VERSION ""

NS_ :

BS_:

BU_: WPC2 PSB SHVU_RR vHS_B2 FCS EMCU SLB GW_APSU GW_DLBCU ARS RCM CGW_CCU vDummy_HS_B GW_RLPSU ATS RLHV SGU PFSU GW_RRPSU ALBCU DSAU SWRC SHVU_FR RCS GW_DPSU BLTN_CAM SCM OHCL RWPC RRHV WPC HOD ASAU

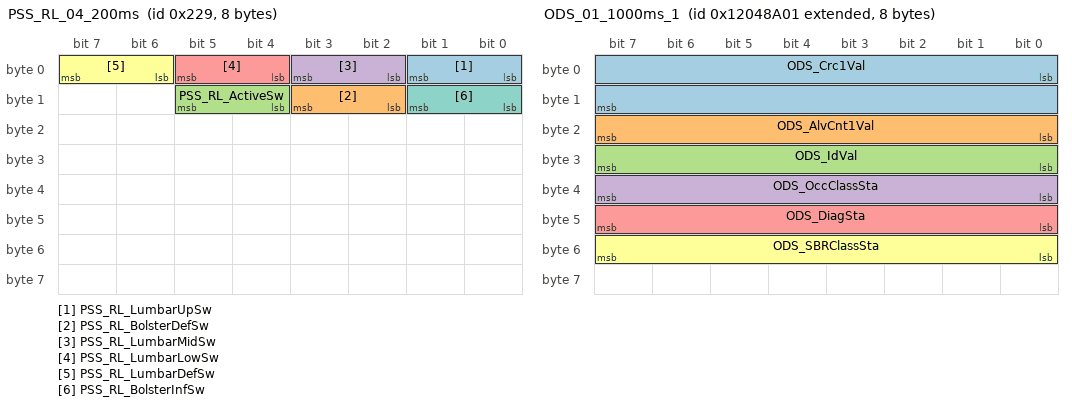
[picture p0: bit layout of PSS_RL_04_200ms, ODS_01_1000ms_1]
BO_ 553 PSS_RL_04_200ms: 8 GW_RLPSU
 SG_ PSS_RL_LumbarUpSw : 0|2@1+ (1,0) [0|0] ""  DSAU,GW_DLBCU,CGW_CCU
 SG_ PSS_RL_BolsterDefSw : 10|2@1+ (1,0) [0|0] ""  DSAU,GW_DLBCU,CGW_CCU
 SG_ PSS_RL_ActiveSw : 12|2@1+ (1,0) [0|0] ""  DSAU,GW_DLBCU,CGW_CCU
 SG_ PSS_RL_LumbarMidSw : 2|2@1+ (1,0) [0|0] ""  DSAU,GW_DLBCU,CGW_CCU
 SG_ PSS_RL_LumbarLowSw : 4|2@1+ (1,0) [0|0] ""  DSAU,GW_DLBCU,CGW_CCU
 SG_ PSS_RL_LumbarDefSw : 6|2@1+ (1,0) [0|0] ""  DSAU,GW_DLBCU,CGW_CCU
 SG_ PSS_RL_BolsterInfSw : 8|2@1+ (1,0) [0|0] ""  DSAU,GW_DLBCU,CGW_CCU

BO_ 2449771009 ODS_01_1000ms_1: 8 CGW_CCU
 SG_ ODS_Crc1Val : 0|16@1+ (1,0) [0|0] ""  Vector__XXX
 SG_ ODS_AlvCnt1Val : 16|8@1+ (1,0) [0|0] ""  Vector__XXX
 SG_ ODS_IdVal : 24|8@1+ (1,0) [0|0] ""  Vector__XXX
 SG_ ODS_OccClassSta : 32|8@1+ (1,0) [0|0] ""  ATS,GW_APSU,GW_DPSU
 SG_ ODS_DiagSta : 40|8@1+ (1,0) [0|0] ""  Vector__XXX
 SG_ ODS_SBRClassSta : 48|8@1+ (1,0) [0|0] ""  Vector__XXX

BO_ 2449771010 ODS_01_1000ms_2: 8 CGW_CCU

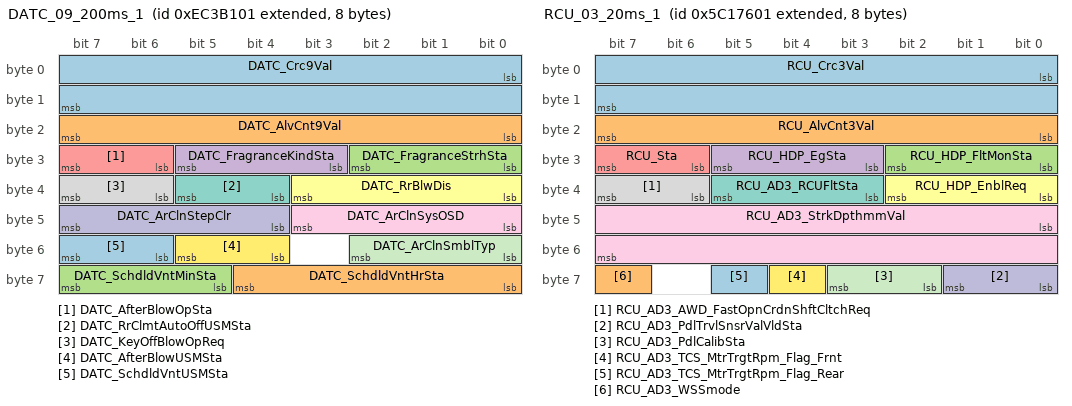
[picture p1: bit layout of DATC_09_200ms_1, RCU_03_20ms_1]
BO_ 2395189505 DATC_09_200ms_1: 8 CGW_CCU
 SG_ DATC_Crc9Val : 0|16@1+ (1,0) [0|0] ""  Vector__XXX
 SG_ DATC_AlvCnt9Val : 16|8@1+ (1,0) [0|0] ""  Vector__XXX
 SG_ DATC_FragranceStrhSta : 24|3@1+ (1,0) [0|0] ""  ATS
 SG_ DATC_FragranceKindSta : 27|3@1+ (1,0) [0|0] ""  ATS
 SG_ DATC_AfterBlowOpSta : 30|2@1+ (1,0) [0|0] ""  Vector__XXX
 SG_ DATC_RrBlwDis : 32|4@1+ (1,0) [0|0] ""  ATS
 SG_ DATC_RrClmtAutoOffUSMSta : 36|2@1+ (1,0) [0|0] ""  Vector__XXX
 SG_ DATC_KeyOffBlowOpReq : 38|2@1+ (1,0) [0|0] ""  Vector__XXX
 SG_ DATC_ArClnSysOSD : 40|4@1+ (1,0) [0|0] ""  Vector__XXX
 SG_ DATC_ArClnStepClr : 44|4@1+ (1,0) [0|0] ""  ATS
 SG_ DATC_ArClnSmblTyp : 48|3@1+ (1,0) [0|0] ""  ATS
 SG_ DATC_AfterBlowUSMSta : 52|2@1+ (1,0) [0|0] ""  Vector__XXX
 SG_ DATC_SchdldVntUSMSta : 54|2@1+ (1,0) [0|0] ""  Vector__XXX
 SG_ DATC_SchdldVntHrSta : 56|5@1+ (1,0) [0|0] ""  Vector__XXX
 SG_ DATC_SchdldVntMinSta : 61|3@1+ (1,0) [0|0] ""  Vector__XXX

BO_ 2244048387 RCU_03_20ms_3: 8 CGW_CCU
 SG_ RCU_AD3_SCC_TqIntrvntnVal : 0|8@1+ (0.390625,0) [0|0] "%"  Vector__XXX
 SG_ RCU_AD3_TCS_TqFlag : 19|1@1+ (1,0) [0|0] ""  Vector__XXX
 SG_ RCU_AD3_TCS_Sta : 20|4@1+ (1,0) [0|0] ""  Vector__XXX
 SG_ RCU_AD3_VehAccelVal : 24|11@1+ (0.01,-10.23) [0|0] "m/s^2"  Vector__XXX
 SG_ RCU_AD3_MSR_TqFlag : 35|1@1+ (1,0) [0|0] ""  Vector__XXX
 SG_ RCU_AD3_LDM_Sta : 36|2@1+ (1,0) [0|0] ""  Vector__XXX
 SG_ RCU_AD3_ECD_ActvSta : 38|2@1+ (1,0) [0|0] ""  Vector__XXX
 SG_ RCU_AD3_MSR_FuncReq : 40|2@1+ (1,0) [0|0] ""  Vector__XXX
 SG_ RCU_AD3_TCS_Req : 42|2@1+ (1,0) [0|0] ""  Vector__XXX
 SG_ RCU_AD3_TCS_LmpSta : 44|2@1+ (1,0) [0|0] ""  Vector__XXX
 SG_ RCU_AD3_SCC_TqReq : 46|2@1+ (1,0) [0|0] ""  Vector__XXX
 SG_ RCU_AD3_StdStillVal : 48|2@1+ (1,0) [0|0] ""  Vector__XXX
 SG_ RCU_AD3_SCC_ReqLimSta : 50|2@1+ (1,0) [0|0] ""  Vector__XXX
 SG_ RCU_AD3_SCC_OptTyp : 52|2@1+ (1,0) [0|0] ""  Vector__XXX
 SG_ RCU_AD3_SCC_EnblReq : 54|2@1+ (1,0) [0|0] ""  Vector__XXX
 SG_ RCU_AD3_FCA_EquipSta : 56|2@1+ (1,0) [0|0] ""  Vector__XXX
 SG_ RCU_AD3_FCA_ActvSta : 58|2@1+ (1,0) [0|0] ""  Vector__XXX
 SG_ RCU_AD3_DclEnblReq : 60|2@1+ (1,0) [0|0] ""  Vector__XXX
 SG_ RCU_AD3_DBS_ActvSta : 62|2@1+ (1,0) [0|0] ""  Vector__XXX
 SG_ RCU_AD3_AccelBasisVal : 8|11@1+ (0.01,-10.23) [0|0] "m/s^2"  Vector__XXX

BO_ 2244048386 RCU_03_20ms_2: 8 CGW_CCU
 SG_ RCU_AD3_Wss2FlFltSta : 0|2@1+ (1,0) [0|0] ""  Vector__XXX
 SG_ RCU_AD3_DiagSta : 10|2@1+ (1,0) [0|0] ""  Vector__XXX
 SG_ RCU_AD3_operation : 12|2@1+ (1,0) [0|0] ""  Vector__XXX
 SG_ RCU_AD3_PrsrValVldSta : 14|2@1+ (1,0) [0|0] ""  Vector__XXX
 SG_ RCU_AD3_PrsrVal : 16|16@1- (0.01,-30) [0|0] "Bar"  Vector__XXX
 SG_ RCU_AD3_Wss2FrFltSta : 2|2@1+ (1,0) [0|0] ""  Vector__XXX
 SG_ RCU_AD3_ABS_DfctvSta : 32|2@1+ (1,0) [0|0] ""  Vector__XXX
 SG_ RCU_AD3_ABS_ActvSta : 34|2@1+ (1,0) [0|0] ""  Vector__XXX
 SG_ RCU_AD3_BBC_DfctvSta : 36|2@1+ (1,0) [0|0] ""  Vector__XXX
 SG_ RCU_AD3_BBC_ActvSta : 38|2@1+ (1,0) [0|0] ""  Vector__XXX
 SG_ RCU_AD3_Wss2RlFltSta : 4|2@1+ (1,0) [0|0] ""  Vector__XXX
 SG_ RCU_AD3_BrkLtActSta : 40|2@1+ (1,0) [0|0] ""  Vector__XXX
 SG_ RCU_AD3_DrvOvrdSta : 42|2@1+ (1,0) [0|0] ""  Vector__XXX
 SG_ RCU_AD3_PrkBrkActvSta : 44|2@1+ (1,0) [0|0] ""  Vector__XXX
 SG_ RCU_AD3_FCA_AvlblSta : 46|2@1+ (1,0) [0|0] ""  Vector__XXX
 SG_ RCU_AD3_MSR_TqIntrvntnVal : 48|8@1+ (0.390625,0) [0|0] "%"  Vector__XXX
 SG_ RCU_AD3_TCS_TqIntrvntnVal : 56|8@1+ (0.390625,0) [0|0] "%"  Vector__XXX
 SG_ RCU_AD3_Wss2RrFltSta : 6|2@1+ (1,0) [0|0] ""  Vector__XXX
 SG_ RCU_AD3_SrvLmpDis : 8|2@1+ (1,0) [0|0] ""  Vector__XXX

BO_ 2244048385 RCU_03_20ms_1: 8 CGW_CCU
 SG_ RCU_Crc3Val : 0|16@1+ (1,0) [0|0] ""  Vector__XXX
 SG_ RCU_AlvCnt3Val : 16|8@1+ (1,0) [0|0] ""  Vector__XXX
 SG_ RCU_HDP_FltMonSta : 24|3@1+ (1,0) [0|0] ""  Vector__XXX
 SG_ RCU_HDP_EgSta : 27|3@1+ (1,0) [0|0] ""  PSB
 SG_ RCU_Sta : 30|2@1+ (1,0) [0|0] ""  Vector__XXX
 SG_ RCU_HDP_EnblReq : 32|3@1+ (1,0) [0|0] ""  Vector__XXX
 SG_ RCU_AD3_RCUFltSta : 35|3@1+ (1,0) [0|0] ""  Vector__XXX
 SG_ RCU_AD3_AWD_FastOpnCrdnShftCltchReq : 38|2@1+ (1,0) [0|0] ""  Vector__XXX
 SG_ RCU_AD3_StrkDpthmmVal : 40|16@1- (0.1,-40) [0|0] "mm"  Vector__XXX
 SG_ RCU_AD3_PdlTrvlSnsrValVldSta : 56|2@1+ (1,0) [0|0] ""  Vector__XXX
 SG_ RCU_AD3_PdlCalibSta : 58|2@1+ (1,0) [0|0] ""  Vector__XXX
 SG_ RCU_AD3_TCS_MtrTrgtRpm_Flag_Frnt : 60|1@1+ (1,0) [0|0] ""  Vector__XXX
 SG_ RCU_AD3_TCS_MtrTrgtRpm_Flag_Rear : 61|1@1+ (1,0) [0|0] ""  Vector__XXX
 SG_ RCU_AD3_WSSmode : 63|1@1+ (1,0) [0|0] ""  Vector__XXX

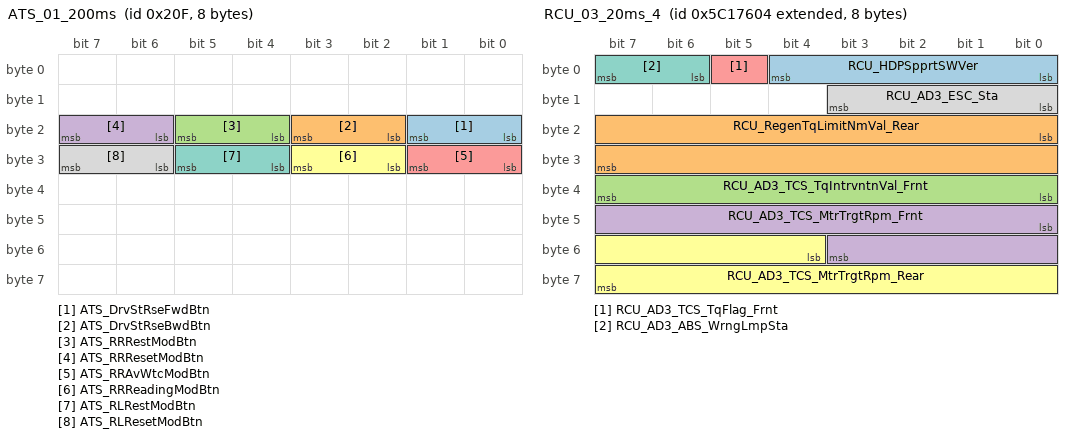
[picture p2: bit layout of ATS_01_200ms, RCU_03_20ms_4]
BO_ 527 ATS_01_200ms: 8 ATS
 SG_ ATS_DrvStRseFwdBtn : 16|2@1+ (1,0) [0|0] ""  Vector__XXX
 SG_ ATS_DrvStRseBwdBtn : 18|2@1+ (1,0) [0|0] ""  Vector__XXX
 SG_ ATS_RRRestModBtn : 20|2@1+ (1,0) [0|0] ""  Vector__XXX
 SG_ ATS_RRResetModBtn : 22|2@1+ (1,0) [0|0] ""  Vector__XXX
 SG_ ATS_RRAvWtcModBtn : 24|2@1+ (1,0) [0|0] ""  Vector__XXX
 SG_ ATS_RRReadingModBtn : 26|2@1+ (1,0) [0|0] ""  Vector__XXX
 SG_ ATS_RLRestModBtn : 28|2@1+ (1,0) [0|0] ""  Vector__XXX
 SG_ ATS_RLResetModBtn : 30|2@1+ (1,0) [0|0] ""  Vector__XXX

BO_ 2244048388 RCU_03_20ms_4: 8 CGW_CCU
 SG_ RCU_HDPSpprtSWVer : 0|5@1+ (1,0) [0|0] ""  Vector__XXX
 SG_ RCU_RegenTqLimitNmVal_Rear : 16|16@1+ (1,0) [0|0] "Nm"  Vector__XXX
 SG_ RCU_AD3_TCS_TqIntrvntnVal_Frnt : 32|8@1+ (0.390625,0) [0|0] "%"  Vector__XXX
 SG_ RCU_AD3_TCS_MtrTrgtRpm_Frnt : 40|12@1+ (8,0) [0|0] "rpm"  Vector__XXX
 SG_ RCU_AD3_TCS_TqFlag_Frnt : 5|1@1+ (1,0) [0|0] ""  Vector__XXX
 SG_ RCU_AD3_TCS_MtrTrgtRpm_Rear : 52|12@1+ (8,0) [0|0] "rpm"  Vector__XXX
 SG_ RCU_AD3_ABS_WrngLmpSta : 6|2@1+ (1,0) [0|0] ""  Vector__XXX
 SG_ RCU_AD3_ESC_Sta : 8|4@1+ (1,0) [0|0] ""  Vector__XXX

BO_ 1616 MKBD_HU_E_01: 8 CGW_CCU
 SG_ MKBD_IllumiState : 48|2@1+ (1,0) [0|0] ""  Vector__XXX
 SG_ MKBD_SeatKeySet : 50|2@1+ (1,0) [0|0] ""  GW_APSU,GW_DPSU,SHVU_FR

BO_ 543 ATS_02_200ms: 8 ATS
 SG_ ATS_AstStSldFwdBtn : 16|2@1+ (1,0) [0|0] ""  Vector__XXX
 SG_ ATS_AstStSldBwdBtn : 18|2@1+ (1,0) [0|0] ""  Vector__XXX
 SG_ ATS_AstStRclFwdBtn : 20|2@1+ (1,0) [0|0] ""  Vector__XXX
 SG_ ATS_AstStRclBwdBtn : 22|2@1+ (1,0) [0|0] ""  Vector__XXX
 SG_ ATS_AstStHgtUpBtn : 28|2@1+ (1,0) [0|0] ""  Vector__XXX
 SG_ ATS_AstStHgtDnBtn : 30|2@1+ (1,0) [0|0] ""  Vector__XXX
 SG_ ATS_AstStHRestUpBtn : 40|2@1+ (1,0) [0|0] ""  Vector__XXX
 SG_ ATS_AstStHRestDnBtn : 42|2@1+ (1,0) [0|0] ""  Vector__XXX
 SG_ ATS_AstStHRestFwdBtn : 44|2@1+ (1,0) [0|0] ""  Vector__XXX
 SG_ ATS_AstStHRestBwdBtn : 46|2@1+ (1,0) [0|0] ""  Vector__XXX
 SG_ ATS_AstStHRestFldBtn : 48|2@1+ (1,0) [0|0] ""  Vector__XXX
 SG_ ATS_AstStHRestUnFldBtn : 50|2@1+ (1,0) [0|0] ""  Vector__XXX
 SG_ ATS_AstStRseFwdBtn : 52|2@1+ (1,0) [0|0] ""  Vector__XXX
 SG_ ATS_AstStRseBwdBtn : 54|2@1+ (1,0) [0|0] ""  Vector__XXX
 SG_ ATS_AstStFRestFldBtn : 56|2@1+ (1,0) [0|0] ""  Vector__XXX
 SG_ ATS_AstStFRestUnFldBtn : 58|2@1+ (1,0) [0|0] ""  Vector__XXX
 SG_ ATS_AstTltUpBtn : 60|2@1+ (1,0) [0|0] ""  Vector__XXX
 SG_ ATS_AstTltDnBtn : 62|2@1+ (1,0) [0|0] ""  Vector__XXX

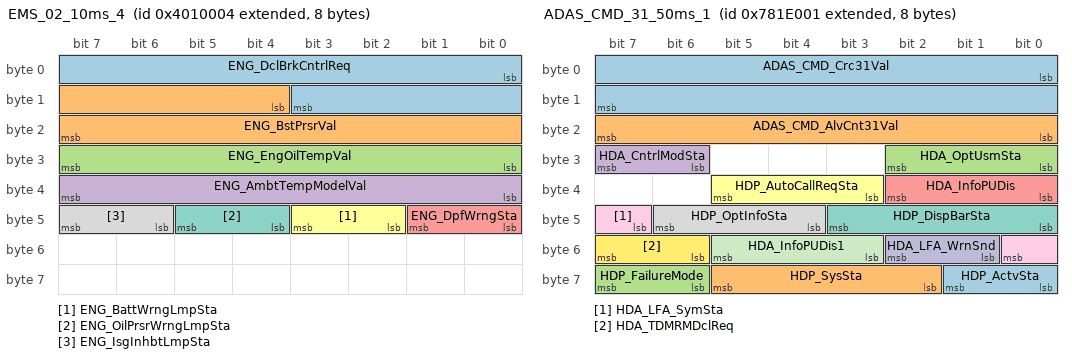
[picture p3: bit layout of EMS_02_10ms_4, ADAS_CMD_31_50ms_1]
BO_ 2214658052 EMS_02_10ms_4: 8 CGW_CCU
 SG_ ENG_DclBrkCntrlReq : 0|12@1+ (0.001,-4.094) [0|0] "m/s^2"  Vector__XXX
 SG_ ENG_BstPrsrVal : 12|12@1+ (1.322,0) [0|0] "hPa"  Vector__XXX
 SG_ ENG_EngOilTempVal : 24|8@1+ (0.75,-40) [0|0] "¡É"  Vector__XXX
 SG_ ENG_AmbtTempModelVal : 32|8@1+ (0.5,-41) [0|0] "¡É"  Vector__XXX
 SG_ ENG_DpfWrngSta : 40|2@1+ (1,0) [0|0] ""  Vector__XXX
 SG_ ENG_BattWrngLmpSta : 42|2@1+ (1,0) [0|0] ""  Vector__XXX
 SG_ ENG_OilPrsrWrngLmpSta : 44|2@1+ (1,0) [0|0] ""  Vector__XXX
 SG_ ENG_IsgInhbtLmpSta : 46|2@1+ (1,0) [0|0] ""  FCS

BO_ 2273435649 ADAS_CMD_31_50ms_1: 8 CGW_CCU
 SG_ ADAS_CMD_Crc31Val : 0|16@1+ (1,0) [0|0] ""  Vector__XXX
 SG_ ADAS_CMD_AlvCnt31Val : 16|8@1+ (1,0) [0|0] ""  Vector__XXX
 SG_ HDA_OptUsmSta : 24|3@1+ (1,0) [0|0] ""  Vector__XXX
 SG_ HDA_CntrlModSta : 30|2@1+ (1,0) [0|0] ""  Vector__XXX
 SG_ HDA_InfoPUDis : 32|3@1+ (1,0) [0|0] ""  Vector__XXX
 SG_ HDP_AutoCallReqSta : 35|3@1+ (1,0) [0|0] ""  Vector__XXX
 SG_ HDP_DispBarSta : 40|4@1+ (1,0) [0|0] ""  Vector__XXX
 SG_ HDP_OptInfoSta : 44|3@1+ (1,0) [0|0] ""  Vector__XXX
 SG_ HDA_LFA_SymSta : 47|2@1+ (1,0) [0|0] ""  Vector__XXX
 SG_ HDA_LFA_WrnSnd : 49|2@1+ (1,0) [0|0] ""  Vector__XXX
 SG_ HDA_InfoPUDis1 : 51|3@1+ (1,0) [0|0] ""  Vector__XXX
 SG_ HDA_TDMRMDclReq : 54|2@1+ (1,0) [0|0] ""  Vector__XXX
 SG_ HDP_ActvSta : 56|2@1+ (1,0) [0|0] ""  PSB
 SG_ HDP_SysSta : 58|4@1+ (1,0) [0|0] ""  HOD
 SG_ HDP_FailureMode : 62|2@1+ (1,0) [0|0] ""  Vector__XXX

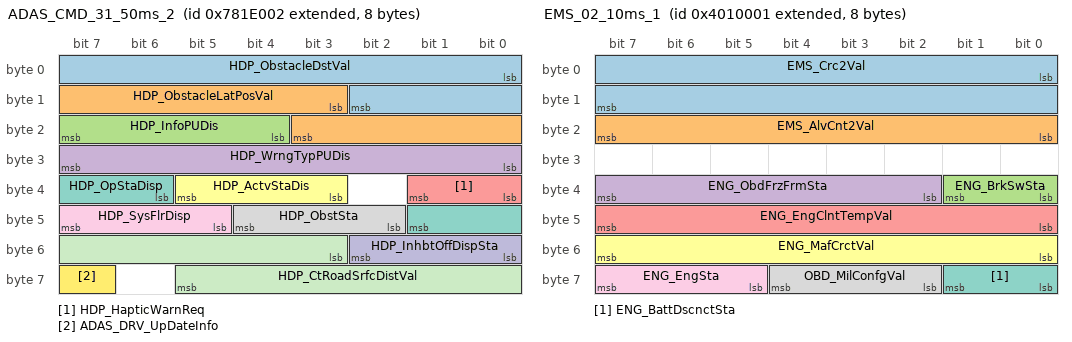
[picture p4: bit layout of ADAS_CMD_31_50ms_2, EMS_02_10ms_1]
BO_ 2273435650 ADAS_CMD_31_50ms_2: 8 CGW_CCU
 SG_ HDP_ObstacleDstVal : 0|11@1+ (0.1,0) [0|0] "m"  Vector__XXX
 SG_ HDP_ObstacleLatPosVal : 11|9@1+ (0.1,-20) [0|0] "m"  Vector__XXX
 SG_ HDP_InfoPUDis : 20|4@1+ (1,0) [0|0] ""  Vector__XXX
 SG_ HDP_WrngTypPUDis : 24|8@1+ (1,0) [0|0] ""  Vector__XXX
 SG_ HDP_HapticWarnReq : 32|2@1+ (1,0) [0|0] ""  PSB
 SG_ HDP_ActvStaDis : 35|3@1+ (1,0) [0|0] ""  Vector__XXX
 SG_ HDP_OpStaDisp : 38|4@1+ (1,0) [0|0] ""  Vector__XXX
 SG_ HDP_ObstSta : 42|3@1+ (1,0) [0|0] ""  Vector__XXX
 SG_ HDP_SysFlrDisp : 45|3@1+ (1,0) [0|0] ""  Vector__XXX
 SG_ HDP_InhbtOffDispSta : 48|3@1+ (1,0) [0|0] ""  Vector__XXX
 SG_ HDP_CtRoadSrfcDistVal : 51|11@1+ (1,0) [0|0] ""  Vector__XXX
 SG_ ADAS_DRV_UpDateInfo : 63|1@1+ (1,0) [0|0] ""  Vector__XXX

BO_ 2214658049 EMS_02_10ms_1: 8 CGW_CCU
 SG_ EMS_Crc2Val : 0|16@1+ (1,0) [0|0] ""  Vector__XXX
 SG_ EMS_AlvCnt2Val : 16|8@1+ (1,0) [0|0] ""  Vector__XXX
 SG_ ENG_BrkSwSta : 32|2@1+ (1,0) [0|0] ""  BLTN_CAM
 SG_ ENG_ObdFrzFrmSta : 34|6@1+ (1,0) [0|0] ""  Vector__XXX
 SG_ ENG_EngClntTempVal : 40|8@1+ (0.75,-48) [0|0] "¡É"  Vector__XXX
 SG_ ENG_MafCrctVal : 48|8@1+ (0.00781,0) [0|0] ""  Vector__XXX
 SG_ ENG_BattDscnctSta : 56|2@1+ (1,0) [0|0] ""  Vector__XXX
 SG_ OBD_MilConfgVal : 58|3@1+ (1,0) [0|0] ""  Vector__XXX
 SG_ ENG_EngSta : 61|3@1+ (1,0) [0|0] ""  BLTN_CAM,EMCU,GW_APSU,GW_DLBCU,GW_DPSU,GW_RLPSU,GW_RRPSU,HOD,PFSU,PSB,RCM,RLHV,RRHV,RWPC,SCM,SHVU_FR,SHVU_RR,SWRC,WPC,WPC2

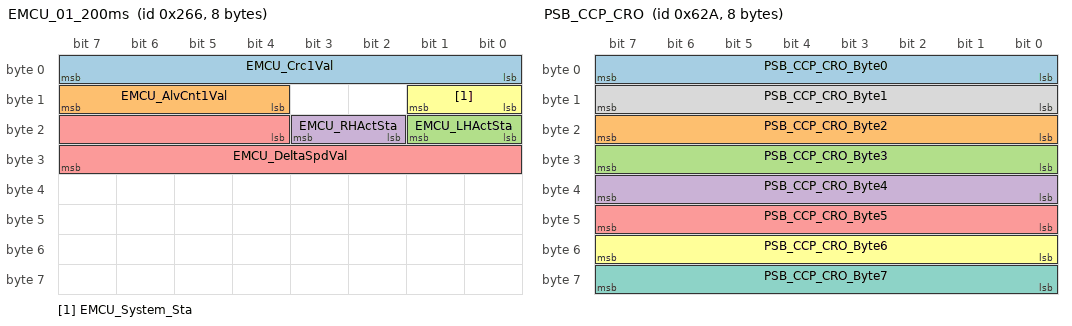
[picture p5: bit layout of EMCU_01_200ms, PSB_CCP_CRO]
BO_ 614 EMCU_01_200ms: 8 EMCU
 SG_ EMCU_Crc1Val : 0|8@1+ (1,0) [0|0] ""  Vector__XXX
 SG_ EMCU_AlvCnt1Val : 12|4@1+ (1,0) [0|0] ""  Vector__XXX
 SG_ EMCU_LHActSta : 16|2@1+ (1,0) [0|0] ""  Vector__XXX
 SG_ EMCU_RHActSta : 18|2@1+ (1,0) [0|0] ""  Vector__XXX
 SG_ EMCU_DeltaSpdVal : 20|12@1+ (0.01,0) [0|0] ""  Vector__XXX
 SG_ EMCU_System_Sta : 8|2@1+ (1,0) [0|0] ""  Vector__XXX

BO_ 1578 PSB_CCP_CRO: 8 CGW_CCU
 SG_ PSB_CCP_CRO_Byte0 : 0|8@1+ (1,0) [0|0] ""  PSB
 SG_ PSB_CCP_CRO_Byte2 : 16|8@1+ (1,0) [0|0] ""  PSB
 SG_ PSB_CCP_CRO_Byte3 : 24|8@1+ (1,0) [0|0] ""  PSB
 SG_ PSB_CCP_CRO_Byte4 : 32|8@1+ (1,0) [0|0] ""  PSB
 SG_ PSB_CCP_CRO_Byte5 : 40|8@1+ (1,0) [0|0] ""  PSB
 SG_ PSB_CCP_CRO_Byte6 : 48|8@1+ (1,0) [0|0] ""  PSB
 SG_ PSB_CCP_CRO_Byte7 : 56|8@1+ (1,0) [0|0] ""  PSB
 SG_ PSB_CCP_CRO_Byte1 : 8|8@1+ (1,0) [0|0] ""  PSB

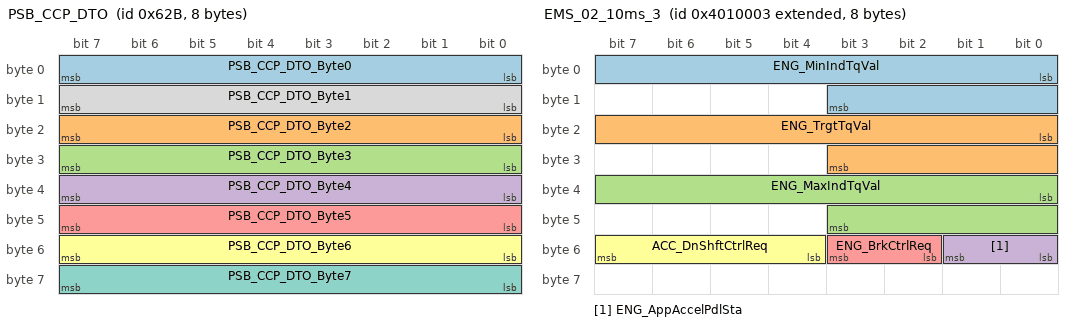
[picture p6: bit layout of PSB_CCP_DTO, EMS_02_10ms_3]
BO_ 1579 PSB_CCP_DTO: 8 PSB
 SG_ PSB_CCP_DTO_Byte0 : 0|8@1+ (1,0) [0|0] ""  CGW_CCU
 SG_ PSB_CCP_DTO_Byte2 : 16|8@1+ (1,0) [0|0] ""  CGW_CCU
 SG_ PSB_CCP_DTO_Byte3 : 24|8@1+ (1,0) [0|0] ""  CGW_CCU
 SG_ PSB_CCP_DTO_Byte4 : 32|8@1+ (1,0) [0|0] ""  CGW_CCU
 SG_ PSB_CCP_DTO_Byte5 : 40|8@1+ (1,0) [0|0] ""  CGW_CCU
 SG_ PSB_CCP_DTO_Byte6 : 48|8@1+ (1,0) [0|0] ""  CGW_CCU
 SG_ PSB_CCP_DTO_Byte7 : 56|8@1+ (1,0) [0|0] ""  CGW_CCU
 SG_ PSB_CCP_DTO_Byte1 : 8|8@1+ (1,0) [0|0] ""  CGW_CCU

BO_ 2214658051 EMS_02_10ms_3: 8 CGW_CCU
 SG_ ENG_MinIndTqVal : 0|12@1- (1,0) [0|0] "Nm"  Vector__XXX
 SG_ ENG_TrgtTqVal : 16|12@1- (1,0) [0|0] "Nm"  Vector__XXX
 SG_ ENG_MaxIndTqVal : 32|12@1- (1,0) [0|0] "Nm"  Vector__XXX
 SG_ ENG_AppAccelPdlSta : 48|2@1+ (1,0) [0|0] ""  Vector__XXX
 SG_ ENG_BrkCtrlReq : 50|2@1+ (1,0) [0|0] ""  Vector__XXX
 SG_ ACC_DnShftCtrlReq : 52|4@1+ (1,0) [0|0] ""  Vector__XXX

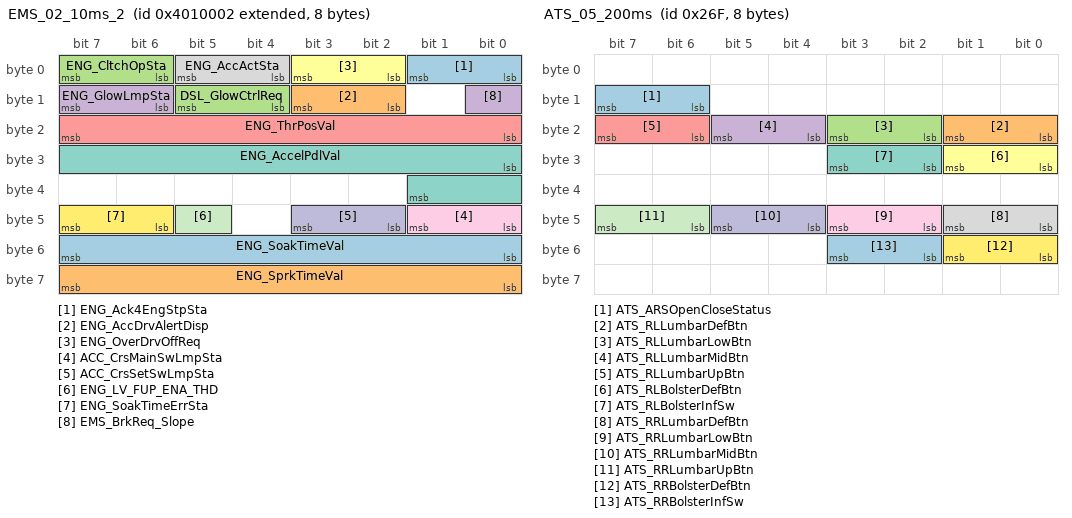
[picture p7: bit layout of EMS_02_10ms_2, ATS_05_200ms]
BO_ 2214658050 EMS_02_10ms_2: 8 CGW_CCU
 SG_ ENG_Ack4EngStpSta : 0|2@1+ (1,0) [0|0] ""  Vector__XXX
 SG_ ENG_AccDrvAlertDisp : 10|2@1+ (1,0) [0|0] ""  Vector__XXX
 SG_ DSL_GlowCtrlReq : 12|2@1+ (1,0) [0|0] ""  Vector__XXX
 SG_ ENG_GlowLmpSta : 14|2@1+ (1,0) [0|0] ""  Vector__XXX
 SG_ ENG_ThrPosVal : 16|8@1+ (0.4694836,-15.0234742) [0|0] "%"  Vector__XXX
 SG_ ENG_OverDrvOffReq : 2|2@1+ (1,0) [0|0] ""  Vector__XXX
 SG_ ENG_AccelPdlVal : 24|10@1+ (0.09784,0) [0|0] "%"  BLTN_CAM,EMCU
 SG_ ENG_AccActSta : 4|2@1+ (1,0) [0|0] ""  Vector__XXX
 SG_ ACC_CrsMainSwLmpSta : 40|2@1+ (1,0) [0|0] ""  Vector__XXX
 SG_ ACC_CrsSetSwLmpSta : 42|2@1+ (1,0) [0|0] ""  Vector__XXX
 SG_ ENG_LV_FUP_ENA_THD : 45|1@1+ (1,0) [0|0] ""  Vector__XXX
 SG_ ENG_SoakTimeErrSta : 46|2@1+ (1,0) [0|0] ""  Vector__XXX
 SG_ ENG_SoakTimeVal : 48|8@1+ (1,0) [0|0] "Min"  Vector__XXX
 SG_ ENG_SprkTimeVal : 56|8@1+ (0.375,-35.625) [0|0] "¢ª"  Vector__XXX
 SG_ ENG_CltchOpSta : 6|2@1+ (1,0) [0|0] ""  Vector__XXX
 SG_ EMS_BrkReq_Slope : 8|1@1+ (1,0) [0|0] ""  Vector__XXX

BO_ 623 ATS_05_200ms: 8 ATS
 SG_ ATS_ARSOpenCloseStatus : 14|2@1+ (1,0) [0|0] ""  Vector__XXX
 SG_ ATS_RLLumbarDefBtn : 16|2@1+ (1,0) [0|0] ""  Vector__XXX
 SG_ ATS_RLLumbarLowBtn : 18|2@1+ (1,0) [0|0] ""  Vector__XXX
 SG_ ATS_RLLumbarMidBtn : 20|2@1+ (1,0) [0|0] ""  Vector__XXX
 SG_ ATS_RLLumbarUpBtn : 22|2@1+ (1,0) [0|0] ""  Vector__XXX
 SG_ ATS_RLBolsterDefBtn : 24|2@1+ (1,0) [0|0] ""  Vector__XXX
 SG_ ATS_RLBolsterInfSw : 26|2@1+ (1,0) [0|0] ""  Vector__XXX
 SG_ ATS_RRLumbarDefBtn : 40|2@1+ (1,0) [0|0] ""  Vector__XXX
 SG_ ATS_RRLumbarLowBtn : 42|2@1+ (1,0) [0|0] ""  Vector__XXX
 SG_ ATS_RRLumbarMidBtn : 44|2@1+ (1,0) [0|0] ""  Vector__XXX
 SG_ ATS_RRLumbarUpBtn : 46|2@1+ (1,0) [0|0] ""  Vector__XXX
 SG_ ATS_RRBolsterDefBtn : 48|2@1+ (1,0) [0|0] ""  Vector__XXX
 SG_ ATS_RRBolsterInfSw : 50|2@1+ (1,0) [0|0] ""  Vector__XXX

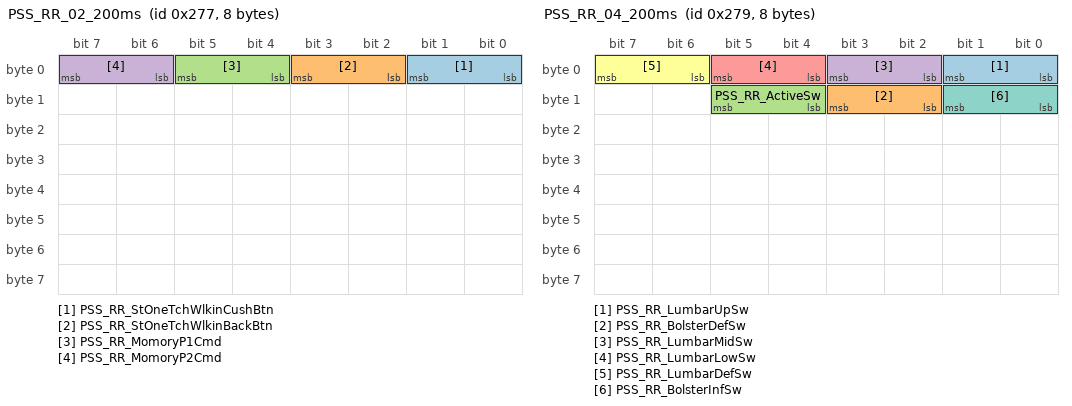
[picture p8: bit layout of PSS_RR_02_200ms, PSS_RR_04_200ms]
BO_ 631 PSS_RR_02_200ms: 8 GW_RRPSU
 SG_ PSS_RR_StOneTchWlkinCushBtn : 0|2@1+ (1,0) [0|0] ""  CGW_CCU
 SG_ PSS_RR_StOneTchWlkinBackBtn : 2|2@1+ (1,0) [0|0] ""  CGW_CCU
 SG_ PSS_RR_MomoryP1Cmd : 4|2@1+ (1,0) [0|0] ""  CGW_CCU
 SG_ PSS_RR_MomoryP2Cmd : 6|2@1+ (1,0) [0|0] ""  CGW_CCU

BO_ 630 PSS_RR_01_200ms: 8 GW_RRPSU
 SG_ PSS_RR_StSldFwdMvBtn : 0|2@1+ (1,0) [0|0] ""  CGW_CCU
 SG_ PSS_RR_StTltDnMvBtn : 10|2@1+ (1,0) [0|0] ""  CGW_CCU
 SG_ PSS_RR_StHRestUpMvBtn : 12|2@1+ (1,0) [0|0] ""  CGW_CCU
 SG_ PSS_RR_StHRestDnMvBtn : 14|2@1+ (1,0) [0|0] ""  CGW_CCU
 SG_ PSS_RR_StHRestFwdMvBtn : 16|2@1+ (1,0) [0|0] ""  CGW_CCU
 SG_ PSS_RR_StHRestBwdMvBtn : 18|2@1+ (1,0) [0|0] ""  CGW_CCU
 SG_ PSS_RR_StSldBwdMvBtn : 2|2@1+ (1,0) [0|0] ""  CGW_CCU
 SG_ PSS_RR_StLegRestUpBtn : 20|2@1+ (1,0) [0|0] ""  CGW_CCU
 SG_ PSS_RR_StLegRestDnBtn : 22|2@1+ (1,0) [0|0] ""  CGW_CCU
 SG_ PSS_RR_StLegRestExtFwdBtn : 24|2@1+ (1,0) [0|0] ""  CGW_CCU
 SG_ PSS_RR_StLegRestExtBwdBtn : 26|2@1+ (1,0) [0|0] ""  CGW_CCU
 SG_ PSS_RR_StRlxModeBtn : 28|2@1+ (1,0) [0|0] ""  CGW_CCU
 SG_ PSS_RR_StRlxReturnBtn : 30|2@1+ (1,0) [0|0] ""  CGW_CCU
 SG_ PSS_RR_StRlxTltUpMvBtn : 32|2@1+ (1,0) [0|0] ""  CGW_CCU
 SG_ PSS_RR_StRlxTltDnMvBtn : 34|2@1+ (1,0) [0|0] ""  CGW_CCU
 SG_ PSS_RR_StMnlRlxModeBtn : 36|2@1+ (1,0) [0|0] ""  CGW_CCU
 SG_ PSS_RR_StMnlRlxReturnBtn : 38|2@1+ (1,0) [0|0] ""  CGW_CCU
 SG_ PSS_RR_StRclFwdMvBtn : 4|2@1+ (1,0) [0|0] ""  CGW_CCU
 SG_ PSS_RR_WalkInSwitchSts : 40|2@1+ (1,0) [0|0] ""  CGW_CCU
 SG_ PSS_RR_StRclBwdMvBtn : 6|2@1+ (1,0) [0|0] ""  CGW_CCU
 SG_ PSS_RR_StTltUpMvBtn : 8|2@1+ (1,0) [0|0] ""  CGW_CCU

BO_ 633 PSS_RR_04_200ms: 8 GW_RRPSU
 SG_ PSS_RR_LumbarUpSw : 0|2@1+ (1,0) [0|0] ""  DSAU,GW_DLBCU,CGW_CCU
 SG_ PSS_RR_BolsterDefSw : 10|2@1+ (1,0) [0|0] ""  DSAU,GW_DLBCU,CGW_CCU
 SG_ PSS_RR_ActiveSw : 12|2@1+ (1,0) [0|0] ""  DSAU,GW_DLBCU,CGW_CCU
 SG_ PSS_RR_LumbarMidSw : 2|2@1+ (1,0) [0|0] ""  DSAU,GW_DLBCU,CGW_CCU
 SG_ PSS_RR_LumbarLowSw : 4|2@1+ (1,0) [0|0] ""  DSAU,GW_DLBCU,CGW_CCU
 SG_ PSS_RR_LumbarDefSw : 6|2@1+ (1,0) [0|0] ""  DSAU,GW_DLBCU,CGW_CCU
 SG_ PSS_RR_BolsterInfSw : 8|2@1+ (1,0) [0|0] ""  DSAU,GW_DLBCU,CGW_CCU

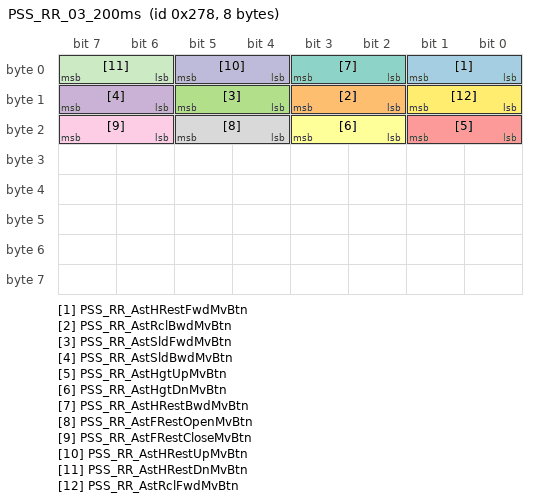
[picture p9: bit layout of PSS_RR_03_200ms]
BO_ 632 PSS_RR_03_200ms: 8 GW_RRPSU
 SG_ PSS_RR_AstHRestFwdMvBtn : 0|2@1+ (1,0) [0|0] ""  CGW_CCU
 SG_ PSS_RR_AstRclBwdMvBtn : 10|2@1+ (1,0) [0|0] ""  CGW_CCU
 SG_ PSS_RR_AstSldFwdMvBtn : 12|2@1+ (1,0) [0|0] ""  CGW_CCU
 SG_ PSS_RR_AstSldBwdMvBtn : 14|2@1+ (1,0) [0|0] ""  CGW_CCU
 SG_ PSS_RR_AstHgtUpMvBtn : 16|2@1+ (1,0) [0|0] ""  CGW_CCU
 SG_ PSS_RR_AstHgtDnMvBtn : 18|2@1+ (1,0) [0|0] ""  CGW_CCU
 SG_ PSS_RR_AstHRestBwdMvBtn : 2|2@1+ (1,0) [0|0] ""  CGW_CCU
 SG_ PSS_RR_AstFRestOpenMvBtn : 20|2@1+ (1,0) [0|0] ""  CGW_CCU
 SG_ PSS_RR_AstFRestCloseMvBtn : 22|2@1+ (1,0) [0|0] ""  CGW_CCU
 SG_ PSS_RR_AstHRestUpMvBtn : 4|2@1+ (1,0) [0|0] ""  CGW_CCU
 SG_ PSS_RR_AstHRestDnMvBtn : 6|2@1+ (1,0) [0|0] ""  CGW_CCU
 SG_ PSS_RR_AstRclFwdMvBtn : 8|2@1+ (1,0) [0|0] ""  CGW_CCU

CM_ BO_ 2273435649 "[P] Periodic";
CM_ SG_ 2273435649 ADAS_CMD_Crc31Val "ADAS_CMD_CyclicRedundancyCheck31Value";
CM_ SG_ 2273435649 ADAS_CMD_AlvCnt31Val "ADAS_CMD_AliveCounter31Value";
CM_ SG_ 2273435649 HDA_OptUsmSta "HDA_OptionUSMStatus ##2G##LDW_LKA - HDA11 - CF_HDA_Opt_USM";
CM_ SG_ 2273435649 HDA_CntrlModSta "HDA_ControlModeStatus ##2G##LDW_LKA - HDA11 - CF_HDA_Mode";
CM_ SG_ 2273435649 HDA_InfoPUDis "HDA_InformationPopUpDisplay ##2G##LDW_LKA - HDA11 - CF_HDA_InfoDisplay";
CM_ SG_ 2273435649 HDP_AutoCallReqSta "HDP Auto Call Request State";
CM_ SG_ 2273435649 HDP_DispBarSta "HDP Display Bar State";
CM_ SG_ 2273435649 HDP_OptInfoSta "HDP Option Infomation State";
CM_ SG_ 2273435649 HDA_LFA_SymSta "HDA_LFA_SymbolStatus ##2G##LDW_LKA - HDA11 - CF_HDA_LFA_SymbolState";
CM_ SG_ 2273435649 HDA_LFA_WrnSnd "HDA/LFA Additional Warning Sound";
CM_ SG_ 2273435649 HDA_InfoPUDis1 "HDA_InfomationPopupDisplay";
CM_ SG_ 2273435649 HDP_ActvSta "HDP_ControlActiveStatus";
CM_ SG_ 2273435649 HDP_SysSta "HDP_SystemStatus";
CM_ BO_ 2273435650 "[P] Periodic";
CM_ SG_ 2273435650 HDP_ObstacleDstVal "HDP_InPathObstacleDistance";
CM_ SG_ 2273435650 HDP_ObstacleLatPosVal "HDP_InPathObstaclePositionValue";
CM_ SG_ 2273435650 HDP_InfoPUDis "HDP_InformationPopupDisplay (main pop-up)";
CM_ SG_ 2273435650 HDP_WrngTypPUDis "HDP_WarningTypePopupDisplay (mini pop-up)";
CM_ SG_ 2273435650 HDP_HapticWarnReq "Request for HDP haptic warning";
CM_ SG_ 2273435650 HDP_ActvStaDis "HDP_Active/Deactive Status Display";
CM_ SG_ 2273435650 HDP_OpStaDisp "HDP Operation State Display";
CM_ SG_ 2273435650 HDP_ObstSta "HDP Obstacle State";
CM_ SG_ 2273435650 HDP_SysFlrDisp "HDP System Failure Display";
CM_ SG_ 2273435650 HDP_InhbtOffDispSta "HDP Inhibit Off Display State";
CM_ SG_ 2273435650 HDP_CtRoadSrfcDistVal "HDP Center Road Surface Distance Value";
CM_ SG_ 2273435650 ADAS_DRV_UpDateInfo "ADAS_DRV update state info";
CM_ BO_ 527 "[PE] Periodic and On Event";
CM_ SG_ 527 ATS_DrvStRseFwdBtn "Drive Seat  RSE Forward Touch Button";
CM_ SG_ 527 ATS_DrvStRseBwdBtn "Drive Seat  RSE Backward Touch Button";
CM_ SG_ 527 ATS_RRRestModBtn "Rear Right Rest Mode Touch Button";
CM_ SG_ 527 ATS_RRResetModBtn "Rear Right Return Mode Touch Button";
CM_ SG_ 527 ATS_RRAvWtcModBtn "Rear Right AV Watching Mode Touch Button";
CM_ SG_ 527 ATS_RRReadingModBtn "Rear Right Reading Mode Touch Button";
CM_ SG_ 527 ATS_RLRestModBtn "Rear Left Rest Mode Touch Button";
CM_ SG_ 527 ATS_RLResetModBtn "Rear Left Return Mode Touch Button";
CM_ BO_ 543 "[PE] Periodic and On Event";
CM_ SG_ 543 ATS_AstStSldFwdBtn "Assist Power Seat Slide Forward Rear Walk In Button";
CM_ SG_ 543 ATS_AstStSldBwdBtn "Assist Power Seat Slide Backward Rear Walk In Button";
CM_ SG_ 543 ATS_AstStRclFwdBtn "Assist Power Seat Recline Forward Rear Walk In Button";
CM_ SG_ 543 ATS_AstStRclBwdBtn "Assist Power Seat Recline Backward Rear Walk In Button";
CM_ SG_ 543 ATS_AstStHgtUpBtn "Assist Power Seat Height Up Walk In Button";
CM_ SG_ 543 ATS_AstStHgtDnBtn "Assist Power Seat Height Dn Walk In Button";
CM_ SG_ 543 ATS_AstStHRestUpBtn "Assist Power Seat Head Rest Up Walk In Button";
CM_ SG_ 543 ATS_AstStHRestDnBtn "Assist Power Seat  Head Rest Dn Walk In Button";
CM_ SG_ 543 ATS_AstStHRestFwdBtn "Assist Power Seat Head Rest Forward  Walk In Button";
CM_ SG_ 543 ATS_AstStHRestBwdBtn "Assist Power Seat Head Rest Backward  Walk In Button";
CM_ SG_ 543 ATS_AstStHRestFldBtn "Assist Power Seat Head Rest Folding  Walk In Button";
CM_ SG_ 543 ATS_AstStHRestUnFldBtn "Assist Power Seat Head Rest Unfolding  Walk In Button";
CM_ SG_ 543 ATS_AstStRseFwdBtn "Assist Power Seat RSE Forward  Walk In Button";
CM_ SG_ 543 ATS_AstStRseBwdBtn "Assist Power Seat RSE Backward Walk In Button";
CM_ SG_ 543 ATS_AstStFRestFldBtn "Assist Power Seat Foot Rest Folding Walk In Button";
CM_ SG_ 543 ATS_AstStFRestUnFldBtn "Assist Power Seat Foot Rest Unfolding Walk In Button";
CM_ SG_ 543 ATS_AstTltUpBtn "Assist Power Seat  Tilt Up Walk In Button";
CM_ SG_ 543 ATS_AstTltDnBtn "Assist Power Seat Tilt Down  Walk In Button";
CM_ BO_ 623 "[PE] Periodic and On Event";
CM_ SG_ 623 ATS_ARSOpenCloseStatus "Armrest Open / Close Status";
CM_ SG_ 623 ATS_RLLumbarDefBtn "Rear Left Lumbar Deflation Touch Button";
CM_ SG_ 623 ATS_RLLumbarLowBtn "Rear Left Lumbar Low Touch Button";
CM_ SG_ 623 ATS_RLLumbarMidBtn "Rear Left Lumbar Middle Touch Button";
CM_ SG_ 623 ATS_RLLumbarUpBtn "Rear Left Lumbar Up Touch Button";
CM_ SG_ 623 ATS_RLBolsterDefBtn "Rear Left Bolster Deflation Touch Button";
CM_ SG_ 623 ATS_RLBolsterInfSw "Rear Left Bolster Inflation Touch Button";
CM_ SG_ 623 ATS_RRLumbarDefBtn "Rear Right Lumbar Deflation Touch Button";
CM_ SG_ 623 ATS_RRLumbarLowBtn "Rear Right Lumbar Low Touch Button";
CM_ SG_ 623 ATS_RRLumbarMidBtn "Rear Right Lumbar Middle Touch Button";
CM_ SG_ 623 ATS_RRLumbarUpBtn "Rear Right Lumbar Up Touch Button";
CM_ SG_ 623 ATS_RRBolsterDefBtn "Rear Right Bolster Deflation Touch Button";
CM_ SG_ 623 ATS_RRBolsterInfSw "Rear Right Bolster Inflation Touch Button";
CM_ BO_ 2395189505 "[PE] Periodic and On Event";
CM_ SG_ 2395189505 DATC_Crc9Val "DATC_CyclicRedundancyCheck9Value";
CM_ SG_ 2395189505 DATC_AlvCnt9Val "DATC_AliveCounter9Value";
CM_ SG_ 2395189505 DATC_FragranceStrhSta "Fragrance Strength State";
CM_ SG_ 2395189505 DATC_FragranceKindSta "Fragrance Kind State";
CM_ SG_ 2395189505 DATC_AfterBlowOpSta "DATC_AfterBlow Operation Status";
CM_ SG_ 2395189505 DATC_RrBlwDis "DATC_RearBlowerDisplay";
CM_ SG_ 2395189505 DATC_RrClmtAutoOffUSMSta "DATC_RearClimateAutoOffUSMState";
CM_ SG_ 2395189505 DATC_ArClnSysOSD "DATC_AirCleaningSystemOSD";
CM_ SG_ 2395189505 DATC_ArClnStepClr "DATC_AirCleaningStepColor";
CM_ SG_ 2395189505 DATC_ArClnSmblTyp "DATC_AirCleaningSymbolType";
CM_ SG_ 2395189505 DATC_AfterBlowUSMSta "DATC_AfterBlowUSMStatus";
CM_ SG_ 2395189505 DATC_SchdldVntUSMSta "DATC_ScheduledVentilationUSMStatus";
CM_ SG_ 2395189505 DATC_SchdldVntHrSta "DATC_ScheduledVentilationHourStatus";
CM_ SG_ 2395189505 DATC_SchdldVntMinSta "DATC_ScheduledVentilationMinutesStatus";
CM_ BO_ 614 "[PE] Periodic and On Event";
CM_ SG_ 614 EMCU_Crc1Val "EMCU_CyclicRedundancyCheck1Value";
CM_ SG_ 614 EMCU_AlvCnt1Val "EMCU_AliveCounter1Value";
CM_ SG_ 614 EMCU_LHActSta "EMCU_LeftActuatorStatus";
CM_ SG_ 614 EMCU_RHActSta "EMCU_RightActuatorStatus";
CM_ SG_ 614 EMCU_DeltaSpdVal "EMCU_DeltaSpeedValue";
CM_ SG_ 614 EMCU_System_Sta "EMCU_SystemStatus";
CM_ BO_ 2214658049 "[P] Periodic";
CM_ SG_ 2214658049 EMS_Crc2Val "EMS_CyclicRedundancyCheck2Value";
CM_ SG_ 2214658049 EMS_AlvCnt2Val "EMS_AliveCounter2Value";
CM_ SG_ 2214658049 ENG_BrkSwSta "ENG_BrakeSwitchStatus ##2G##EMS - EMS12 - BRAKE_ACT";
CM_ SG_ 2214658049 ENG_ObdFrzFrmSta "ENG_ObdFreezeFrameStatus ##2G##EMS - EMS12 - OBD_FRF_ACK";
CM_ SG_ 2214658049 ENG_EngClntTempVal "ENG_EngineCoolantTemperatureValue ##2G##EMS - EMS12 - TEMP_ENG";
CM_ SG_ 2214658049 ENG_MafCrctVal "ENG_MassAirFlowCorrectionValue ##2G##EMS - EMS12 - MAF_FAC_ALTI_MMV";
CM_ SG_ 2214658049 ENG_BattDscnctSta "ENG_BatteryDisconnectStatus ##2G##EMS - EMS12 - VB_OFF_ACT";
CM_ SG_ 2214658049 OBD_MilConfgVal "OBD_MalfunctionIndicationLampConfigurationValue ##2G##EMS - EMS12 - CONF_MIL_FMY";
CM_ SG_ 2214658049 ENG_EngSta "ENG_EngineStatus ##2G##EMS - EMS16 - ENG_STAT";
CM_ BO_ 2214658050 "[P] Periodic";
CM_ SG_ 2214658050 ENG_Ack4EngStpSta "ENG_AcknowledgeForEngineStopStatus ##2G##EMS - EMS12 - ACK_ES";
CM_ SG_ 2214658050 ENG_AccDrvAlertDisp "The status of No Auto cruise Engaged or Auto cruise Disengaged.";
CM_ SG_ 2214658050 DSL_GlowCtrlReq "DSL_GlowControlRequest ##2G##EMS - EMS12 - GP_CTL";
CM_ SG_ 2214658050 ENG_GlowLmpSta "ENG_GlowLampStatus ##2G##EMS - EMS16 - GLOW_STAT";
CM_ SG_ 2214658050 ENG_ThrPosVal "ENG_ThrottlePositionValue ##2G##EMS - EMS12 - TPS";
CM_ SG_ 2214658050 ENG_OverDrvOffReq "ENG_OverDriveOffRequest ##2G##EMS - EMS12 - OD_OFF_REQ";
CM_ SG_ 2214658050 ENG_AccelPdlVal "ENG_AcceleratorPedalValue ##2G##EMS - EMS12 - PV_AV_CAN";
CM_ SG_ 2214658050 ENG_AccActSta "ENG_AutoCruiseControlActiveStatus ##2G##EMS - EMS12 - ACC_ACT";
CM_ SG_ 2214658050 ACC_CrsMainSwLmpSta "ACC_CruiseMainSwLampStatus ##2G##EMS - EMS16 - CRUISE_LAMP_M";
CM_ SG_ 2214658050 ACC_CrsSetSwLmpSta "ACC_CruiseSetSwLampStatus ##2G##EMS - EMS16 - CRUISE_LAMP_S";
CM_ SG_ 2214658050 ENG_LV_FUP_ENA_THD "Fuel prsssure state ##2G##EMS - LPI11 - LV_FUP_ENA_THD";
CM_ SG_ 2214658050 ENG_SoakTimeErrSta "ENG_SoakTimeErrorStatus ##2G##EMS - EMS16 - SOAK_TIME_ERROR";
CM_ SG_ 2214658050 ENG_SoakTimeVal "ENG_SoakTimeValue ##2G##EMS - EMS16 - SOAK_TIME";
CM_ SG_ 2214658050 ENG_SprkTimeVal "ENG_SparkTimeValue ##2G##EMS - EMS16 - SPK_TIME_CUR";
CM_ SG_ 2214658050 ENG_CltchOpSta "ENG_ClutchStatus ##2G##EMS - EMS12 - CLU_ACK";
CM_ SG_ 2214658050 EMS_BrkReq_Slope "Brake request at slope for anti-stall";
CM_ BO_ 2214658051 "[P] Periodic";
CM_ SG_ 2214658051 ENG_MinIndTqVal "ENG_MinimumIndicatedTorqueValue ##2G##EMS - EMS16 - TQI_MIN";
CM_ SG_ 2214658051 ENG_TrgtTqVal "ENG_TargetTorqueValue ##2G##EMS - EMS16 - TQI_TARGET";
CM_ SG_ 2214658051 ENG_MaxIndTqVal "ENG_MaximumIndicatedTorqueValue ##2G##EMS - EMS16 - TQI_MAX";
CM_ SG_ 2214658051 ENG_AppAccelPdlSta "ENG_AppliedAcceleratorPedalStatus ##2G##EMS - EMS16 - CF_Ems_AclAct";
CM_ SG_ 2214658051 ENG_BrkCtrlReq "ENG_BrakeControlRequest ##2G##EMS - EMS19 - CF_Ems_BrkReq";
CM_ SG_ 2214658051 ACC_DnShftCtrlReq "ACC_DownShiftControlRequest ##2G##EMS - EMS19 - CF_Ems_DnShftReq";
CM_ BO_ 2214658052 "[P] Periodic";
CM_ SG_ 2214658052 ENG_DclBrkCntrlReq "ENG_DecelerationBrakeControlRequest ##2G##EMS - EMS19 - CF_Ems_DecelReq";
CM_ SG_ 2214658052 ENG_BstPrsrVal "ENG_BoostPressureValue ##2G##EMS - EMS19 - CR_Ems_BstPre";
CM_ SG_ 2214658052 ENG_EngOilTempVal "ENG_EngineOilTemperatureValue ##2G##EMS - EMS19 - CR_Ems_EngOilTemp";
CM_ SG_ 2214658052 ENG_AmbtTempModelVal "ENG_AmbientTemperatureModelValue ##2G##EMS - EMS19 - CF_Ems_ModeledAmbTemp";
CM_ SG_ 2214658052 ENG_DpfWrngSta "ENG_DpfWarningStatus ##2G##EMS - EMS19 - DPF_LAMP_STAT";
CM_ SG_ 2214658052 ENG_BattWrngLmpSta "ENG_BatteryWarningLampStatus ##2G##EMS - EMS19 - BAT_LAMP_STAT";
CM_ SG_ 2214658052 ENG_OilPrsrWrngLmpSta "ENG_OilPressureWarningLampStatus ##2G##EMS - EMS19 - CF_Ems_OPSFail";
CM_ SG_ 2214658052 ENG_IsgInhbtLmpSta "ENG_IsgInhibitLampStatus ##2G##EMS - EMS19 - ISG_INHIBIT_LAMP_STAT";
CM_ BO_ 1616 "[EC] On Event and On Change";
CM_ SG_ 1616 MKBD_IllumiState "Signal to confirm completion transmission of illumination information between MKBD and HU";
CM_ SG_ 1616 MKBD_SeatKeySet "The signal for transmitting Seat Key inputs from MKBD to Seat ECU";
CM_ BO_ 2449771009 "[P] Periodic";
CM_ SG_ 2449771009 ODS_Crc1Val "ODS_CyclicRedundancyCheck1Value";
CM_ SG_ 2449771009 ODS_AlvCnt1Val "ODS_AliveCounter1Value";
CM_ SG_ 2449771009 ODS_IdVal "ODS_IdValue ##2G##ODS - ODS13 - CR_Ods_ID";
CM_ SG_ 2449771009 ODS_OccClassSta "ODS_OccupantClassificationStatus ##2G##ODS - ODS11 - CR_Wcs_ClassStat";
CM_ SG_ 2449771009 ODS_DiagSta "ODS_SelfDiagnosticStatus ##2G##ODS - ODS11 - CR_Wcs_ErrStat";
CM_ SG_ 2449771009 ODS_SBRClassSta "ODS_SBRClassSta";
CM_ BO_ 2449771010 "[P] Periodic";
CM_ BO_ 1578 "[EW] On Event and On Write";
CM_ SG_ 1578 PSB_CCP_CRO_Byte0 "EOL Message for PSB";
CM_ SG_ 1578 PSB_CCP_CRO_Byte2 "EOL Message for PSB";
CM_ SG_ 1578 PSB_CCP_CRO_Byte3 "EOL Message for PSB";
CM_ SG_ 1578 PSB_CCP_CRO_Byte4 "EOL Message for PSB";
CM_ SG_ 1578 PSB_CCP_CRO_Byte5 "EOL Message for PSB";
CM_ SG_ 1578 PSB_CCP_CRO_Byte6 "EOL Message for PSB";
CM_ SG_ 1578 PSB_CCP_CRO_Byte7 "EOL Message for PSB";
CM_ SG_ 1578 PSB_CCP_CRO_Byte1 "EOL Message for PSB";
CM_ BO_ 1579 "[EW] On Event and On Write";
CM_ SG_ 1579 PSB_CCP_DTO_Byte0 "EOL Message for PSB";
CM_ SG_ 1579 PSB_CCP_DTO_Byte2 "EOL Message for PSB";
CM_ SG_ 1579 PSB_CCP_DTO_Byte3 "EOL Message for PSB";
CM_ SG_ 1579 PSB_CCP_DTO_Byte4 "EOL Message for PSB";
CM_ SG_ 1579 PSB_CCP_DTO_Byte5 "EOL Message for PSB";
CM_ SG_ 1579 PSB_CCP_DTO_Byte6 "EOL Message for PSB";
CM_ SG_ 1579 PSB_CCP_DTO_Byte7 "EOL Message for PSB";
CM_ SG_ 1579 PSB_CCP_DTO_Byte1 "EOL Message for PSB";
CM_ BO_ 553 "[PE] Periodic and On Event";
CM_ SG_ 553 PSS_RL_LumbarUpSw "PSS_RL_LumbarUpSwMoveButton";
CM_ SG_ 553 PSS_RL_BolsterDefSw "PSS_RL_BolsterBwdMoveButton";
CM_ SG_ 553 PSS_RL_ActiveSw "PSS_RL_ActiveSw";
CM_ SG_ 553 PSS_RL_LumbarMidSw "PSS_RL_LumbarFwdSwMoveButton";
CM_ SG_ 553 PSS_RL_LumbarLowSw "PSS_RL_LumbarDnSwMoveButton";
CM_ SG_ 553 PSS_RL_LumbarDefSw "PSS_RL_LumbarBwdSwMoveButton";
CM_ SG_ 553 PSS_RL_BolsterInfSw "PSS_RL_BolsterFwdMoveButton";
CM_ BO_ 630 "[PE] Periodic and On Event";
CM_ SG_ 630 PSS_RR_StSldFwdMvBtn "PSS_RR_SlideForwardMoveButton";
CM_ SG_ 630 PSS_RR_StTltDnMvBtn "PSS_RR_TiltDownMoveButton";
CM_ SG_ 630 PSS_RR_StHRestUpMvBtn "PSS_RR_StHRestUpMvBtn";
CM_ SG_ 630 PSS_RR_StHRestDnMvBtn "PSS_RR_StHRestDnMvBtn";
CM_ SG_ 630 PSS_RR_StHRestFwdMvBtn "PSS_RR_StHRestFwdMvBtn";
CM_ SG_ 630 PSS_RR_StHRestBwdMvBtn "PSS_RR_StHRestBwdMvBtn";
CM_ SG_ 630 PSS_RR_StSldBwdMvBtn "PSS_RR_SlideBackwardMoveButton";
CM_ SG_ 630 PSS_RR_StLegRestUpBtn "PSS_RR_LegUpMoveButton";
CM_ SG_ 630 PSS_RR_StLegRestDnBtn "PSS_RR_LegDownMoveButton";
CM_ SG_ 630 PSS_RR_StLegRestExtFwdBtn "PSS_RR_LegExtFwdMoveButton";
CM_ SG_ 630 PSS_RR_StLegRestExtBwdBtn "PSS_RR_LegExtBwdMoveButton";
CM_ SG_ 630 PSS_RR_StRlxModeBtn "PSS_RR_RelaxModeButton";
CM_ SG_ 630 PSS_RR_StRlxReturnBtn "PSS_RR_RelaxReturnButton";
CM_ SG_ 630 PSS_RR_StRlxTltUpMvBtn "PSS_RR_RelaxTiltUpMoveButton";
CM_ SG_ 630 PSS_RR_StRlxTltDnMvBtn "PSS_RR_RelaxTiltDownMoveButton";
CM_ SG_ 630 PSS_RR_StMnlRlxModeBtn "PSS_RR_MnlRelaxModeButton";
CM_ SG_ 630 PSS_RR_StMnlRlxReturnBtn "PSS_RR_MnlRelaxReturnButton";
CM_ SG_ 630 PSS_RR_StRclFwdMvBtn "PSS_RR_ReclinerForwardMoveButton";
CM_ SG_ 630 PSS_RR_WalkInSwitchSts "PSS_RR_WalkInSwitchStatus";
CM_ SG_ 630 PSS_RR_StRclBwdMvBtn "PSS_RR_ReclinerBackwardMoveButton";
CM_ SG_ 630 PSS_RR_StTltUpMvBtn "PSS_RR_TiltUpMoveButton";
CM_ BO_ 631 "[PE] Periodic and On Event";
CM_ SG_ 631 PSS_RR_StOneTchWlkinCushBtn "PSS_RR_OnetouchWalkinCushMoveButton";
CM_ SG_ 631 PSS_RR_StOneTchWlkinBackBtn "PSS_RR_OnetouchWalkinBackMoveButton";
CM_ SG_ 631 PSS_RR_MomoryP1Cmd "PSS_RR_SeatPositionMemoryP1Request";
CM_ SG_ 631 PSS_RR_MomoryP2Cmd "PSS_RR_SeatPositionMemoryP2Request";
CM_ BO_ 632 "[PE] Periodic and On Event";
CM_ SG_ 632 PSS_RR_AstHRestFwdMvBtn "PSS_RR_AstStHead Rest UpMoveButton";
CM_ SG_ 632 PSS_RR_AstRclBwdMvBtn "PSS_RR_AstStReclinerBackwardMoveButton";
CM_ SG_ 632 PSS_RR_AstSldFwdMvBtn "PSS_RR_AstStSlideForwardMoveButton";
CM_ SG_ 632 PSS_RR_AstSldBwdMvBtn "PSS_RR_AstStSlideBackwardMoveButton";
CM_ SG_ 632 PSS_RR_AstHgtUpMvBtn "PSS_RR_AstStHeightUpMoveButton";
CM_ SG_ 632 PSS_RR_AstHgtDnMvBtn "PSS_RR_AstStHeightDownMoveButton";
CM_ SG_ 632 PSS_RR_AstHRestBwdMvBtn "PSS_RR_AstStHead Rest DownMoveButton";
CM_ SG_ 632 PSS_RR_AstFRestOpenMvBtn "PSS_RR_AstStFootrestOpenButton";
CM_ SG_ 632 PSS_RR_AstFRestCloseMvBtn "PSS_RR_AstStFootrestCloseButton";
CM_ SG_ 632 PSS_RR_AstHRestUpMvBtn "PSS_RR_AstStHead Rest ForwardMoveButton";
CM_ SG_ 632 PSS_RR_AstHRestDnMvBtn "PSS_RR_AstStHead Rest BackwardMoveButton";
CM_ SG_ 632 PSS_RR_AstRclFwdMvBtn "PSS_RR_AstStReclinerForwardMoveButton";
CM_ BO_ 633 "[PE] Periodic and On Event";
CM_ SG_ 633 PSS_RR_LumbarUpSw "PSS_RR_LumbarUpSwMoveButton";
CM_ SG_ 633 PSS_RR_BolsterDefSw "PSS_RR_BolsterBwdMoveButton";
CM_ SG_ 633 PSS_RR_ActiveSw "PSS_RR_ActiveSw";
CM_ SG_ 633 PSS_RR_LumbarMidSw "PSS_RR_LumbarFwdSwMoveButton";
CM_ SG_ 633 PSS_RR_LumbarLowSw "PSS_RR_LumbarDnSwMoveButton";
CM_ SG_ 633 PSS_RR_LumbarDefSw "PSS_RR_LumbarBwdSwMoveButton";
CM_ SG_ 633 PSS_RR_BolsterInfSw "PSS_RR_BolsterFwdMoveButton";
CM_ BO_ 2244048385 "[P] Periodic";
CM_ SG_ 2244048385 RCU_Crc3Val "RCU_CyclicRedundancyCheck3Value";
CM_ SG_ 2244048385 RCU_AlvCnt3Val "RCU_AliveCounter3Value";
CM_ SG_ 2244048385 RCU_HDP_FltMonSta "RCU_HDP_FaultStatus";
CM_ SG_ 2244048385 RCU_HDP_EgSta "RCU_HDP_EngagedStatus";
CM_ SG_ 2244048385 RCU_Sta "IEB_Status ##2G##ESC - EBS1 - CF_Brk_EBSStat";
CM_ SG_ 2244048385 RCU_HDP_EnblReq "RCU_HDP_EnableRequest";
CM_ SG_ 2244048385 RCU_AD3_RCUFltSta "RCU fault status ( degraded support / not support )";
CM_ SG_ 2244048385 RCU_AD3_AWD_FastOpnCrdnShftCltchReq "(RCU) AWD_FastOpenCardanShaftClutchRequest";
CM_ SG_ 2244048385 RCU_AD3_StrkDpthmmVal "RCU Pedal ( PTS2 ) Stroke Depth mmValue";
CM_ SG_ 2244048385 RCU_AD3_PdlTrvlSnsrValVldSta "RCU_PedalTravelSensor Value Validity Status (PTS2)";
CM_ SG_ 2244048385 RCU_AD3_PdlCalibSta "RCU_PedalCalibrationStatus ( PTS2 )";
CM_ SG_ 2244048385 RCU_AD3_TCS_MtrTrgtRpm_Flag_Frnt "TCS_MotorTargetRPM_Flag_Front";
CM_ SG_ 2244048385 RCU_AD3_TCS_MtrTrgtRpm_Flag_Rear "TCS_MotorTargetRPM_Flag_Rear";
CM_ SG_ 2244048385 RCU_AD3_WSSmode "RCU Wheel control mode";
CM_ BO_ 2244048386 "[P] Periodic";
CM_ SG_ 2244048386 RCU_AD3_Wss2FlFltSta "Wheel Speed sensor fault status (Front Left Wheel - 2nd)";
CM_ SG_ 2244048386 RCU_AD3_DiagSta "RCU DiagnosticStatus";
CM_ SG_ 2244048386 RCU_AD3_operation "Indicate RCU mode On / Off ( not each function mode )";
CM_ SG_ 2244048386 RCU_AD3_PrsrValVldSta "RCU front circuit pressure Value Validity";
CM_ SG_ 2244048386 RCU_AD3_PrsrVal "RCU front circuit pressure Value";
CM_ SG_ 2244048386 RCU_AD3_Wss2FrFltSta "Wheel Speed sensor fault status (Front Right Wheel - 2nd))";
CM_ SG_ 2244048386 RCU_AD3_ABS_DfctvSta "RCU ABS function Defective Status";
CM_ SG_ 2244048386 RCU_AD3_ABS_ActvSta "RCU ABS Active Status";
CM_ SG_ 2244048386 RCU_AD3_BBC_DfctvSta "RCU BBC function Defective Status";
CM_ SG_ 2244048386 RCU_AD3_BBC_ActvSta "RCU BBC Active Status";
CM_ SG_ 2244048386 RCU_AD3_Wss2RlFltSta "Wheel Speed sensor fault status (Rear Left Wheel - 2nd)";
CM_ SG_ 2244048386 RCU_AD3_BrkLtActSta "RCU_BrakeLightActiveStatus";
CM_ SG_ 2244048386 RCU_AD3_DrvOvrdSta "RCU_OverrideRequest";
CM_ SG_ 2244048386 RCU_AD3_PrkBrkActvSta "RCU_ParkingBrakeActiveStatus";
CM_ SG_ 2244048386 RCU_AD3_FCA_AvlblSta "RCU_FCA_AvailableStatus";
CM_ SG_ 2244048386 RCU_AD3_MSR_TqIntrvntnVal "RCU_MSR_TorqueInterventionValue";
CM_ SG_ 2244048386 RCU_AD3_TCS_TqIntrvntnVal "RCU_TCS_TorqueInterventionValue";
CM_ SG_ 2244048386 RCU_AD3_Wss2RrFltSta "Wheel Speed sensor fault status (Rear Right Wheel - 2nd)";
CM_ SG_ 2244048386 RCU_AD3_SrvLmpDis "RCU_ServiceLampDisplay";
CM_ BO_ 2244048387 "[P] Periodic";
CM_ SG_ 2244048387 RCU_AD3_SCC_TqIntrvntnVal "RCU_SCC_TorqueInterventionValue";
CM_ SG_ 2244048387 RCU_AD3_TCS_TqFlag "RCU_Flag indicating positive or negative TCS Intervention";
CM_ SG_ 2244048387 RCU_AD3_TCS_Sta "RCU_Status of TCS Function";
CM_ SG_ 2244048387 RCU_AD3_VehAccelVal "RCU_VehicleAccelerationValue";
CM_ SG_ 2244048387 RCU_AD3_MSR_TqFlag "RCU_Flag indicating positive or negative MSR Intervention";
CM_ SG_ 2244048387 RCU_AD3_LDM_Sta "RCU_LDM_Status";
CM_ SG_ 2244048387 RCU_AD3_ECD_ActvSta "RCU_ECD_ActiveStatus";
CM_ SG_ 2244048387 RCU_AD3_MSR_FuncReq "RCU_MSR_FunctionRequest";
CM_ SG_ 2244048387 RCU_AD3_TCS_Req "RCU_TCS_Request";
CM_ SG_ 2244048387 RCU_AD3_TCS_LmpSta "RCU_TCS_LampStatus";
CM_ SG_ 2244048387 RCU_AD3_SCC_TqReq "RCU_SCC_TorqueRequest";
CM_ SG_ 2244048387 RCU_AD3_StdStillVal "RCU_StandStillValue";
CM_ SG_ 2244048387 RCU_AD3_SCC_ReqLimSta "RCU_SCC_RequestLimitedStatus";
CM_ SG_ 2244048387 RCU_AD3_SCC_OptTyp "RCU_SCC_OptionType";
CM_ SG_ 2244048387 RCU_AD3_SCC_EnblReq "RCU_SCC_EnableRequest";
CM_ SG_ 2244048387 RCU_AD3_FCA_EquipSta "RCU_FCA_EquipmentStatus";
CM_ SG_ 2244048387 RCU_AD3_FCA_ActvSta "Status of control for RCU_FCA control request flag";
CM_ SG_ 2244048387 RCU_AD3_DclEnblReq "RCU_DecelerationEnableRequest";
CM_ SG_ 2244048387 RCU_AD3_DBS_ActvSta "RCU_DBS_ActvSta";
CM_ SG_ 2244048387 RCU_AD3_AccelBasisVal "RCU_AccelerationBasisValue";
CM_ BO_ 2244048388 "[P] Periodic";
CM_ SG_ 2244048388 RCU_HDPSpprtSWVer "IEB/RCU - HDP Support Software Version";
CM_ SG_ 2244048388 RCU_RegenTqLimitNmVal_Rear "RCU_RegenTorqueLimitValue Rear";
CM_ SG_ 2244048388 RCU_AD3_TCS_TqIntrvntnVal_Frnt "TCS_TorqueInterventionValue_Front";
CM_ SG_ 2244048388 RCU_AD3_TCS_MtrTrgtRpm_Frnt "TCS_MotorTargetRPM_Front";
CM_ SG_ 2244048388 RCU_AD3_TCS_TqFlag_Frnt "TCS_TorqueFlag_Front";
CM_ SG_ 2244048388 RCU_AD3_TCS_MtrTrgtRpm_Rear "TCS_MotorTargetRPM_Rear";
CM_ SG_ 2244048388 RCU_AD3_ABS_WrngLmpSta "RCU_ABS_WarningLampStatus";
CM_ SG_ 2244048388 RCU_AD3_ESC_Sta "Status of RCU ESC Function";
BA_DEF_ BO_ "DiagState" ENUM "No","Yes" ;
BA_DEF_ BO_ "DiagResponse" ENUM "No","Yes" ;
BA_DEF_ BO_ "DiagRequest" ENUM "No","Yes" ;
BA_DEF_ BO_ "TpMessage" ENUM "No","Yes" ;
BA_DEF_ BO_ "UsrMsgIDSforwardDeviation" INT 0 100 ;
BA_DEF_ BO_ "UsrMsgIDSbackwardDeviation" INT 50 1000 ;
BA_DEF_ BO_ "GenMsgCycleTime" INT 0 2000 ;
BA_DEF_ BO_ "GenMsgStartDelayTime" INT 0 2000 ;
BA_DEF_ BO_ "GenMsgSendType" ENUM "Cyclic","NoMsgSendType" ;
BA_DEF_ BO_ "GenMsgCycleTimeFast" INT 0 500 ;
BA_DEF_ BO_ "GenMsgDelayTime" INT 0 20 ;
BA_DEF_ BO_ "GenMsgILSupport" ENUM "No","Yes" ;
BA_DEF_ BO_ "GenMsgNrOfRepetition" INT 0 3 ;
BA_DEF_ BO_ "NmMessage" ENUM "No","Yes" ;
BA_DEF_ BO_ "NWM-Botschaft" ENUM "No","Yes" ;
BA_DEF_ BO_ "TpTxIndex" INT 0 65535 ;
BA_DEF_ BO_ "VFrameFormat" ENUM "StandardCAN","ExtendedCAN","reserved","reserved","reserved","reserved","reserved","reserved","reserved","reserved","reserved","reserved","reserved","reserved","StandardCAN_FD","ExtendedCAN_FD" ;
BA_DEF_ SG_ "UserSigValidity" ENUM "B+","ACC","IG","IG1","IG2","IG3","IG1 or IG2","IG1 or IG3","Undef" ;
BA_DEF_ SG_ "TimeoutValue" STRING ;
BA_DEF_ SG_ "UsrSigPurpose" ENUM "Undef","FN","DIAG","DIAG(Req)","DIAG(Res)","DIAG(Phy)","DEV","CCP(Req)","CCP(Res)","NM","TP" ;
BA_DEF_ SG_ "GenSigStartValue" INT 0 1215752192 ;
BA_DEF_ SG_ "NetworkRequest" ENUM "Yes","No" ;
BA_DEF_ SG_ "NetworkRequestHoldingTime" INT 0 65535 ;
BA_DEF_ SG_ "Description" STRING ;
BA_DEF_ SG_ "Version" STRING ;
BA_DEF_ SG_ "GenSigEnvVarType" ENUM "Int","Float","Undef" ;
BA_DEF_ SG_ "GenSigSendType" ENUM "Cyclic","OnWrite","OnWriteWithRepetition","OnChange","OnChangeWithRepetition","IfActive","IfActiveWithRepetition","NoSigSendType","OnChangeAndIfActive","OnChangeAndIfActiveWithRepetition" ;
BA_DEF_ SG_ "GwSigLatencyTime" INT 0 65536 ;
BA_DEF_ SG_ "GwSigMissingSourceType" ENUM "Undef","OldValue","DefaultValue","InitialValue" ;
BA_DEF_ SG_ "NWM-WakeupAllowed" ENUM "<n.a.>" ;
BA_DEF_ SG_ "RoutingFactor" INT 1 1215752192 ;
BA_DEF_REL_ BU_SG_REL_ "GenSigTimeoutTime" INT 0 7000 ;
BA_DEF_DEF_ "DiagState" "No" ;
BA_DEF_DEF_ "DiagResponse" "No" ;
BA_DEF_DEF_ "DiagRequest" "No" ;
BA_DEF_DEF_ "TpMessage" "No" ;
BA_DEF_DEF_ "UsrMsgIDSforwardDeviation" 10 ;
BA_DEF_DEF_ "UsrMsgIDSbackwardDeviation" 100 ;
BA_DEF_DEF_ "GenMsgCycleTime" 200 ;
BA_DEF_DEF_ "GenMsgStartDelayTime" 0 ;
BA_DEF_DEF_ "GenMsgSendType" "NoMsgSendType" ;
BA_DEF_DEF_ "GenMsgCycleTimeFast" 40 ;
BA_DEF_DEF_ "GenMsgDelayTime" 20 ;
BA_DEF_DEF_ "GenMsgILSupport" "Yes" ;
BA_DEF_DEF_ "GenMsgNrOfRepetition" 3 ;
BA_DEF_DEF_ "NmMessage" "No" ;
BA_DEF_DEF_ "NWM-Botschaft" "No" ;
BA_DEF_DEF_ "TpTxIndex" 0 ;
BA_DEF_DEF_ "VFrameFormat" "StandardCAN" ;
BA_DEF_DEF_ "UserSigValidity" "IG" ;
BA_DEF_DEF_ "TimeoutValue" "" ;
BA_DEF_DEF_ "UsrSigPurpose" "FN" ;
BA_DEF_DEF_ "GenSigStartValue" 0 ;
BA_DEF_DEF_ "NetworkRequest" "No" ;
BA_DEF_DEF_ "NetworkRequestHoldingTime" 0 ;
BA_DEF_DEF_ "Description" "" ;
BA_DEF_DEF_ "Version" "" ;
BA_DEF_DEF_ "GenSigEnvVarType" "Undef" ;
BA_DEF_DEF_ "GenSigSendType" "NoSigSendType" ;
BA_DEF_DEF_ "GwSigLatencyTime" 40 ;
BA_DEF_DEF_ "GwSigMissingSourceType" "Undef" ;
BA_DEF_DEF_ "NWM-WakeupAllowed" "<n.a.>" ;
BA_DEF_DEF_ "RoutingFactor" 1 ;
BA_DEF_DEF_REL_ "GenSigTimeoutTime" 500 ;
BA_ "GenMsgSendType" BO_ 2273435649 0;
BA_ "GenMsgCycleTime" BO_ 2273435649 150;
BA_ "GenMsgCycleTimeFast" BO_ 2273435649 0;
BA_ "GenMsgNrOfRepetition" BO_ 2273435649 0;
BA_ "VFrameFormat" BO_ 2273435649 1;
BA_ "Description" SG_ 2273435649 ADAS_CMD_Crc31Val "The data area for CRC calculation is based on the data length (DLC) of the message DB.

The CRC shall be calculated over the entire data block (excluding the CRC bytes) including the user data, alive counter and Data ID



- CRC Polynomial (0x1021) , Initial Value : 0xFFFF, XOR value : 0x0000, Data ID : Message ID + 0xF800 

- The initial value is for CRC calculation and the message should be sent with the calculated result value. 

- The mathematical expression to 16 bit CRC polynomial is given here. G(x) = x16 + x12 + x5 + 1



<For CRC calculation of CAN-FD Msg for HS CAN domain ECUs>



- HS-CAN Messages that routed from CAN-FD domain are using 29 bit Extended CAN ID and splitted into 8 Byte Messages.

(from 1 to 4 Msgs, depending on source CAN-FD Msg¡¯s DLC)

- For splitted CAN-FD Msgs¡¯ CRC calculation, HS CAN ECUs should use source CAN-FD Msg¡¯s original STD ID. 

- The original STD ID can be read from Ext ID¡¯s 4~6th Byte.

Eg. STD 0x6AA : EXT SPLT 0x1A8[6AA]01 / 0x1A8[6AA]02 / 0x1A8[6AA]03 / 0x1A8[6AA]04 

(2~4th splitited Msgs can be omitted depending on source CAN-FD Msg¡¯s DLC)

- Aslo, HS-CAN ECUs should use merged data block (from whole splitted Msg) for CRC calculation.";
BA_ "GenSigStartValue" SG_ 2273435649 ADAS_CMD_Crc31Val 65535;
BA_ "UserSigValidity" SG_ 2273435649 ADAS_CMD_Crc31Val 3;
BA_ "RoutingFactor" SG_ 2273435649 ADAS_CMD_Crc31Val 3;
BA_ "Version" SG_ 2273435649 ADAS_CMD_Crc31Val "21.09.03";
BA_ "Description" SG_ 2273435649 ADAS_CMD_AlvCnt31Val "For the first transmission request for a data element the counter shall be initialized with 0 and shall be incremented by 1 for every subsequent send request. 

When the counter reaches the maximum value(0xFF), then it shall restart with 0 for the next send request";
BA_ "UserSigValidity" SG_ 2273435649 ADAS_CMD_AlvCnt31Val 3;
BA_ "RoutingFactor" SG_ 2273435649 ADAS_CMD_AlvCnt31Val 3;
BA_ "Version" SG_ 2273435649 ADAS_CMD_AlvCnt31Val "21.09.03";
BA_ "Description" SG_ 2273435649 HDA_OptUsmSta "This is HDA system status needed for the cluster USM display.";
BA_ "UserSigValidity" SG_ 2273435649 HDA_OptUsmSta 3;
BA_ "RoutingFactor" SG_ 2273435649 HDA_OptUsmSta 3;
BA_ "Version" SG_ 2273435649 HDA_OptUsmSta "17.12.02";
BA_ "Description" SG_ 2273435649 HDA_CntrlModSta "This is HDA Control Mode needed for longitudinal/lateral control and cluster display.";
BA_ "UserSigValidity" SG_ 2273435649 HDA_CntrlModSta 3;
BA_ "RoutingFactor" SG_ 2273435649 HDA_CntrlModSta 3;
BA_ "Version" SG_ 2273435649 HDA_CntrlModSta "20.05.02";
BA_ "Description" SG_ 2273435649 HDA_InfoPUDis "This is HDA information display needed for the cluster pop-up display.";
BA_ "UserSigValidity" SG_ 2273435649 HDA_InfoPUDis 3;
BA_ "RoutingFactor" SG_ 2273435649 HDA_InfoPUDis 3;
BA_ "Version" SG_ 2273435649 HDA_InfoPUDis "21.10.02";
BA_ "Description" SG_ 2273435649 HDP_AutoCallReqSta "This signal is needed for HDP Auto Call.";
BA_ "UserSigValidity" SG_ 2273435649 HDP_AutoCallReqSta 3;
BA_ "RoutingFactor" SG_ 2273435649 HDP_AutoCallReqSta 3;
BA_ "Version" SG_ 2273435649 HDP_AutoCallReqSta "21.04.03";
BA_ "Description" SG_ 2273435649 HDP_DispBarSta "This signal indicates HDP operation state (always not covered other display)";
BA_ "UserSigValidity" SG_ 2273435649 HDP_DispBarSta 0;
BA_ "RoutingFactor" SG_ 2273435649 HDP_DispBarSta 3;
BA_ "Version" SG_ 2273435649 HDP_DispBarSta "22.01.00";
BA_ "Description" SG_ 2273435649 HDP_OptInfoSta "This signal indicates whether the HDP system has been applied or not.

HC means Highway Cruise.";
BA_ "UserSigValidity" SG_ 2273435649 HDP_OptInfoSta 0;
BA_ "RoutingFactor" SG_ 2273435649 HDP_OptInfoSta 3;
BA_ "Version" SG_ 2273435649 HDP_OptInfoSta "22.12.04";
BA_ "Description" SG_ 2273435649 HDA_LFA_SymSta "This signal shows the state of steering assist.";
BA_ "UserSigValidity" SG_ 2273435649 HDA_LFA_SymSta 3;
BA_ "RoutingFactor" SG_ 2273435649 HDA_LFA_SymSta 3;
BA_ "Version" SG_ 2273435649 HDA_LFA_SymSta "20.11.02";
BA_ "Description" SG_ 2273435649 HDA_LFA_WrnSnd "HDA/LFA Additional Warning Sound";
BA_ "UserSigValidity" SG_ 2273435649 HDA_LFA_WrnSnd 3;
BA_ "RoutingFactor" SG_ 2273435649 HDA_LFA_WrnSnd 3;
BA_ "Version" SG_ 2273435649 HDA_LFA_WrnSnd "18.02.03";
BA_ "Description" SG_ 2273435649 HDA_InfoPUDis1 "This is HDA/LFA information display needed for the cluster pop-up display.";
BA_ "UserSigValidity" SG_ 2273435649 HDA_InfoPUDis1 3;
BA_ "RoutingFactor" SG_ 2273435649 HDA_InfoPUDis1 3;
BA_ "Version" SG_ 2273435649 HDA_InfoPUDis1 "21.01.08";
BA_ "Description" SG_ 2273435649 HDA_TDMRMDclReq "This signal show the state of LFA automatic deactivation.";
BA_ "UserSigValidity" SG_ 2273435649 HDA_TDMRMDclReq 3;
BA_ "RoutingFactor" SG_ 2273435649 HDA_TDMRMDclReq 3;
BA_ "Version" SG_ 2273435649 HDA_TDMRMDclReq "19.02.00";
BA_ "Description" SG_ 2273435649 HDP_ActvSta "This signal indicates control active status of HDP.";
BA_ "UserSigValidity" SG_ 2273435649 HDP_ActvSta 3;
BA_REL_ "GenSigTimeoutTime" BU_SG_REL_ PSB SG_ 2273435649 HDP_ActvSta 1500;
BA_ "RoutingFactor" SG_ 2273435649 HDP_ActvSta 3;
BA_ "Version" SG_ 2273435649 HDP_ActvSta "19.11.02";
BA_ "Description" SG_ 2273435649 HDP_SysSta "This signal indicates system status of HDP.";
BA_ "UserSigValidity" SG_ 2273435649 HDP_SysSta 3;
BA_REL_ "GenSigTimeoutTime" BU_SG_REL_ HOD SG_ 2273435649 HDP_SysSta 1500;
BA_ "RoutingFactor" SG_ 2273435649 HDP_SysSta 3;
BA_ "Version" SG_ 2273435649 HDP_SysSta "20.07.10";
BA_ "Description" SG_ 2273435649 HDP_FailureMode "This signal shows HDP failure status";
BA_ "UserSigValidity" SG_ 2273435649 HDP_FailureMode 3;
BA_ "RoutingFactor" SG_ 2273435649 HDP_FailureMode 3;
BA_ "Version" SG_ 2273435649 HDP_FailureMode "20.07.10";
BA_ "GenMsgSendType" BO_ 2273435650 0;
BA_ "GenMsgCycleTime" BO_ 2273435650 150;
BA_ "GenMsgCycleTimeFast" BO_ 2273435650 0;
BA_ "GenMsgNrOfRepetition" BO_ 2273435650 0;
BA_ "VFrameFormat" BO_ 2273435650 1;
BA_ "Description" SG_ 2273435650 HDP_ObstacleDstVal "This signal indicates distance to a obstacle which is on driving path.";
BA_ "GenSigStartValue" SG_ 2273435650 HDP_ObstacleDstVal 2046;
BA_ "UserSigValidity" SG_ 2273435650 HDP_ObstacleDstVal 3;
BA_ "RoutingFactor" SG_ 2273435650 HDP_ObstacleDstVal 3;
BA_ "Version" SG_ 2273435650 HDP_ObstacleDstVal "19.11.02";
BA_ "Description" SG_ 2273435650 HDP_ObstacleLatPosVal "This signal indicates distance to a obstacle which is on driving path.";
BA_ "GenSigStartValue" SG_ 2273435650 HDP_ObstacleLatPosVal 510;
BA_ "UserSigValidity" SG_ 2273435650 HDP_ObstacleLatPosVal 3;
BA_ "RoutingFactor" SG_ 2273435650 HDP_ObstacleLatPosVal 3;
BA_ "Version" SG_ 2273435650 HDP_ObstacleLatPosVal "19.11.02";
BA_ "Description" SG_ 2273435650 HDP_InfoPUDis "This signal needed for the cluster pop-up display to inform HDP system status and warning.";
BA_ "UserSigValidity" SG_ 2273435650 HDP_InfoPUDis 0;
BA_ "RoutingFactor" SG_ 2273435650 HDP_InfoPUDis 3;
BA_ "Version" SG_ 2273435650 HDP_InfoPUDis "23.02.06";
BA_ "Description" SG_ 2273435650 HDP_WrngTypPUDis "This signal is needed for the cluster mini pop-up display to inform a reason of unavailable/TD activation or warning messages.";
BA_ "UserSigValidity" SG_ 2273435650 HDP_WrngTypPUDis 3;
BA_ "RoutingFactor" SG_ 2273435650 HDP_WrngTypPUDis 3;
BA_ "Version" SG_ 2273435650 HDP_WrngTypPUDis "20.03.01";
BA_ "Description" SG_ 2273435650 HDP_HapticWarnReq "This signal is needed for HDP haptic warning";
BA_ "UserSigValidity" SG_ 2273435650 HDP_HapticWarnReq 3;
BA_REL_ "GenSigTimeoutTime" BU_SG_REL_ PSB SG_ 2273435650 HDP_HapticWarnReq 1500;
BA_ "RoutingFactor" SG_ 2273435650 HDP_HapticWarnReq 3;
BA_ "Version" SG_ 2273435650 HDP_HapticWarnReq "22.08.00";
BA_ "Description" SG_ 2273435650 HDP_ActvStaDis "This signal is needed for the cluster symbol display to inform a activation or deactivation status";
BA_ "UserSigValidity" SG_ 2273435650 HDP_ActvStaDis 0;
BA_ "RoutingFactor" SG_ 2273435650 HDP_ActvStaDis 3;
BA_ "Version" SG_ 2273435650 HDP_ActvStaDis "22.05.00";
BA_ "Description" SG_ 2273435650 HDP_OpStaDisp "This signal is needed for the cluster symbol display to inform highway driving pilot status";
BA_ "UserSigValidity" SG_ 2273435650 HDP_OpStaDisp 0;
BA_ "RoutingFactor" SG_ 2273435650 HDP_OpStaDisp 3;
BA_ "Version" SG_ 2273435650 HDP_OpStaDisp "22.05.00";
BA_ "Description" SG_ 2273435650 HDP_ObstSta "This signal represents the state of in-path obstacle and information of controllable state.

- ÀÚÂ÷¼±»óÀÇ Àü¹æ ÀÏ¹Ý¹°Ã¼ ÀÎ½Ä ¿©ºÎ ¹× Á¦¾î °¡´É »óÅÂ Á¤º¸";
BA_ "UserSigValidity" SG_ 2273435650 HDP_ObstSta 3;
BA_ "RoutingFactor" SG_ 2273435650 HDP_ObstSta 3;
BA_ "Version" SG_ 2273435650 HDP_ObstSta "20.06.01";
BA_ "Description" SG_ 2273435650 HDP_SysFlrDisp "This signal is for pop-up indication of HDP system failure.

If this signal is set to 1, the display device shall indicate HDP failure information to the driver.";
BA_ "UserSigValidity" SG_ 2273435650 HDP_SysFlrDisp 0;
BA_ "RoutingFactor" SG_ 2273435650 HDP_SysFlrDisp 3;
BA_ "Version" SG_ 2273435650 HDP_SysFlrDisp "22.05.00";
BA_ "Description" SG_ 2273435650 HDP_InhbtOffDispSta "This signal is shows that driving safety functions are inhibited while HDP in operation";
BA_ "UserSigValidity" SG_ 2273435650 HDP_InhbtOffDispSta 0;
BA_ "RoutingFactor" SG_ 2273435650 HDP_InhbtOffDispSta 3;
BA_ "Version" SG_ 2273435650 HDP_InhbtOffDispSta "22.05.00";
BA_ "Description" SG_ 2273435650 HDP_CtRoadSrfcDistVal "This signal is notifying how far to display the road surfaces.";
BA_ "GenSigStartValue" SG_ 2273435650 HDP_CtRoadSrfcDistVal 2046;
BA_ "UserSigValidity" SG_ 2273435650 HDP_CtRoadSrfcDistVal 0;
BA_ "RoutingFactor" SG_ 2273435650 HDP_CtRoadSrfcDistVal 3;
BA_ "Version" SG_ 2273435650 HDP_CtRoadSrfcDistVal "22.05.00";
BA_ "Description" SG_ 2273435650 ADAS_DRV_UpDateInfo "ADAS_DRV update state info for AVN";
BA_ "GenSigStartValue" SG_ 2273435650 ADAS_DRV_UpDateInfo 1;
BA_ "UserSigValidity" SG_ 2273435650 ADAS_DRV_UpDateInfo 3;
BA_ "RoutingFactor" SG_ 2273435650 ADAS_DRV_UpDateInfo 3;
BA_ "Version" SG_ 2273435650 ADAS_DRV_UpDateInfo "20.10.02";
BA_ "GenMsgSendType" BO_ 527 0;
BA_ "Description" SG_ 527 ATS_DrvStRseFwdBtn "¿îÀü¼® ¸ð´ÏÅÍ °¢µµ Á¶Àý Àü¹æ ÀÌµ¿";
BA_ "GenSigSendType" SG_ 527 ATS_DrvStRseFwdBtn 4;
BA_ "UserSigValidity" SG_ 527 ATS_DrvStRseFwdBtn 3;
BA_ "NetworkRequest" SG_ 527 ATS_DrvStRseFwdBtn 0;
BA_ "NetworkRequestHoldingTime" SG_ 527 ATS_DrvStRseFwdBtn 5000;
BA_ "Version" SG_ 527 ATS_DrvStRseFwdBtn "19.09.02";
BA_ "Description" SG_ 527 ATS_DrvStRseBwdBtn "¿îÀü¼® ¸ð´ÏÅÍ °¢µµ Á¶Àý ÈÄ¹æ ÀÌµ¿";
BA_ "GenSigSendType" SG_ 527 ATS_DrvStRseBwdBtn 4;
BA_ "UserSigValidity" SG_ 527 ATS_DrvStRseBwdBtn 3;
BA_ "NetworkRequest" SG_ 527 ATS_DrvStRseBwdBtn 0;
BA_ "NetworkRequestHoldingTime" SG_ 527 ATS_DrvStRseBwdBtn 5000;
BA_ "Version" SG_ 527 ATS_DrvStRseBwdBtn "19.09.02";
BA_ "Description" SG_ 527 ATS_RRRestModBtn "ÈÄ¼® RH REST ¸ðµå ÀÛµ¿";
BA_ "GenSigSendType" SG_ 527 ATS_RRRestModBtn 4;
BA_ "UserSigValidity" SG_ 527 ATS_RRRestModBtn 3;
BA_ "NetworkRequest" SG_ 527 ATS_RRRestModBtn 0;
BA_ "NetworkRequestHoldingTime" SG_ 527 ATS_RRRestModBtn 5000;
BA_ "Version" SG_ 527 ATS_RRRestModBtn "19.09.02";
BA_ "Description" SG_ 527 ATS_RRResetModBtn "ÈÄ¼® RH RETURN ¸ðµå ÀÛµ¿";
BA_ "GenSigSendType" SG_ 527 ATS_RRResetModBtn 4;
BA_ "UserSigValidity" SG_ 527 ATS_RRResetModBtn 3;
BA_ "NetworkRequest" SG_ 527 ATS_RRResetModBtn 0;
BA_ "NetworkRequestHoldingTime" SG_ 527 ATS_RRResetModBtn 5000;
BA_ "Version" SG_ 527 ATS_RRResetModBtn "19.09.02";
BA_ "Description" SG_ 527 ATS_RRAvWtcModBtn "ÈÄ¼® RH AVN ¸ðµå ÀÛµ¿";
BA_ "GenSigSendType" SG_ 527 ATS_RRAvWtcModBtn 4;
BA_ "UserSigValidity" SG_ 527 ATS_RRAvWtcModBtn 3;
BA_ "NetworkRequest" SG_ 527 ATS_RRAvWtcModBtn 0;
BA_ "NetworkRequestHoldingTime" SG_ 527 ATS_RRAvWtcModBtn 5000;
BA_ "Version" SG_ 527 ATS_RRAvWtcModBtn "19.09.02";
BA_ "Description" SG_ 527 ATS_RRReadingModBtn "ÈÄ¼® RH READING ¸ðµå ÀÛµ¿";
BA_ "GenSigSendType" SG_ 527 ATS_RRReadingModBtn 4;
BA_ "UserSigValidity" SG_ 527 ATS_RRReadingModBtn 3;
BA_ "NetworkRequest" SG_ 527 ATS_RRReadingModBtn 0;
BA_ "NetworkRequestHoldingTime" SG_ 527 ATS_RRReadingModBtn 5000;
BA_ "Version" SG_ 527 ATS_RRReadingModBtn "19.09.02";
BA_ "Description" SG_ 527 ATS_RLRestModBtn "ÈÄ¼® LH REST ¸ðµå ÀÛµ¿";
BA_ "GenSigSendType" SG_ 527 ATS_RLRestModBtn 4;
BA_ "UserSigValidity" SG_ 527 ATS_RLRestModBtn 3;
BA_ "NetworkRequest" SG_ 527 ATS_RLRestModBtn 0;
BA_ "NetworkRequestHoldingTime" SG_ 527 ATS_RLRestModBtn 5000;
BA_ "Version" SG_ 527 ATS_RLRestModBtn "19.09.02";
BA_ "Description" SG_ 527 ATS_RLResetModBtn "ÈÄ¼® LH RETURN ¸ðµå ÀÛµ¿";
BA_ "GenSigSendType" SG_ 527 ATS_RLResetModBtn 4;
BA_ "UserSigValidity" SG_ 527 ATS_RLResetModBtn 3;
BA_ "NetworkRequest" SG_ 527 ATS_RLResetModBtn 0;
BA_ "NetworkRequestHoldingTime" SG_ 527 ATS_RLResetModBtn 5000;
BA_ "Version" SG_ 527 ATS_RLResetModBtn "19.09.02";
BA_ "GenMsgSendType" BO_ 543 0;
BA_ "Description" SG_ 543 ATS_AstStSldFwdBtn "µ¿½Â¼® ½½¶óÀÌµù Àü¹æ ÀÌµ¿ (¿öÅ©ÀÎ ÀÛµ¿)";
BA_ "GenSigSendType" SG_ 543 ATS_AstStSldFwdBtn 4;
BA_ "UserSigValidity" SG_ 543 ATS_AstStSldFwdBtn 3;
BA_ "NetworkRequest" SG_ 543 ATS_AstStSldFwdBtn 0;
BA_ "NetworkRequestHoldingTime" SG_ 543 ATS_AstStSldFwdBtn 5000;
BA_ "Version" SG_ 543 ATS_AstStSldFwdBtn "19.09.02";
BA_ "Description" SG_ 543 ATS_AstStSldBwdBtn "µ¿½Â¼® ½½¶óÀÌµù ÈÄ¹æ ÀÌµ¿ (¿öÅ©ÀÎ ÀÛµ¿)";
BA_ "GenSigSendType" SG_ 543 ATS_AstStSldBwdBtn 4;
BA_ "UserSigValidity" SG_ 543 ATS_AstStSldBwdBtn 3;
BA_ "NetworkRequest" SG_ 543 ATS_AstStSldBwdBtn 0;
BA_ "NetworkRequestHoldingTime" SG_ 543 ATS_AstStSldBwdBtn 5000;
BA_ "Version" SG_ 543 ATS_AstStSldBwdBtn "19.09.02";
BA_ "Description" SG_ 543 ATS_AstStRclFwdBtn "µ¿½Â¼® ¸®Å¬¶óÀÌ´× Àü¹æ ÀÌµ¿ (¿öÅ©ÀÎ ÀÛµ¿)";
BA_ "GenSigSendType" SG_ 543 ATS_AstStRclFwdBtn 4;
BA_ "UserSigValidity" SG_ 543 ATS_AstStRclFwdBtn 3;
BA_ "NetworkRequest" SG_ 543 ATS_AstStRclFwdBtn 0;
BA_ "NetworkRequestHoldingTime" SG_ 543 ATS_AstStRclFwdBtn 5000;
BA_ "Version" SG_ 543 ATS_AstStRclFwdBtn "19.09.02";
BA_ "Description" SG_ 543 ATS_AstStRclBwdBtn "µ¿½Â¼® ¸®Å¬¶óÀÌ´× ÈÄ¹æ ÀÌµ¿ (¿öÅ©ÀÎ ÀÛµ¿)";
BA_ "GenSigSendType" SG_ 543 ATS_AstStRclBwdBtn 4;
BA_ "UserSigValidity" SG_ 543 ATS_AstStRclBwdBtn 3;
BA_ "NetworkRequest" SG_ 543 ATS_AstStRclBwdBtn 0;
BA_ "NetworkRequestHoldingTime" SG_ 543 ATS_AstStRclBwdBtn 5000;
BA_ "Version" SG_ 543 ATS_AstStRclBwdBtn "19.09.02";
BA_ "Description" SG_ 543 ATS_AstStHgtUpBtn "µ¿½Â¼® ÇÏÀÌÆ® ¾÷ ÀÌµ¿ (¿öÅ©ÀÎ ÀÛµ¿)";
BA_ "GenSigSendType" SG_ 543 ATS_AstStHgtUpBtn 4;
BA_ "UserSigValidity" SG_ 543 ATS_AstStHgtUpBtn 3;
BA_ "NetworkRequest" SG_ 543 ATS_AstStHgtUpBtn 0;
BA_ "NetworkRequestHoldingTime" SG_ 543 ATS_AstStHgtUpBtn 5000;
BA_ "Version" SG_ 543 ATS_AstStHgtUpBtn "19.09.02";
BA_ "Description" SG_ 543 ATS_AstStHgtDnBtn "µ¿½Â¼® ÇÏÀÌÆ® ´Ù¿î ÀÌµ¿ (¿öÅ©ÀÎ ÀÛµ¿)";
BA_ "GenSigSendType" SG_ 543 ATS_AstStHgtDnBtn 4;
BA_ "UserSigValidity" SG_ 543 ATS_AstStHgtDnBtn 3;
BA_ "NetworkRequest" SG_ 543 ATS_AstStHgtDnBtn 0;
BA_ "NetworkRequestHoldingTime" SG_ 543 ATS_AstStHgtDnBtn 5000;
BA_ "Version" SG_ 543 ATS_AstStHgtDnBtn "19.09.02";
BA_ "Description" SG_ 543 ATS_AstStHRestUpBtn "µ¿½Â¼® Çìµå·¹½ºÆ® ¾÷ ÀÌµ¿ (¿öÅ©ÀÎ ÀÛµ¿)";
BA_ "GenSigSendType" SG_ 543 ATS_AstStHRestUpBtn 4;
BA_ "UserSigValidity" SG_ 543 ATS_AstStHRestUpBtn 3;
BA_ "NetworkRequest" SG_ 543 ATS_AstStHRestUpBtn 0;
BA_ "NetworkRequestHoldingTime" SG_ 543 ATS_AstStHRestUpBtn 5000;
BA_ "Version" SG_ 543 ATS_AstStHRestUpBtn "19.09.02";
BA_ "Description" SG_ 543 ATS_AstStHRestDnBtn "µ¿½Â¼® Çìµå·¹½ºÆ® ´Ù¿î ÀÌµ¿ (¿öÅ©ÀÎ ÀÛµ¿)";
BA_ "GenSigSendType" SG_ 543 ATS_AstStHRestDnBtn 4;
BA_ "UserSigValidity" SG_ 543 ATS_AstStHRestDnBtn 3;
BA_ "NetworkRequest" SG_ 543 ATS_AstStHRestDnBtn 0;
BA_ "NetworkRequestHoldingTime" SG_ 543 ATS_AstStHRestDnBtn 5000;
BA_ "Version" SG_ 543 ATS_AstStHRestDnBtn "19.09.02";
BA_ "Description" SG_ 543 ATS_AstStHRestFwdBtn "µ¿½Â¼® Çìµå·¹½ºÆ® Àü¹æ ÀÌµ¿ (¿öÅ©ÀÎ ÀÛµ¿)";
BA_ "GenSigSendType" SG_ 543 ATS_AstStHRestFwdBtn 4;
BA_ "UserSigValidity" SG_ 543 ATS_AstStHRestFwdBtn 3;
BA_ "NetworkRequest" SG_ 543 ATS_AstStHRestFwdBtn 0;
BA_ "NetworkRequestHoldingTime" SG_ 543 ATS_AstStHRestFwdBtn 5000;
BA_ "Version" SG_ 543 ATS_AstStHRestFwdBtn "19.09.02";
BA_ "Description" SG_ 543 ATS_AstStHRestBwdBtn "µ¿½Â¼® Çìµå·¹½ºÆ® ÈÄ¹æ ÀÌµ¿ (¿öÅ©ÀÎ ÀÛµ¿)";
BA_ "GenSigSendType" SG_ 543 ATS_AstStHRestBwdBtn 4;
BA_ "UserSigValidity" SG_ 543 ATS_AstStHRestBwdBtn 3;
BA_ "NetworkRequest" SG_ 543 ATS_AstStHRestBwdBtn 0;
BA_ "NetworkRequestHoldingTime" SG_ 543 ATS_AstStHRestBwdBtn 5000;
BA_ "Version" SG_ 543 ATS_AstStHRestBwdBtn "19.09.02";
BA_ "Description" SG_ 543 ATS_AstStHRestFldBtn "µ¿½Â¼® Çìµå·¹½ºÆ® Æúµù ÀÌµ¿ (¿öÅ©ÀÎ ÀÛµ¿)";
BA_ "GenSigSendType" SG_ 543 ATS_AstStHRestFldBtn 4;
BA_ "UserSigValidity" SG_ 543 ATS_AstStHRestFldBtn 3;
BA_ "NetworkRequest" SG_ 543 ATS_AstStHRestFldBtn 0;
BA_ "NetworkRequestHoldingTime" SG_ 543 ATS_AstStHRestFldBtn 5000;
BA_ "Version" SG_ 543 ATS_AstStHRestFldBtn "19.09.02";
BA_ "Description" SG_ 543 ATS_AstStHRestUnFldBtn "µ¿½Â¼® Çìµå·¹½ºÆ® ¾ðÆúµù ÀÌµ¿ (¿öÅ©ÀÎ ÀÛµ¿)";
BA_ "GenSigSendType" SG_ 543 ATS_AstStHRestUnFldBtn 4;
BA_ "UserSigValidity" SG_ 543 ATS_AstStHRestUnFldBtn 3;
BA_ "NetworkRequest" SG_ 543 ATS_AstStHRestUnFldBtn 0;
BA_ "NetworkRequestHoldingTime" SG_ 543 ATS_AstStHRestUnFldBtn 5000;
BA_ "Version" SG_ 543 ATS_AstStHRestUnFldBtn "19.09.02";
BA_ "Description" SG_ 543 ATS_AstStRseFwdBtn "µ¿½Â¼® ¸ð´ÏÅÍ °¢µµ Á¶Àý Àü¹æ ÀÌµ¿";
BA_ "GenSigSendType" SG_ 543 ATS_AstStRseFwdBtn 4;
BA_ "UserSigValidity" SG_ 543 ATS_AstStRseFwdBtn 3;
BA_ "NetworkRequest" SG_ 543 ATS_AstStRseFwdBtn 0;
BA_ "NetworkRequestHoldingTime" SG_ 543 ATS_AstStRseFwdBtn 5000;
BA_ "Version" SG_ 543 ATS_AstStRseFwdBtn "19.09.02";
BA_ "Description" SG_ 543 ATS_AstStRseBwdBtn "µ¿½Â¼® ¸ð´ÏÅÍ °¢µµ Á¶Àý ÈÄ¹æ ÀÌµ¿";
BA_ "GenSigSendType" SG_ 543 ATS_AstStRseBwdBtn 4;
BA_ "UserSigValidity" SG_ 543 ATS_AstStRseBwdBtn 3;
BA_ "NetworkRequest" SG_ 543 ATS_AstStRseBwdBtn 0;
BA_ "NetworkRequestHoldingTime" SG_ 543 ATS_AstStRseBwdBtn 5000;
BA_ "Version" SG_ 543 ATS_AstStRseBwdBtn "19.09.02";
BA_ "Description" SG_ 543 ATS_AstStFRestFldBtn "µ¿½Â¼® Ç²·¹½ºÆ® Æúµù ÀÌµ¿ (¿öÅ©ÀÎ ÀÛµ¿)";
BA_ "GenSigSendType" SG_ 543 ATS_AstStFRestFldBtn 4;
BA_ "UserSigValidity" SG_ 543 ATS_AstStFRestFldBtn 3;
BA_ "NetworkRequest" SG_ 543 ATS_AstStFRestFldBtn 0;
BA_ "NetworkRequestHoldingTime" SG_ 543 ATS_AstStFRestFldBtn 5000;
BA_ "Version" SG_ 543 ATS_AstStFRestFldBtn "19.09.02";
BA_ "Description" SG_ 543 ATS_AstStFRestUnFldBtn "µ¿½Â¼® Ç²·¹½ºÆ® ¾ðÆúµù ÀÌµ¿ (¿öÅ©ÀÎ ÀÛµ¿)";
BA_ "GenSigSendType" SG_ 543 ATS_AstStFRestUnFldBtn 4;
BA_ "UserSigValidity" SG_ 543 ATS_AstStFRestUnFldBtn 3;
BA_ "NetworkRequest" SG_ 543 ATS_AstStFRestUnFldBtn 0;
BA_ "NetworkRequestHoldingTime" SG_ 543 ATS_AstStFRestUnFldBtn 5000;
BA_ "Version" SG_ 543 ATS_AstStFRestUnFldBtn "19.09.02";
BA_ "Description" SG_ 543 ATS_AstTltUpBtn "µ¿½Â¼® Æ¿Æ® UP ÀÌµ¿ (¿öÅ©ÀÎ ÀÛµ¿)";
BA_ "GenSigSendType" SG_ 543 ATS_AstTltUpBtn 4;
BA_ "UserSigValidity" SG_ 543 ATS_AstTltUpBtn 3;
BA_ "NetworkRequest" SG_ 543 ATS_AstTltUpBtn 0;
BA_ "NetworkRequestHoldingTime" SG_ 543 ATS_AstTltUpBtn 5000;
BA_ "Version" SG_ 543 ATS_AstTltUpBtn "19.12.00";
BA_ "Description" SG_ 543 ATS_AstTltDnBtn "µ¿½Â¼® Æ¿Æ® DOWN ÀÌµ¿ (¿öÅ©ÀÎ ÀÛµ¿)";
BA_ "GenSigSendType" SG_ 543 ATS_AstTltDnBtn 4;
BA_ "UserSigValidity" SG_ 543 ATS_AstTltDnBtn 3;
BA_ "NetworkRequest" SG_ 543 ATS_AstTltDnBtn 0;
BA_ "NetworkRequestHoldingTime" SG_ 543 ATS_AstTltDnBtn 5000;
BA_ "Version" SG_ 543 ATS_AstTltDnBtn "19.12.00";
BA_ "GenMsgSendType" BO_ 623 0;
BA_ "Description" SG_ 623 ATS_ARSOpenCloseStatus "ÈÄ¼® ¾Ï·¹½ºÆ® ¿­¸²/´ÝÈû »óÅÂ ½ÅÈ£";
BA_ "GenSigSendType" SG_ 623 ATS_ARSOpenCloseStatus 4;
BA_ "UserSigValidity" SG_ 623 ATS_ARSOpenCloseStatus 3;
BA_ "NetworkRequest" SG_ 623 ATS_ARSOpenCloseStatus 0;
BA_ "NetworkRequestHoldingTime" SG_ 623 ATS_ARSOpenCloseStatus 5000;
BA_ "Version" SG_ 623 ATS_ARSOpenCloseStatus "20.12.05";
BA_ "Description" SG_ 623 ATS_RLLumbarDefBtn "ÈÄ¼® LH ·³¹ö ¹è±â ÀÛµ¿";
BA_ "GenSigSendType" SG_ 623 ATS_RLLumbarDefBtn 4;
BA_ "UserSigValidity" SG_ 623 ATS_RLLumbarDefBtn 3;
BA_ "NetworkRequest" SG_ 623 ATS_RLLumbarDefBtn 0;
BA_ "NetworkRequestHoldingTime" SG_ 623 ATS_RLLumbarDefBtn 5000;
BA_ "Version" SG_ 623 ATS_RLLumbarDefBtn "19.09.02";
BA_ "Description" SG_ 623 ATS_RLLumbarLowBtn "ÈÄ¼® LH ·³¹ö LOW ÀÛµ¿";
BA_ "GenSigSendType" SG_ 623 ATS_RLLumbarLowBtn 4;
BA_ "UserSigValidity" SG_ 623 ATS_RLLumbarLowBtn 3;
BA_ "NetworkRequest" SG_ 623 ATS_RLLumbarLowBtn 0;
BA_ "NetworkRequestHoldingTime" SG_ 623 ATS_RLLumbarLowBtn 5000;
BA_ "Version" SG_ 623 ATS_RLLumbarLowBtn "19.09.02";
BA_ "Description" SG_ 623 ATS_RLLumbarMidBtn "ÈÄ¼® LH ·³¹ö MID ÀÛµ¿";
BA_ "GenSigSendType" SG_ 623 ATS_RLLumbarMidBtn 4;
BA_ "UserSigValidity" SG_ 623 ATS_RLLumbarMidBtn 3;
BA_ "NetworkRequest" SG_ 623 ATS_RLLumbarMidBtn 0;
BA_ "NetworkRequestHoldingTime" SG_ 623 ATS_RLLumbarMidBtn 5000;
BA_ "Version" SG_ 623 ATS_RLLumbarMidBtn "19.09.02";
BA_ "Description" SG_ 623 ATS_RLLumbarUpBtn "ÈÄ¼® LH ·³¹ö UP ÀÛµ¿";
BA_ "GenSigSendType" SG_ 623 ATS_RLLumbarUpBtn 4;
BA_ "UserSigValidity" SG_ 623 ATS_RLLumbarUpBtn 3;
BA_ "NetworkRequest" SG_ 623 ATS_RLLumbarUpBtn 0;
BA_ "NetworkRequestHoldingTime" SG_ 623 ATS_RLLumbarUpBtn 5000;
BA_ "Version" SG_ 623 ATS_RLLumbarUpBtn "19.09.02";
BA_ "Description" SG_ 623 ATS_RLBolsterDefBtn "ÈÄ¼® LH º¼½ºÅÍ ¹è±â ÀÛµ¿";
BA_ "GenSigSendType" SG_ 623 ATS_RLBolsterDefBtn 4;
BA_ "UserSigValidity" SG_ 623 ATS_RLBolsterDefBtn 3;
BA_ "NetworkRequest" SG_ 623 ATS_RLBolsterDefBtn 0;
BA_ "NetworkRequestHoldingTime" SG_ 623 ATS_RLBolsterDefBtn 5000;
BA_ "Version" SG_ 623 ATS_RLBolsterDefBtn "19.09.02";
BA_ "Description" SG_ 623 ATS_RLBolsterInfSw "ÈÄ¼® LH º¼½ºÅÍ Èí±â ÀÛµ¿";
BA_ "GenSigSendType" SG_ 623 ATS_RLBolsterInfSw 4;
BA_ "UserSigValidity" SG_ 623 ATS_RLBolsterInfSw 3;
BA_ "NetworkRequest" SG_ 623 ATS_RLBolsterInfSw 0;
BA_ "NetworkRequestHoldingTime" SG_ 623 ATS_RLBolsterInfSw 5000;
BA_ "Version" SG_ 623 ATS_RLBolsterInfSw "19.09.02";
BA_ "Description" SG_ 623 ATS_RRLumbarDefBtn "ÈÄ¼® LH ·³¹ö ¹è±â ÀÛµ¿";
BA_ "GenSigSendType" SG_ 623 ATS_RRLumbarDefBtn 4;
BA_ "UserSigValidity" SG_ 623 ATS_RRLumbarDefBtn 3;
BA_ "NetworkRequest" SG_ 623 ATS_RRLumbarDefBtn 0;
BA_ "NetworkRequestHoldingTime" SG_ 623 ATS_RRLumbarDefBtn 5000;
BA_ "Version" SG_ 623 ATS_RRLumbarDefBtn "19.09.02";
BA_ "Description" SG_ 623 ATS_RRLumbarLowBtn "ÈÄ¼® RH ·³¹ö LOW ÀÛµ¿";
BA_ "GenSigSendType" SG_ 623 ATS_RRLumbarLowBtn 4;
BA_ "UserSigValidity" SG_ 623 ATS_RRLumbarLowBtn 3;
BA_ "NetworkRequest" SG_ 623 ATS_RRLumbarLowBtn 0;
BA_ "NetworkRequestHoldingTime" SG_ 623 ATS_RRLumbarLowBtn 5000;
BA_ "Version" SG_ 623 ATS_RRLumbarLowBtn "19.09.02";
BA_ "Description" SG_ 623 ATS_RRLumbarMidBtn "ÈÄ¼® RH ·³¹ö MID ÀÛµ¿";
BA_ "GenSigSendType" SG_ 623 ATS_RRLumbarMidBtn 4;
BA_ "UserSigValidity" SG_ 623 ATS_RRLumbarMidBtn 3;
BA_ "NetworkRequest" SG_ 623 ATS_RRLumbarMidBtn 0;
BA_ "NetworkRequestHoldingTime" SG_ 623 ATS_RRLumbarMidBtn 5000;
BA_ "Version" SG_ 623 ATS_RRLumbarMidBtn "19.09.02";
BA_ "Description" SG_ 623 ATS_RRLumbarUpBtn "ÈÄ¼® RH ·³¹ö UP ÀÛµ¿";
BA_ "GenSigSendType" SG_ 623 ATS_RRLumbarUpBtn 4;
BA_ "UserSigValidity" SG_ 623 ATS_RRLumbarUpBtn 3;
BA_ "NetworkRequest" SG_ 623 ATS_RRLumbarUpBtn 0;
BA_ "NetworkRequestHoldingTime" SG_ 623 ATS_RRLumbarUpBtn 5000;
BA_ "Version" SG_ 623 ATS_RRLumbarUpBtn "19.09.02";
BA_ "Description" SG_ 623 ATS_RRBolsterDefBtn "ÈÄ¼® RH º¼½ºÅÍ ¹è±â ÀÛµ¿";
BA_ "GenSigSendType" SG_ 623 ATS_RRBolsterDefBtn 4;
BA_ "UserSigValidity" SG_ 623 ATS_RRBolsterDefBtn 3;
BA_ "NetworkRequest" SG_ 623 ATS_RRBolsterDefBtn 0;
BA_ "NetworkRequestHoldingTime" SG_ 623 ATS_RRBolsterDefBtn 5000;
BA_ "Version" SG_ 623 ATS_RRBolsterDefBtn "19.09.02";
BA_ "Description" SG_ 623 ATS_RRBolsterInfSw "ÈÄ¼® RH º¼½ºÅÍ Èí±â ÀÛµ¿";
BA_ "GenSigSendType" SG_ 623 ATS_RRBolsterInfSw 4;
BA_ "UserSigValidity" SG_ 623 ATS_RRBolsterInfSw 3;
BA_ "NetworkRequest" SG_ 623 ATS_RRBolsterInfSw 0;
BA_ "NetworkRequestHoldingTime" SG_ 623 ATS_RRBolsterInfSw 5000;
BA_ "Version" SG_ 623 ATS_RRBolsterInfSw "19.09.02";
BA_ "GenMsgSendType" BO_ 2395189505 0;
BA_ "VFrameFormat" BO_ 2395189505 1;
BA_ "Description" SG_ 2395189505 DATC_Crc9Val "The data area for CRC calculation is based on the data length (DLC) of the message DB.

The CRC shall be calculated over the entire data block (excluding the CRC bytes) including the user data, alive counter and Data ID



- CRC Polynomial (0x1021) , Initial Value : 0xFFFF, XOR value : 0x0000, Data ID : Message ID + 0xF800 

- The initial value is for CRC calculation and the message should be sent with the calculated result value. 

- The mathematical expression to 16 bit CRC polynomial is given here. G(x) = x16 + x12 + x5 + 1



<For CRC calculation of CAN-FD Msg for HS CAN domain ECUs>



- HS-CAN Messages that routed from CAN-FD domain are using 29 bit Extended CAN ID and splitted into 8 Byte Messages.

(from 1 to 4 Msgs, depending on source CAN-FD Msg¡¯s DLC)

- For splitted CAN-FD Msgs¡¯ CRC calculation, HS CAN ECUs should use source CAN-FD Msg¡¯s original STD ID. 

- The original STD ID can be read from Ext ID¡¯s 4~6th Byte.

Eg. STD 0x6AA : EXT SPLT 0x1A8[6AA]01 / 0x1A8[6AA]02 / 0x1A8[6AA]03 / 0x1A8[6AA]04 

(2~4th splitited Msgs can be omitted depending on source CAN-FD Msg¡¯s DLC)

- Aslo, HS-CAN ECUs should use merged data block (from whole splitted Msg) for CRC calculation.";
BA_ "GenSigSendType" SG_ 2395189505 DATC_Crc9Val 4;
BA_ "GenSigStartValue" SG_ 2395189505 DATC_Crc9Val 65535;
BA_ "UserSigValidity" SG_ 2395189505 DATC_Crc9Val 3;
BA_ "Version" SG_ 2395189505 DATC_Crc9Val "21.09.03";
BA_ "Description" SG_ 2395189505 DATC_AlvCnt9Val "For the first transmission request for a data element the counter shall be initialized with 0 and shall be incremented by 1 for every subsequent send request. 

When the counter reaches the maximum value(0xFF), then it shall restart with 0 for the next send request";
BA_ "GenSigSendType" SG_ 2395189505 DATC_AlvCnt9Val 4;
BA_ "UserSigValidity" SG_ 2395189505 DATC_AlvCnt9Val 3;
BA_ "Version" SG_ 2395189505 DATC_AlvCnt9Val "21.09.03";
BA_ "Description" SG_ 2395189505 DATC_FragranceStrhSta "This signal indicate frangrance strength state";
BA_ "GenSigSendType" SG_ 2395189505 DATC_FragranceStrhSta 4;
BA_ "UserSigValidity" SG_ 2395189505 DATC_FragranceStrhSta 7;
BA_REL_ "GenSigTimeoutTime" BU_SG_REL_ ATS SG_ 2395189505 DATC_FragranceStrhSta 1500;
BA_ "Version" SG_ 2395189505 DATC_FragranceStrhSta "20.03.00";
BA_ "Description" SG_ 2395189505 DATC_FragranceKindSta "This signal indicate fragrance kind state.";
BA_ "GenSigSendType" SG_ 2395189505 DATC_FragranceKindSta 4;
BA_ "UserSigValidity" SG_ 2395189505 DATC_FragranceKindSta 7;
BA_REL_ "GenSigTimeoutTime" BU_SG_REL_ ATS SG_ 2395189505 DATC_FragranceKindSta 1500;
BA_ "Version" SG_ 2395189505 DATC_FragranceKindSta "20.03.00";
BA_ "Description" SG_ 2395189505 DATC_AfterBlowOpSta "Operating Status of AfterBlow";
BA_ "GenSigSendType" SG_ 2395189505 DATC_AfterBlowOpSta 4;
BA_ "UserSigValidity" SG_ 2395189505 DATC_AfterBlowOpSta 7;
BA_ "Version" SG_ 2395189505 DATC_AfterBlowOpSta "20.09.00";
BA_ "GenSigSendType" SG_ 2395189505 DATC_RrBlwDis 4;
BA_ "UserSigValidity" SG_ 2395189505 DATC_RrBlwDis 7;
BA_REL_ "GenSigTimeoutTime" BU_SG_REL_ ATS SG_ 2395189505 DATC_RrBlwDis 1500;
BA_ "Version" SG_ 2395189505 DATC_RrBlwDis "21.07.06";
BA_ "Description" SG_ 2395189505 DATC_RrClmtAutoOffUSMSta "This signal indicate Rear Climate Auto Off USM State.";
BA_ "GenSigSendType" SG_ 2395189505 DATC_RrClmtAutoOffUSMSta 4;
BA_ "UserSigValidity" SG_ 2395189505 DATC_RrClmtAutoOffUSMSta 7;
BA_ "Version" SG_ 2395189505 DATC_RrClmtAutoOffUSMSta "20.12.04";
BA_ "Description" SG_ 2395189505 DATC_KeyOffBlowOpReq "Operating Request of AfterBlow";
BA_ "GenSigSendType" SG_ 2395189505 DATC_KeyOffBlowOpReq 4;
BA_ "UserSigValidity" SG_ 2395189505 DATC_KeyOffBlowOpReq 7;
BA_ "Version" SG_ 2395189505 DATC_KeyOffBlowOpReq "22.05.02";
BA_ "Description" SG_ 2395189505 DATC_ArClnSysOSD "This signal indicate the feature of OSD POP UP about Air Cleaning System.";
BA_ "GenSigSendType" SG_ 2395189505 DATC_ArClnSysOSD 4;
BA_ "UserSigValidity" SG_ 2395189505 DATC_ArClnSysOSD 7;
BA_ "Version" SG_ 2395189505 DATC_ArClnSysOSD "19.08.01";
BA_ "Description" SG_ 2395189505 DATC_ArClnStepClr "This signal indicate the information about Color of AirCleaning Symbol displaying in the AVN";
BA_ "GenSigSendType" SG_ 2395189505 DATC_ArClnStepClr 4;
BA_ "UserSigValidity" SG_ 2395189505 DATC_ArClnStepClr 7;
BA_REL_ "GenSigTimeoutTime" BU_SG_REL_ ATS SG_ 2395189505 DATC_ArClnStepClr 1500;
BA_ "Version" SG_ 2395189505 DATC_ArClnStepClr "19.02.03";
BA_ "Description" SG_ 2395189505 DATC_ArClnSmblTyp "This signal indicate the feature of Air Cleaning Symbol displaying in AVN";
BA_ "GenSigSendType" SG_ 2395189505 DATC_ArClnSmblTyp 4;
BA_ "UserSigValidity" SG_ 2395189505 DATC_ArClnSmblTyp 7;
BA_REL_ "GenSigTimeoutTime" BU_SG_REL_ ATS SG_ 2395189505 DATC_ArClnSmblTyp 1500;
BA_ "Version" SG_ 2395189505 DATC_ArClnSmblTyp "18.12.08";
BA_ "Description" SG_ 2395189505 DATC_AfterBlowUSMSta "This signal indicate activation status of USM setting menu about After Blow.";
BA_ "GenSigSendType" SG_ 2395189505 DATC_AfterBlowUSMSta 4;
BA_ "UserSigValidity" SG_ 2395189505 DATC_AfterBlowUSMSta 7;
BA_ "Version" SG_ 2395189505 DATC_AfterBlowUSMSta "19.10.06";
BA_ "Description" SG_ 2395189505 DATC_SchdldVntUSMSta "This signal indicate activation status of USM setting menu about Scheduled Ventilation";
BA_ "GenSigSendType" SG_ 2395189505 DATC_SchdldVntUSMSta 4;
BA_ "UserSigValidity" SG_ 2395189505 DATC_SchdldVntUSMSta 7;
BA_ "Version" SG_ 2395189505 DATC_SchdldVntUSMSta "19.08.08";
BA_ "Description" SG_ 2395189505 DATC_SchdldVntHrSta "This signal indicates the value corresponding to 'hour' among the set time values of the scheduled ventilation USM";
BA_ "GenSigSendType" SG_ 2395189505 DATC_SchdldVntHrSta 4;
BA_ "UserSigValidity" SG_ 2395189505 DATC_SchdldVntHrSta 7;
BA_ "Version" SG_ 2395189505 DATC_SchdldVntHrSta "19.08.08";
BA_ "Description" SG_ 2395189505 DATC_SchdldVntMinSta "This signal indicates the value corresponding to 'minutes' among the set time values of the scheduled ventilation USM.";
BA_ "GenSigSendType" SG_ 2395189505 DATC_SchdldVntMinSta 4;
BA_ "UserSigValidity" SG_ 2395189505 DATC_SchdldVntMinSta 7;
BA_ "Version" SG_ 2395189505 DATC_SchdldVntMinSta "19.08.08";
BA_ "GenMsgSendType" BO_ 614 0;
BA_ "Description" SG_ 614 EMCU_Crc1Val "The data area for CRC calculation is based on the data length (DLC) of the message DB.

The CRC shall be calculated over the entire data block (excluding the CRC bytes) including the user data, alive counter and Data ID 

 

- CRC Polynomial (0x1D) , Initial Value : 0x00, XOR value : 0xFF, Data ID Mode : Both, Data ID : Message ID + 0xF800 

- The initial value is for CRC calculation and the message should be sent with the calculated result value. 

The mathematical expression to 8 bit CRC polynomial is given here. G(x) = x8 + x4 + x3 + x2 + 1";
BA_ "GenSigSendType" SG_ 614 EMCU_Crc1Val 4;
BA_ "UserSigValidity" SG_ 614 EMCU_Crc1Val 0;
BA_ "Version" SG_ 614 EMCU_Crc1Val "22.05.03";
BA_ "Description" SG_ 614 EMCU_AlvCnt1Val "For the first transmission request for a data element the counter shall be initialized with 0 and shall be incremented by 1

for every subsequent send request. When the counter reaches the maximum value(0xE), then it shall restart with 0 for the next send request";
BA_ "GenSigSendType" SG_ 614 EMCU_AlvCnt1Val 4;
BA_ "UserSigValidity" SG_ 614 EMCU_AlvCnt1Val 0;
BA_ "Version" SG_ 614 EMCU_AlvCnt1Val "22.05.03";
BA_ "Description" SG_ 614 EMCU_LHActSta "Left Engine Mount ON/OFF Status";
BA_ "GenSigSendType" SG_ 614 EMCU_LHActSta 4;
BA_ "UserSigValidity" SG_ 614 EMCU_LHActSta 3;
BA_ "Version" SG_ 614 EMCU_LHActSta "21.10.03";
BA_ "Description" SG_ 614 EMCU_RHActSta "Right Engine Mount ON/OFF Status";
BA_ "GenSigSendType" SG_ 614 EMCU_RHActSta 4;
BA_ "UserSigValidity" SG_ 614 EMCU_RHActSta 3;
BA_ "Version" SG_ 614 EMCU_RHActSta "21.10.03";
BA_ "Description" SG_ 614 EMCU_DeltaSpdVal "Current Delta Speed Vaule in control logic";
BA_ "GenSigSendType" SG_ 614 EMCU_DeltaSpdVal 4;
BA_ "UserSigValidity" SG_ 614 EMCU_DeltaSpdVal 3;
BA_ "Version" SG_ 614 EMCU_DeltaSpdVal "21.10.03";
BA_ "Description" SG_ 614 EMCU_System_Sta "Engine Mount Control Unit Status";
BA_ "GenSigSendType" SG_ 614 EMCU_System_Sta 4;
BA_ "UserSigValidity" SG_ 614 EMCU_System_Sta 3;
BA_ "Version" SG_ 614 EMCU_System_Sta "21.10.03";
BA_ "GenMsgSendType" BO_ 2214658049 0;
BA_ "GenMsgCycleTime" BO_ 2214658049 50;
BA_ "GenMsgCycleTimeFast" BO_ 2214658049 0;
BA_ "GenMsgNrOfRepetition" BO_ 2214658049 0;
BA_ "VFrameFormat" BO_ 2214658049 1;
BA_ "Description" SG_ 2214658049 EMS_Crc2Val "The data area for CRC calculation is based on the data length (DLC) of the message DB.

The CRC shall be calculated over the entire data block (excluding the CRC bytes) including the user data, alive counter and Data ID



- CRC Polynomial (0x1021) , Initial Value : 0xFFFF, XOR value : 0x0000, Data ID : Message ID + 0xF800 

- The initial value is for CRC calculation and the message should be sent with the calculated result value. 

- The mathematical expression to 16 bit CRC polynomial is given here. G(x) = x16 + x12 + x5 + 1



<For CRC calculation of CAN-FD Msg for HS CAN domain ECUs>



- HS-CAN Messages that routed from CAN-FD domain are using 29 bit Extended CAN ID and splitted into 8 Byte Messages.

(from 1 to 4 Msgs, depending on source CAN-FD Msg¡¯s DLC)

- For splitted CAN-FD Msgs¡¯ CRC calculation, HS CAN ECUs should use source CAN-FD Msg¡¯s original STD ID. 

- The original STD ID can be read from Ext ID¡¯s 4~6th Byte.

Eg. STD 0x6AA : EXT SPLT 0x1A8[6AA]01 / 0x1A8[6AA]02 / 0x1A8[6AA]03 / 0x1A8[6AA]04 

(2~4th splitited Msgs can be omitted depending on source CAN-FD Msg¡¯s DLC)

- Aslo, HS-CAN ECUs should use merged data block (from whole splitted Msg) for CRC calculation.";
BA_ "GenSigStartValue" SG_ 2214658049 EMS_Crc2Val 65535;
BA_ "UserSigValidity" SG_ 2214658049 EMS_Crc2Val 3;
BA_ "RoutingFactor" SG_ 2214658049 EMS_Crc2Val 5;
BA_ "Version" SG_ 2214658049 EMS_Crc2Val "21.09.03";
BA_ "Description" SG_ 2214658049 EMS_AlvCnt2Val "For the first transmission request for a data element the counter shall be initialized with 0 and shall be incremented by 1 for every subsequent send request. 

When the counter reaches the maximum value(0xFF), then it shall restart with 0 for the next send request";
BA_ "UserSigValidity" SG_ 2214658049 EMS_AlvCnt2Val 3;
BA_ "RoutingFactor" SG_ 2214658049 EMS_AlvCnt2Val 5;
BA_ "Version" SG_ 2214658049 EMS_AlvCnt2Val "21.09.03";
BA_ "Description" SG_ 2214658049 ENG_BrkSwSta "This signal indicates that a brake switch is activated or not. When the brake switch is activated(pressed) its value is 01H otherwise its value is 00H.

If the EMS does not support this signal the value is 02H.



Physical range : 0 ... 100

Conversion : (PH) = (Unsigned)0.002 * (HEX)[%]";
BA_ "GenSigStartValue" SG_ 2214658049 ENG_BrkSwSta 1;
BA_ "UserSigValidity" SG_ 2214658049 ENG_BrkSwSta 3;
BA_ "RoutingFactor" SG_ 2214658049 ENG_BrkSwSta 5;
BA_ "Version" SG_ 2214658049 ENG_BrkSwSta "18.11.00";
BA_ "Description" SG_ 2214658049 ENG_ObdFrzFrmSta "An ECU which detects an OBD fault, requires the EMS to store a set of environmental conditions

(freeze frame). If the EMS follows this requirement it is acknowledged in OBD_FRF_ACK. Also the synchronization of OBD relevant ECUs is made by this signal:



Bit 3-5 is used for freeze frame acknowledgement.

Bit 2 is set, in case a driving cycle has started.

Bit 1 is set, in case a trip is finished.

Bit 0 is set, in case a warm up cycle is finished.



Bit 5, 4, 3 freeze frame status :

0 - No freeze frame stored

1 - Freeze frame requested by EMS

2 - Freeze frame requested by TCU

3 - Freeze frame requested by TCS

4~7 - Reserved";
BA_ "UserSigValidity" SG_ 2214658049 ENG_ObdFrzFrmSta 3;
BA_ "RoutingFactor" SG_ 2214658049 ENG_ObdFrzFrmSta 5;
BA_ "Version" SG_ 2214658049 ENG_ObdFrzFrmSta "17.12.00";
BA_ "Description" SG_ 2214658049 ENG_EngClntTempVal "Engine coolant temperature in EMS sensed via an A/D converter; converted into degrees centigrade (¡ÆC).";
BA_ "GenSigStartValue" SG_ 2214658049 ENG_EngClntTempVal 255;
BA_ "UserSigValidity" SG_ 2214658049 ENG_EngClntTempVal 3;
BA_ "RoutingFactor" SG_ 2214658049 ENG_EngClntTempVal 5;
BA_ "Version" SG_ 2214658049 ENG_EngClntTempVal "17.12.00";
BA_ "Description" SG_ 2214658049 ENG_MafCrctVal "The altitude correction factor MAF_FAC_ALTI_MMV is calculated from division of MAF by MAF_SUB_DIAG (=limp home-value for MAF) or from AMP_AD by 1013 mbar in order to take into account different atmospheric pressures at different altitudes.



The Initial-value of 1.0 indicates sea-level, whereas lower values indicate altitude. MAF_FAC_ALTI_MMV is limited to C_MAF_FAC_ALTI_MMV_MIN (=0.6) and C_MAF_FAC_ALTI_MMV_MAX (=1.1) by calibration.";
BA_ "GenSigStartValue" SG_ 2214658049 ENG_MafCrctVal 128;
BA_ "UserSigValidity" SG_ 2214658049 ENG_MafCrctVal 3;
BA_ "RoutingFactor" SG_ 2214658049 ENG_MafCrctVal 5;
BA_ "Version" SG_ 2214658049 ENG_MafCrctVal "17.12.00";
BA_ "Description" SG_ 2214658049 ENG_BattDscnctSta "The signal specifies that ECU has detected a disconnection of the battery since last driving cycle, and therefore has reset the adaptive values and failure memory.

If the EMS does not support this signal the value is 00H



The failure memory erasure is activated only if the calibration C_CONF_NVMY_RST is set to 1 inside the EMS.";
BA_ "UserSigValidity" SG_ 2214658049 ENG_BattDscnctSta 3;
BA_ "RoutingFactor" SG_ 2214658049 ENG_BattDscnctSta 5;
BA_ "Version" SG_ 2214658049 ENG_BattDscnctSta "17.12.00";
BA_ "Description" SG_ 2214658049 OBD_MilConfgVal "The signal specifies the Configuration of the MIL Handling and Failure Memory Management by ECU.";
BA_ "GenSigStartValue" SG_ 2214658049 OBD_MilConfgVal 3;
BA_ "UserSigValidity" SG_ 2214658049 OBD_MilConfgVal 3;
BA_ "RoutingFactor" SG_ 2214658049 OBD_MilConfgVal 5;
BA_ "Version" SG_ 2214658049 OBD_MilConfgVal "17.12.00";
BA_ "Description" SG_ 2214658049 ENG_EngSta "This signal indicates that a status of engine.";
BA_ "UserSigValidity" SG_ 2214658049 ENG_EngSta 3;
BA_ "RoutingFactor" SG_ 2214658049 ENG_EngSta 5;
BA_ "Version" SG_ 2214658049 ENG_EngSta "17.12.00";
BA_ "GenMsgSendType" BO_ 2214658050 0;
BA_ "GenMsgCycleTime" BO_ 2214658050 50;
BA_ "GenMsgCycleTimeFast" BO_ 2214658050 0;
BA_ "GenMsgNrOfRepetition" BO_ 2214658050 0;
BA_ "VFrameFormat" BO_ 2214658050 1;
BA_ "Description" SG_ 2214658050 ENG_Ack4EngStpSta "The signal specifies the acknowledgement of the request for the operating state 'engine stopped'.";
BA_ "UserSigValidity" SG_ 2214658050 ENG_Ack4EngStpSta 3;
BA_ "RoutingFactor" SG_ 2214658050 ENG_Ack4EngStpSta 5;
BA_ "Version" SG_ 2214658050 ENG_Ack4EngStpSta "17.12.00";
BA_ "Description" SG_ 2214658050 ENG_AccDrvAlertDisp "If EMS sends the No Auto cruise engaged status or Auto cruise Disengaged status, 

Cluster shall display the status of Auto cruise.";
BA_ "TimeoutValue" SG_ 2214658050 ENG_AccDrvAlertDisp "0x0";
BA_ "UserSigValidity" SG_ 2214658050 ENG_AccDrvAlertDisp 3;
BA_ "RoutingFactor" SG_ 2214658050 ENG_AccDrvAlertDisp 5;
BA_ "Version" SG_ 2214658050 ENG_AccDrvAlertDisp "19.12.08";
BA_ "Description" SG_ 2214658050 DSL_GlowCtrlReq "This signal indicates that a diesel ECU requests ISS system to control glow plugs. 



If the EMS does not support this signal the value is 00H";
BA_ "UserSigValidity" SG_ 2214658050 DSL_GlowCtrlReq 3;
BA_ "RoutingFactor" SG_ 2214658050 DSL_GlowCtrlReq 5;
BA_ "Version" SG_ 2214658050 DSL_GlowCtrlReq "17.12.00";
BA_ "Description" SG_ 2214658050 ENG_GlowLmpSta "This signal indicates that a status of glow lamp.



This signal is used for a Diesel or LPI Engine alternatively.";
BA_ "GenSigStartValue" SG_ 2214658050 ENG_GlowLmpSta 1;
BA_ "UserSigValidity" SG_ 2214658050 ENG_GlowLmpSta 3;
BA_ "RoutingFactor" SG_ 2214658050 ENG_GlowLmpSta 5;
BA_ "Version" SG_ 2214658050 ENG_GlowLmpSta "17.12.00";
BA_ "Description" SG_ 2214658050 ENG_ThrPosVal "The signal TPS is a measure of the throttle position.

The throttle position is determined via a potentiometer, which is connected mechanically to the throttle shaft. The voltage value, which is adjusted in the port via the voltage divider, is sensed in the EMS by an A/D converter. The lower mechanical stop (idle) is sensed by a learning algorithm (offset). If the EMS-ECU recognizes closed throttle then the value 20 H is carried over on the CAN. If the EMS-ECU detects full load, that means nearly perpendicular throttle position, then F5 H is carried over on the CAN bus. Even if the throttle position exceeds the full load detection throttle angle the transmitted HEX-value is limited to F5 H.



If an error is detected in sensing of the position, this is identified by the value FFH.";
BA_ "GenSigStartValue" SG_ 2214658050 ENG_ThrPosVal 32;
BA_ "UserSigValidity" SG_ 2214658050 ENG_ThrPosVal 3;
BA_ "RoutingFactor" SG_ 2214658050 ENG_ThrPosVal 5;
BA_ "Version" SG_ 2214658050 ENG_ThrPosVal "17.12.00";
BA_ "Description" SG_ 2214658050 ENG_OverDrvOffReq "This signal indicates that auto cruise control function requests over drive off of TCU. 

In general, the over drive off request is done by hardware. (i.e. line-to-line signal between an EMS and a TCU). However, some systems may not have external over drive off requetst signal line and for these systems OD_OFF_REQ signal can be used as the same function.";
BA_ "UserSigValidity" SG_ 2214658050 ENG_OverDrvOffReq 3;
BA_ "RoutingFactor" SG_ 2214658050 ENG_OverDrvOffReq 5;
BA_ "Version" SG_ 2214658050 ENG_OverDrvOffReq "17.12.00";
BA_ "Description" SG_ 2214658050 ENG_AccelPdlVal "The signal PV_AV_CAN is a measure of the Accelerator Pedal value.

The accelerator pedal value is determined via 2 pedal sensors, which are connected mechanically to the

accelerator pedal. If the EMS-ECU recognizes that the accelerator pedal is not activated, then the value

00 H is carried over on the CAN. If the EMS-ECU detects that the accelerator pedal is fully activated, then 3FEH is carried over on the CAN bus.

If an error is detected on both pedal sensor channels, this is identified by the value 3FFH.



Signal relationship between ACC_ACT and PV_AV_CAN :

The phase relationship between auto cruise control and PV_AV_CAN is as following figure. If an auto cruise control system is not installed or if cruise control is not activated in auto cruise control system installed vehicle then PV_AV_CAN has actual pedal position value. But if the auto cruise control is activated (actually speed control is performed by EMS), PV_AV_CAN should have modeling value even if a driver does not press the acceleration pedal.

If ACC_ACT is value(0), then PV_AV_CAN is APS Value.

If ACC_ACT is value(1), then PV_AV_CAN is Modeling Value.

* APS Value : Acceleration Pedal Sensor value.

* Modeling Value : Estimated APS value which is calculated by ECU logic considering engine control during the auto-cruise control is activated period. (e.g. estimated throttle value of

gasoline engine system or TPS model value of diesel engine system)

And also this value can be used as a driver intension for the shift control of an A/T during auto-cruise control.



Signal relationship between PV_AV_CAN and TPS in DIESEL system :

In a diesel engine vehicle which has an ETC system, basically TPS has APS value. And if auto cruise control is activated then both TPS and PV_AV_CAN should have modeling value which is estimated according to the actual fuel injection and other factors that affect engine torque.";
BA_ "UserSigValidity" SG_ 2214658050 ENG_AccelPdlVal 3;
BA_ "RoutingFactor" SG_ 2214658050 ENG_AccelPdlVal 5;
BA_ "Version" SG_ 2214658050 ENG_AccelPdlVal "18.01.01";
BA_ "Description" SG_ 2214658050 ENG_AccActSta "EMS sends the state of the cruise control via the signal ACC_ACT. 

If the EMS does not support this signal the value is 00H



If the cruise control is activated then ACC_ACT = 1. In this period, vehicle speed control (cruise control) is performed by the auto-cruise control function of ECU only (including acceleration control, deceleration control, etc.). 

Although ¡°SCC set¡± switch is on (Cruise control is enabled), if the cruise control function is deactivated (e.g. when a driver presses an accel. pedal or a brake pedal to increase or to decarese vcehicle speed more or less than set speed) then ACC_ACT should be set to ¡®0¡¯.";
BA_ "UserSigValidity" SG_ 2214658050 ENG_AccActSta 3;
BA_ "RoutingFactor" SG_ 2214658050 ENG_AccActSta 5;
BA_ "Version" SG_ 2214658050 ENG_AccActSta "17.12.00";
BA_ "Description" SG_ 2214658050 ACC_CrsMainSwLmpSta "This signal indicates that an ECU requests cluster to turn on/off auto-cruise control ¡°MAIN¡± switch indication lamp.



This signal is for the CAN-type cluster installed vehicled only.";
BA_ "UserSigValidity" SG_ 2214658050 ACC_CrsMainSwLmpSta 3;
BA_ "RoutingFactor" SG_ 2214658050 ACC_CrsMainSwLmpSta 5;
BA_ "Version" SG_ 2214658050 ACC_CrsMainSwLmpSta "17.12.00";
BA_ "Description" SG_ 2214658050 ACC_CrsSetSwLmpSta "This signal indicates that an ECU requests cluster to turn on/off auto-cruise control ¡°SET¡± switch indication lamp.



This signal is for the CAN-type cluster installed vehicled only.";
BA_ "UserSigValidity" SG_ 2214658050 ACC_CrsSetSwLmpSta 3;
BA_ "RoutingFactor" SG_ 2214658050 ACC_CrsSetSwLmpSta 5;
BA_ "Version" SG_ 2214658050 ACC_CrsSetSwLmpSta "17.12.00";
BA_ "Description" SG_ 2214658050 ENG_LV_FUP_ENA_THD "The signal indicates that the status of the pressure on fuel rail is enough high to start engine.

(LPI)";
BA_ "UserSigValidity" SG_ 2214658050 ENG_LV_FUP_ENA_THD 3;
BA_ "RoutingFactor" SG_ 2214658050 ENG_LV_FUP_ENA_THD 5;
BA_ "Version" SG_ 2214658050 ENG_LV_FUP_ENA_THD "18.12.01";
BA_ "Description" SG_ 2214658050 ENG_SoakTimeErrSta "This signal indicates that information on soak time error.";
BA_ "UserSigValidity" SG_ 2214658050 ENG_SoakTimeErrSta 3;
BA_ "RoutingFactor" SG_ 2214658050 ENG_SoakTimeErrSta 5;
BA_ "Version" SG_ 2214658050 ENG_SoakTimeErrSta "17.12.00";
BA_ "Description" SG_ 2214658050 ENG_SoakTimeVal "The Signal SOAK_TIME means the duration from Engine Ignition Off to Ignition On.";
BA_ "UserSigValidity" SG_ 2214658050 ENG_SoakTimeVal 3;
BA_ "RoutingFactor" SG_ 2214658050 ENG_SoakTimeVal 5;
BA_ "Version" SG_ 2214658050 ENG_SoakTimeVal "17.12.00";
BA_ "Description" SG_ 2214658050 ENG_SprkTimeVal "This signal indicates output value of final spark timing from ECU which reflects torque intervention requests by ESC(TCS), SCC and TCU.



Physical range:

-35.625¢ª ¡¦ 0¢ª  =  00H .. 5FH (Retard)

0.375¢ª ¡¦ 60¢ª  =  60H .. FFH (Advance) 



Conversion:  (PH)=((HEX)-5FH) * 0.375 [¢ª ] (Advance)

(PH)=(5FH-(HEX)) *(- 0.375) [¢ª ] (Retard)";
BA_ "UserSigValidity" SG_ 2214658050 ENG_SprkTimeVal 3;
BA_ "RoutingFactor" SG_ 2214658050 ENG_SprkTimeVal 5;
BA_ "Version" SG_ 2214658050 ENG_SprkTimeVal "17.12.00";
BA_ "Description" SG_ 2214658050 ENG_CltchOpSta "This signal indicates that ECU has detected an operation of a clutch. Using this signal an ISG (Idle Stop & Go) system acts as an alternator or a starter.



If the EMS does not support this signal the value is 00H";
BA_ "UserSigValidity" SG_ 2214658050 ENG_CltchOpSta 3;
BA_ "RoutingFactor" SG_ 2214658050 ENG_CltchOpSta 5;
BA_ "Version" SG_ 2214658050 ENG_CltchOpSta "17.12.00";
BA_ "Description" SG_ 2214658050 EMS_BrkReq_Slope "Brake request at slope for anti-stall";
BA_ "UserSigValidity" SG_ 2214658050 EMS_BrkReq_Slope 3;
BA_ "RoutingFactor" SG_ 2214658050 EMS_BrkReq_Slope 5;
BA_ "Version" SG_ 2214658050 EMS_BrkReq_Slope "20.04.06";
BA_ "GenMsgSendType" BO_ 2214658051 0;
BA_ "GenMsgCycleTime" BO_ 2214658051 50;
BA_ "GenMsgCycleTimeFast" BO_ 2214658051 0;
BA_ "GenMsgNrOfRepetition" BO_ 2214658051 0;
BA_ "VFrameFormat" BO_ 2214658051 1;
BA_ "Description" SG_ 2214658051 ENG_MinIndTqVal "The signal TQI_MIN is the minimum engine torque (minimum air charging rate) which can be fired without misfire including compensation factors such as atmospheric pressure and temperature.

It is not enough to keep the engine running without external power such as inertia.

Firing is impossible below TQI_MIN even if engine is turning by inertia. The friction torque is

always greater than TQI_MIN which is almost constant value across engine RPM.

This signal is used to determine when activation of automatic braking is required to achieve a certain deceleration or if the engine deceleration is sufficient under current conditions.



Under normal driving conditions the physical value of this signal is negative:

TQ_MIN[Nm] = TQI_MIN[Nm] - TQFR[Nm]



If MSB is 1, this signal is - value.

else, this signal is +value.

0~10bit is used for absolute value.";
BA_ "UserSigValidity" SG_ 2214658051 ENG_MinIndTqVal 3;
BA_ "RoutingFactor" SG_ 2214658051 ENG_MinIndTqVal 5;
BA_ "Version" SG_ 2214658051 ENG_MinIndTqVal "18.01.01";
BA_ "Description" SG_ 2214658051 ENG_TrgtTqVal "The signal TQI_TARGET is determined by an engine torque map with input which consists of  acceleration pedal value, MAF sensor, current RPM and etc. This signal reflects driver¡¯s demand directly. 

But it does not depend on torque interventions realised due to reduction of airflow into the engine cylinders and due to ignition angle adjustment or injection/cylinder shut off.



In case of failures of the load signal (either MAF error or other errors depending on the system congiguration), a backup value is generated from specific index tables. The backup value mode is identified by the signal F_SUB_TQI. 



There is a specific phase relationship between the signals TQI_TARGET and F_SUB_TQI.



If MSB is 1, this signal is - value.

else, this signal is +value.

0~10bit is used for absolute value.";
BA_ "UserSigValidity" SG_ 2214658051 ENG_TrgtTqVal 3;
BA_ "RoutingFactor" SG_ 2214658051 ENG_TrgtTqVal 5;
BA_ "Version" SG_ 2214658051 ENG_TrgtTqVal "18.01.01";
BA_ "Description" SG_ 2214658051 ENG_MaxIndTqVal "The signal TQI_MAX is the current maximum indicated engine torque. This signal reflects the maximum engine torque under current conditions (engine speed, etc¡¦).



Note : TQI_MAX must be transmitted actual engine torque including COT, thermal/spark efficiency etc..

 This means that the TQI_ACOR can reach to the TQI_MAX.

 If not possible, thTQI_MAX should be ¡° FFH¡± (99.6%) to reduce TCS/ESC variant.



TQ_MAX[Nm] = TQI_MAX[Nm] - TQFR[Nm]



If MSB is 1, this signal is - value.

else, this signal is +value.

0~10bit is used for absolute value.";
BA_ "UserSigValidity" SG_ 2214658051 ENG_MaxIndTqVal 3;
BA_ "RoutingFactor" SG_ 2214658051 ENG_MaxIndTqVal 5;
BA_ "Version" SG_ 2214658051 ENG_MaxIndTqVal "18.01.01";
BA_ "Description" SG_ 2214658051 ENG_AppAccelPdlSta "This signal indicates if the driver applies the accelerator pedal. 

The signal always indicates the actual operation of the accelerator pedal, independent from SCC mode.";
BA_ "UserSigValidity" SG_ 2214658051 ENG_AppAccelPdlSta 3;
BA_ "RoutingFactor" SG_ 2214658051 ENG_AppAccelPdlSta 5;
BA_ "Version" SG_ 2214658051 ENG_AppAccelPdlSta "17.12.00";
BA_ "Description" SG_ 2214658051 ENG_BrkCtrlReq "This signal indicates that if brake control request during cruise control or speed limiter is active or not. This signal is for prevention of unwanted vehicle speed increase during cruise control or speed limiter control mode.";
BA_ "UserSigValidity" SG_ 2214658051 ENG_BrkCtrlReq 3;
BA_ "RoutingFactor" SG_ 2214658051 ENG_BrkCtrlReq 5;
BA_ "Version" SG_ 2214658051 ENG_BrkCtrlReq "17.12.00";
BA_ "Description" SG_ 2214658051 ACC_DnShftCtrlReq "This signal indicates target gear for downshift control request during cruise control or speed limiter is active or not. This signal is for prevention of unwanted vehicle speed increase during cruise control or speed limiter control mode.";
BA_ "UserSigValidity" SG_ 2214658051 ACC_DnShftCtrlReq 3;
BA_ "RoutingFactor" SG_ 2214658051 ACC_DnShftCtrlReq 5;
BA_ "Version" SG_ 2214658051 ACC_DnShftCtrlReq "17.12.00";
BA_ "GenMsgSendType" BO_ 2214658052 0;
BA_ "GenMsgCycleTime" BO_ 2214658052 50;
BA_ "GenMsgCycleTimeFast" BO_ 2214658052 0;
BA_ "GenMsgNrOfRepetition" BO_ 2214658052 0;
BA_ "VFrameFormat" BO_ 2214658052 1;
BA_ "Description" SG_ 2214658052 ENG_DclBrkCntrlReq "When current vehicle speed goes over set vehicle speed in the downhill during cruise control or speed limiter, ECU requests brake control to TCS with target deceleration. This is function of (Current vehicle speed - Set vehicle speed).";
BA_ "GenSigStartValue" SG_ 2214658052 ENG_DclBrkCntrlReq 4094;
BA_ "UserSigValidity" SG_ 2214658052 ENG_DclBrkCntrlReq 3;
BA_ "RoutingFactor" SG_ 2214658052 ENG_DclBrkCntrlReq 5;
BA_ "Version" SG_ 2214658052 ENG_DclBrkCntrlReq "17.12.00";
BA_ "Description" SG_ 2214658052 ENG_BstPrsrVal "Boost pressure for Turbo engine";
BA_ "UserSigValidity" SG_ 2214658052 ENG_BstPrsrVal 3;
BA_ "RoutingFactor" SG_ 2214658052 ENG_BstPrsrVal 5;
BA_ "Version" SG_ 2214658052 ENG_BstPrsrVal "17.12.00";
BA_ "Description" SG_ 2214658052 ENG_EngOilTempVal "engine oil temperature";
BA_ "GenSigStartValue" SG_ 2214658052 ENG_EngOilTempVal 53;
BA_ "UserSigValidity" SG_ 2214658052 ENG_EngOilTempVal 3;
BA_ "RoutingFactor" SG_ 2214658052 ENG_EngOilTempVal 5;
BA_ "Version" SG_ 2214658052 ENG_EngOilTempVal "17.12.00";
BA_ "Description" SG_ 2214658052 ENG_AmbtTempModelVal "Modeled Ambient temperature";
BA_ "GenSigStartValue" SG_ 2214658052 ENG_AmbtTempModelVal 164;
BA_ "UserSigValidity" SG_ 2214658052 ENG_AmbtTempModelVal 3;
BA_ "RoutingFactor" SG_ 2214658052 ENG_AmbtTempModelVal 5;
BA_ "Version" SG_ 2214658052 ENG_AmbtTempModelVal "17.12.00";
BA_ "Description" SG_ 2214658052 ENG_DpfWrngSta "The signal indicates the status of the 'DPF Warning Level'";
BA_ "UserSigValidity" SG_ 2214658052 ENG_DpfWrngSta 3;
BA_ "RoutingFactor" SG_ 2214658052 ENG_DpfWrngSta 5;
BA_ "Version" SG_ 2214658052 ENG_DpfWrngSta "17.12.00";
BA_ "Description" SG_ 2214658052 ENG_BattWrngLmpSta "The signal indicates the status of the 'Battery Warning Lamp'";
BA_ "UserSigValidity" SG_ 2214658052 ENG_BattWrngLmpSta 3;
BA_ "RoutingFactor" SG_ 2214658052 ENG_BattWrngLmpSta 5;
BA_ "Version" SG_ 2214658052 ENG_BattWrngLmpSta "17.12.00";
BA_ "Description" SG_ 2214658052 ENG_OilPrsrWrngLmpSta "The signal indicates the status of the 'Oil Pressure Warning Lamp'";
BA_ "UserSigValidity" SG_ 2214658052 ENG_OilPrsrWrngLmpSta 3;
BA_ "RoutingFactor" SG_ 2214658052 ENG_OilPrsrWrngLmpSta 5;
BA_ "Version" SG_ 2214658052 ENG_OilPrsrWrngLmpSta "17.12.00";
BA_ "Description" SG_ 2214658052 ENG_IsgInhbtLmpSta "The signal indicates the status of the 'ISG Inhibit Lamp'";
BA_ "UserSigValidity" SG_ 2214658052 ENG_IsgInhbtLmpSta 3;
BA_ "RoutingFactor" SG_ 2214658052 ENG_IsgInhbtLmpSta 5;
BA_ "Version" SG_ 2214658052 ENG_IsgInhbtLmpSta "17.12.00";
BA_ "GenMsgCycleTime" BO_ 1616 0;
BA_ "GenSigSendType" SG_ 1616 MKBD_IllumiState 4;
BA_ "GenSigStartValue" SG_ 1616 MKBD_IllumiState 3;
BA_ "UserSigValidity" SG_ 1616 MKBD_IllumiState 1;
BA_ "Version" SG_ 1616 MKBD_IllumiState "20.04.02";
BA_ "Description" SG_ 1616 MKBD_SeatKeySet "The signal for transmitting Seat Key inputs from MKBD to Seat ECU

Release : 0x0 / Press : 0x1";
BA_ "GenSigSendType" SG_ 1616 MKBD_SeatKeySet 4;
BA_ "GenSigStartValue" SG_ 1616 MKBD_SeatKeySet 3;
BA_ "UserSigValidity" SG_ 1616 MKBD_SeatKeySet 3;
BA_REL_ "GenSigTimeoutTime" BU_SG_REL_ GW_APSU SG_ 1616 MKBD_SeatKeySet 0;
BA_REL_ "GenSigTimeoutTime" BU_SG_REL_ GW_DPSU SG_ 1616 MKBD_SeatKeySet 0;
BA_REL_ "GenSigTimeoutTime" BU_SG_REL_ SHVU_FR SG_ 1616 MKBD_SeatKeySet 0;
BA_ "Version" SG_ 1616 MKBD_SeatKeySet "20.06.07";
BA_ "GenMsgSendType" BO_ 2449771009 0;
BA_ "GenMsgCycleTime" BO_ 2449771009 1000;
BA_ "GenMsgCycleTimeFast" BO_ 2449771009 0;
BA_ "GenMsgNrOfRepetition" BO_ 2449771009 0;
BA_ "VFrameFormat" BO_ 2449771009 1;
BA_ "Description" SG_ 2449771009 ODS_Crc1Val "The data area for CRC calculation is based on the data length (DLC) of the message DB.

The CRC shall be calculated over the entire data block (excluding the CRC bytes) including the user data, alive counter and Data ID

 

- CRC Polynomial (0x1021) , Initial Value : 0xFFFF, XOR value : 0x0000, Data ID : Message ID + 0xF800 

- The initial value is for CRC calculation and the message should be sent with the calculated result value. 

- The mathematical expression to 16 bit CRC polynomial is given here. G(x) = x16 + x12 + x5 + 1";
BA_ "GenSigStartValue" SG_ 2449771009 ODS_Crc1Val 65535;
BA_ "UserSigValidity" SG_ 2449771009 ODS_Crc1Val 3;
BA_ "Version" SG_ 2449771009 ODS_Crc1Val "18.11.08";
BA_ "Description" SG_ 2449771009 ODS_AlvCnt1Val "For the first transmission request for a data element the counter shall be initialized with 0 and shall be incremented by 1 for every subsequent send request. 

When the counter reaches the maximum value(0xFF), then it shall restart with 0 for the next send request";
BA_ "UserSigValidity" SG_ 2449771009 ODS_AlvCnt1Val 3;
BA_ "Version" SG_ 2449771009 ODS_AlvCnt1Val "18.11.08";
BA_ "Description" SG_ 2449771009 ODS_IdVal "Information of Vehicle seat ID as defined by customer.



¡Ø Initial Value °ª(0x0) ¹«½Ã (Àü»ê ½Ã½ºÅÛ µî·Ï Â÷ ÀÓÀÇ·Î 0x0°ª µî·Ï)

: Initial(Start) Value : Current Value";
BA_ "UserSigValidity" SG_ 2449771009 ODS_IdVal 3;
BA_ "Version" SG_ 2449771009 ODS_IdVal "17.12.02";
BA_ "Description" SG_ 2449771009 ODS_OccClassSta "Signal Value Table : reference with ODS Communiction instruction";
BA_ "GenSigStartValue" SG_ 2449771009 ODS_OccClassSta 4;
BA_ "UserSigValidity" SG_ 2449771009 ODS_OccClassSta 3;
BA_REL_ "GenSigTimeoutTime" BU_SG_REL_ ATS SG_ 2449771009 ODS_OccClassSta 5000;
BA_REL_ "GenSigTimeoutTime" BU_SG_REL_ GW_APSU SG_ 2449771009 ODS_OccClassSta 5000;
BA_REL_ "GenSigTimeoutTime" BU_SG_REL_ GW_DPSU SG_ 2449771009 ODS_OccClassSta 5000;
BA_ "Version" SG_ 2449771009 ODS_OccClassSta "17.12.02";
BA_ "Description" SG_ 2449771009 ODS_DiagSta "CR_WCS_Errstat signal describes PODS-G & BOSE system error that is diagnosed by itself. Each Type set Diagnostic Status explains 3 kinds of fault.

[PODS-G]

Bit 1 : If ODS Have some errors, ODS set the bit, sends the ALR Defect signal to ACU and notifies the fault.

Bit 2 : If ODS Have some errors, ODS set the bit, sends the ECU Defect signal to ACU and notifies the fault.

Bit 5 : If ODS Have some errors, ODS set the bit, sends the EOL Error signal to ACU and notifies the fault.



[BOSE]

Bit 1 : If ODS Have some errors, ODS set the bit, sends the Mat Defect signal to ACU and notifies the fault.

Bit 2 : If ODS Have some errors, ODS set the bit, sends the ECU Defect signal to ACU and notifies the fault.

Bit 6 : If ODS Have some errors, ODS set the bit, sends the Algo Cut-off Error signal to ACU and notifies the fault.";
BA_ "UserSigValidity" SG_ 2449771009 ODS_DiagSta 3;
BA_ "Version" SG_ 2449771009 ODS_DiagSta "17.12.02";
BA_ "Description" SG_ 2449771009 ODS_SBRClassSta "Refer to Signal Value table";
BA_ "UserSigValidity" SG_ 2449771009 ODS_SBRClassSta 3;
BA_ "Version" SG_ 2449771009 ODS_SBRClassSta "19.05.02";
BA_ "GenMsgSendType" BO_ 2449771010 0;
BA_ "GenMsgCycleTime" BO_ 2449771010 1000;
BA_ "GenMsgCycleTimeFast" BO_ 2449771010 0;
BA_ "GenMsgNrOfRepetition" BO_ 2449771010 0;
BA_ "VFrameFormat" BO_ 2449771010 1;
BA_ "GenMsgCycleTime" BO_ 1578 0;
BA_ "GenMsgILSupport" BO_ 1578 0;
BA_ "TpMessage" BO_ 1578 1;
BA_ "GenMsgDelayTime" BO_ 1578 10;
BA_ "UsrSigPurpose" SG_ 1578 PSB_CCP_CRO_Byte0 0;
BA_ "GenSigSendType" SG_ 1578 PSB_CCP_CRO_Byte0 2;
BA_ "UserSigValidity" SG_ 1578 PSB_CCP_CRO_Byte0 0;
BA_REL_ "GenSigTimeoutTime" BU_SG_REL_ PSB SG_ 1578 PSB_CCP_CRO_Byte0 0;
BA_ "NetworkRequest" SG_ 1578 PSB_CCP_CRO_Byte0 0;
BA_ "NetworkRequestHoldingTime" SG_ 1578 PSB_CCP_CRO_Byte0 5000;
BA_ "Version" SG_ 1578 PSB_CCP_CRO_Byte0 "21.02.04";
BA_ "UsrSigPurpose" SG_ 1578 PSB_CCP_CRO_Byte2 0;
BA_ "GenSigSendType" SG_ 1578 PSB_CCP_CRO_Byte2 2;
BA_ "UserSigValidity" SG_ 1578 PSB_CCP_CRO_Byte2 0;
BA_REL_ "GenSigTimeoutTime" BU_SG_REL_ PSB SG_ 1578 PSB_CCP_CRO_Byte2 0;
BA_ "NetworkRequest" SG_ 1578 PSB_CCP_CRO_Byte2 0;
BA_ "NetworkRequestHoldingTime" SG_ 1578 PSB_CCP_CRO_Byte2 5000;
BA_ "Version" SG_ 1578 PSB_CCP_CRO_Byte2 "21.02.04";
BA_ "UsrSigPurpose" SG_ 1578 PSB_CCP_CRO_Byte3 0;
BA_ "GenSigSendType" SG_ 1578 PSB_CCP_CRO_Byte3 2;
BA_ "UserSigValidity" SG_ 1578 PSB_CCP_CRO_Byte3 0;
BA_REL_ "GenSigTimeoutTime" BU_SG_REL_ PSB SG_ 1578 PSB_CCP_CRO_Byte3 0;
BA_ "NetworkRequest" SG_ 1578 PSB_CCP_CRO_Byte3 0;
BA_ "NetworkRequestHoldingTime" SG_ 1578 PSB_CCP_CRO_Byte3 5000;
BA_ "Version" SG_ 1578 PSB_CCP_CRO_Byte3 "21.02.04";
BA_ "UsrSigPurpose" SG_ 1578 PSB_CCP_CRO_Byte4 0;
BA_ "GenSigSendType" SG_ 1578 PSB_CCP_CRO_Byte4 2;
BA_ "UserSigValidity" SG_ 1578 PSB_CCP_CRO_Byte4 0;
BA_REL_ "GenSigTimeoutTime" BU_SG_REL_ PSB SG_ 1578 PSB_CCP_CRO_Byte4 0;
BA_ "NetworkRequest" SG_ 1578 PSB_CCP_CRO_Byte4 0;
BA_ "NetworkRequestHoldingTime" SG_ 1578 PSB_CCP_CRO_Byte4 5000;
BA_ "Version" SG_ 1578 PSB_CCP_CRO_Byte4 "21.02.04";
BA_ "UsrSigPurpose" SG_ 1578 PSB_CCP_CRO_Byte5 0;
BA_ "GenSigSendType" SG_ 1578 PSB_CCP_CRO_Byte5 2;
BA_ "UserSigValidity" SG_ 1578 PSB_CCP_CRO_Byte5 0;
BA_REL_ "GenSigTimeoutTime" BU_SG_REL_ PSB SG_ 1578 PSB_CCP_CRO_Byte5 0;
BA_ "NetworkRequest" SG_ 1578 PSB_CCP_CRO_Byte5 0;
BA_ "NetworkRequestHoldingTime" SG_ 1578 PSB_CCP_CRO_Byte5 5000;
BA_ "Version" SG_ 1578 PSB_CCP_CRO_Byte5 "21.02.04";
BA_ "UsrSigPurpose" SG_ 1578 PSB_CCP_CRO_Byte6 0;
BA_ "GenSigSendType" SG_ 1578 PSB_CCP_CRO_Byte6 2;
BA_ "UserSigValidity" SG_ 1578 PSB_CCP_CRO_Byte6 0;
BA_REL_ "GenSigTimeoutTime" BU_SG_REL_ PSB SG_ 1578 PSB_CCP_CRO_Byte6 0;
BA_ "NetworkRequest" SG_ 1578 PSB_CCP_CRO_Byte6 0;
BA_ "NetworkRequestHoldingTime" SG_ 1578 PSB_CCP_CRO_Byte6 5000;
BA_ "Version" SG_ 1578 PSB_CCP_CRO_Byte6 "21.02.04";
BA_ "UsrSigPurpose" SG_ 1578 PSB_CCP_CRO_Byte7 0;
BA_ "GenSigSendType" SG_ 1578 PSB_CCP_CRO_Byte7 2;
BA_ "UserSigValidity" SG_ 1578 PSB_CCP_CRO_Byte7 0;
BA_REL_ "GenSigTimeoutTime" BU_SG_REL_ PSB SG_ 1578 PSB_CCP_CRO_Byte7 0;
BA_ "NetworkRequest" SG_ 1578 PSB_CCP_CRO_Byte7 0;
BA_ "NetworkRequestHoldingTime" SG_ 1578 PSB_CCP_CRO_Byte7 5000;
BA_ "Version" SG_ 1578 PSB_CCP_CRO_Byte7 "21.02.04";
BA_ "UsrSigPurpose" SG_ 1578 PSB_CCP_CRO_Byte1 0;
BA_ "GenSigSendType" SG_ 1578 PSB_CCP_CRO_Byte1 2;
BA_ "UserSigValidity" SG_ 1578 PSB_CCP_CRO_Byte1 0;
BA_REL_ "GenSigTimeoutTime" BU_SG_REL_ PSB SG_ 1578 PSB_CCP_CRO_Byte1 0;
BA_ "NetworkRequest" SG_ 1578 PSB_CCP_CRO_Byte1 0;
BA_ "NetworkRequestHoldingTime" SG_ 1578 PSB_CCP_CRO_Byte1 5000;
BA_ "Version" SG_ 1578 PSB_CCP_CRO_Byte1 "21.02.04";
BA_ "GenMsgCycleTime" BO_ 1579 0;
BA_ "GenMsgILSupport" BO_ 1579 0;
BA_ "TpMessage" BO_ 1579 1;
BA_ "GenMsgDelayTime" BO_ 1579 10;
BA_ "UsrSigPurpose" SG_ 1579 PSB_CCP_DTO_Byte0 0;
BA_ "GenSigSendType" SG_ 1579 PSB_CCP_DTO_Byte0 2;
BA_ "UserSigValidity" SG_ 1579 PSB_CCP_DTO_Byte0 0;
BA_REL_ "GenSigTimeoutTime" BU_SG_REL_ CGW_CCU SG_ 1579 PSB_CCP_DTO_Byte0 0;
BA_ "NetworkRequest" SG_ 1579 PSB_CCP_DTO_Byte0 0;
BA_ "NetworkRequestHoldingTime" SG_ 1579 PSB_CCP_DTO_Byte0 5000;
BA_ "Version" SG_ 1579 PSB_CCP_DTO_Byte0 "21.02.04";
BA_ "UsrSigPurpose" SG_ 1579 PSB_CCP_DTO_Byte2 0;
BA_ "GenSigSendType" SG_ 1579 PSB_CCP_DTO_Byte2 2;
BA_ "UserSigValidity" SG_ 1579 PSB_CCP_DTO_Byte2 0;
BA_REL_ "GenSigTimeoutTime" BU_SG_REL_ CGW_CCU SG_ 1579 PSB_CCP_DTO_Byte2 0;
BA_ "NetworkRequest" SG_ 1579 PSB_CCP_DTO_Byte2 0;
BA_ "NetworkRequestHoldingTime" SG_ 1579 PSB_CCP_DTO_Byte2 5000;
BA_ "Version" SG_ 1579 PSB_CCP_DTO_Byte2 "21.02.04";
BA_ "UsrSigPurpose" SG_ 1579 PSB_CCP_DTO_Byte3 0;
BA_ "GenSigSendType" SG_ 1579 PSB_CCP_DTO_Byte3 2;
BA_ "UserSigValidity" SG_ 1579 PSB_CCP_DTO_Byte3 0;
BA_REL_ "GenSigTimeoutTime" BU_SG_REL_ CGW_CCU SG_ 1579 PSB_CCP_DTO_Byte3 0;
BA_ "NetworkRequest" SG_ 1579 PSB_CCP_DTO_Byte3 0;
BA_ "NetworkRequestHoldingTime" SG_ 1579 PSB_CCP_DTO_Byte3 5000;
BA_ "Version" SG_ 1579 PSB_CCP_DTO_Byte3 "21.02.04";
BA_ "UsrSigPurpose" SG_ 1579 PSB_CCP_DTO_Byte4 0;
BA_ "GenSigSendType" SG_ 1579 PSB_CCP_DTO_Byte4 2;
BA_ "UserSigValidity" SG_ 1579 PSB_CCP_DTO_Byte4 0;
BA_REL_ "GenSigTimeoutTime" BU_SG_REL_ CGW_CCU SG_ 1579 PSB_CCP_DTO_Byte4 0;
BA_ "NetworkRequest" SG_ 1579 PSB_CCP_DTO_Byte4 0;
BA_ "NetworkRequestHoldingTime" SG_ 1579 PSB_CCP_DTO_Byte4 5000;
BA_ "Version" SG_ 1579 PSB_CCP_DTO_Byte4 "21.02.04";
BA_ "UsrSigPurpose" SG_ 1579 PSB_CCP_DTO_Byte5 0;
BA_ "GenSigSendType" SG_ 1579 PSB_CCP_DTO_Byte5 2;
BA_ "UserSigValidity" SG_ 1579 PSB_CCP_DTO_Byte5 0;
BA_REL_ "GenSigTimeoutTime" BU_SG_REL_ CGW_CCU SG_ 1579 PSB_CCP_DTO_Byte5 0;
BA_ "NetworkRequest" SG_ 1579 PSB_CCP_DTO_Byte5 0;
BA_ "NetworkRequestHoldingTime" SG_ 1579 PSB_CCP_DTO_Byte5 5000;
BA_ "Version" SG_ 1579 PSB_CCP_DTO_Byte5 "21.02.04";
BA_ "UsrSigPurpose" SG_ 1579 PSB_CCP_DTO_Byte6 0;
BA_ "GenSigSendType" SG_ 1579 PSB_CCP_DTO_Byte6 2;
BA_ "UserSigValidity" SG_ 1579 PSB_CCP_DTO_Byte6 0;
BA_REL_ "GenSigTimeoutTime" BU_SG_REL_ CGW_CCU SG_ 1579 PSB_CCP_DTO_Byte6 0;
BA_ "NetworkRequest" SG_ 1579 PSB_CCP_DTO_Byte6 0;
BA_ "NetworkRequestHoldingTime" SG_ 1579 PSB_CCP_DTO_Byte6 5000;
BA_ "Version" SG_ 1579 PSB_CCP_DTO_Byte6 "21.02.04";
BA_ "UsrSigPurpose" SG_ 1579 PSB_CCP_DTO_Byte7 0;
BA_ "GenSigSendType" SG_ 1579 PSB_CCP_DTO_Byte7 2;
BA_ "UserSigValidity" SG_ 1579 PSB_CCP_DTO_Byte7 0;
BA_REL_ "GenSigTimeoutTime" BU_SG_REL_ CGW_CCU SG_ 1579 PSB_CCP_DTO_Byte7 0;
BA_ "NetworkRequest" SG_ 1579 PSB_CCP_DTO_Byte7 0;
BA_ "NetworkRequestHoldingTime" SG_ 1579 PSB_CCP_DTO_Byte7 5000;
BA_ "Version" SG_ 1579 PSB_CCP_DTO_Byte7 "21.02.04";
BA_ "UsrSigPurpose" SG_ 1579 PSB_CCP_DTO_Byte1 0;
BA_ "GenSigSendType" SG_ 1579 PSB_CCP_DTO_Byte1 2;
BA_ "UserSigValidity" SG_ 1579 PSB_CCP_DTO_Byte1 0;
BA_REL_ "GenSigTimeoutTime" BU_SG_REL_ CGW_CCU SG_ 1579 PSB_CCP_DTO_Byte1 0;
BA_ "NetworkRequest" SG_ 1579 PSB_CCP_DTO_Byte1 0;
BA_ "NetworkRequestHoldingTime" SG_ 1579 PSB_CCP_DTO_Byte1 5000;
BA_ "Version" SG_ 1579 PSB_CCP_DTO_Byte1 "21.02.04";
BA_ "GenMsgSendType" BO_ 553 0;
BA_ "Description" SG_ 553 PSS_RL_LumbarUpSw "PSS_RL_LumbarUpSwMoveButton";
BA_ "GenSigSendType" SG_ 553 PSS_RL_LumbarUpSw 4;
BA_ "UserSigValidity" SG_ 553 PSS_RL_LumbarUpSw 0;
BA_REL_ "GenSigTimeoutTime" BU_SG_REL_ DSAU SG_ 553 PSS_RL_LumbarUpSw 1500;
BA_REL_ "GenSigTimeoutTime" BU_SG_REL_ GW_DLBCU SG_ 553 PSS_RL_LumbarUpSw 1500;
BA_REL_ "GenSigTimeoutTime" BU_SG_REL_ CGW_CCU SG_ 553 PSS_RL_LumbarUpSw 1500;
BA_ "NetworkRequest" SG_ 553 PSS_RL_LumbarUpSw 0;
BA_ "NetworkRequestHoldingTime" SG_ 553 PSS_RL_LumbarUpSw 5000;
BA_ "Version" SG_ 553 PSS_RL_LumbarUpSw "22.10.20";
BA_ "Description" SG_ 553 PSS_RL_BolsterDefSw "PSS_RL_BolsterBwdMoveButton";
BA_ "GenSigSendType" SG_ 553 PSS_RL_BolsterDefSw 4;
BA_ "UserSigValidity" SG_ 553 PSS_RL_BolsterDefSw 0;
BA_REL_ "GenSigTimeoutTime" BU_SG_REL_ DSAU SG_ 553 PSS_RL_BolsterDefSw 1500;
BA_REL_ "GenSigTimeoutTime" BU_SG_REL_ GW_DLBCU SG_ 553 PSS_RL_BolsterDefSw 1500;
BA_REL_ "GenSigTimeoutTime" BU_SG_REL_ CGW_CCU SG_ 553 PSS_RL_BolsterDefSw 1500;
BA_ "NetworkRequest" SG_ 553 PSS_RL_BolsterDefSw 0;
BA_ "NetworkRequestHoldingTime" SG_ 553 PSS_RL_BolsterDefSw 5000;
BA_ "Version" SG_ 553 PSS_RL_BolsterDefSw "22.10.20";
BA_ "Description" SG_ 553 PSS_RL_ActiveSw "PSS_RL_ActiveSw";
BA_ "GenSigSendType" SG_ 553 PSS_RL_ActiveSw 4;
BA_ "UserSigValidity" SG_ 553 PSS_RL_ActiveSw 0;
BA_REL_ "GenSigTimeoutTime" BU_SG_REL_ DSAU SG_ 553 PSS_RL_ActiveSw 1500;
BA_REL_ "GenSigTimeoutTime" BU_SG_REL_ GW_DLBCU SG_ 553 PSS_RL_ActiveSw 1500;
BA_REL_ "GenSigTimeoutTime" BU_SG_REL_ CGW_CCU SG_ 553 PSS_RL_ActiveSw 1500;
BA_ "NetworkRequest" SG_ 553 PSS_RL_ActiveSw 0;
BA_ "NetworkRequestHoldingTime" SG_ 553 PSS_RL_ActiveSw 5000;
BA_ "Version" SG_ 553 PSS_RL_ActiveSw "22.10.20";
BA_ "Description" SG_ 553 PSS_RL_LumbarMidSw "PSS_RL_LumbarFwdSwMoveButton";
BA_ "GenSigSendType" SG_ 553 PSS_RL_LumbarMidSw 4;
BA_ "UserSigValidity" SG_ 553 PSS_RL_LumbarMidSw 0;
BA_REL_ "GenSigTimeoutTime" BU_SG_REL_ DSAU SG_ 553 PSS_RL_LumbarMidSw 1500;
BA_REL_ "GenSigTimeoutTime" BU_SG_REL_ GW_DLBCU SG_ 553 PSS_RL_LumbarMidSw 1500;
BA_REL_ "GenSigTimeoutTime" BU_SG_REL_ CGW_CCU SG_ 553 PSS_RL_LumbarMidSw 1500;
BA_ "NetworkRequest" SG_ 553 PSS_RL_LumbarMidSw 0;
BA_ "NetworkRequestHoldingTime" SG_ 553 PSS_RL_LumbarMidSw 5000;
BA_ "Version" SG_ 553 PSS_RL_LumbarMidSw "22.10.20";
BA_ "Description" SG_ 553 PSS_RL_LumbarLowSw "PSS_RL_LumbarDnSwMoveButton";
BA_ "GenSigSendType" SG_ 553 PSS_RL_LumbarLowSw 4;
BA_ "UserSigValidity" SG_ 553 PSS_RL_LumbarLowSw 0;
BA_REL_ "GenSigTimeoutTime" BU_SG_REL_ DSAU SG_ 553 PSS_RL_LumbarLowSw 1500;
BA_REL_ "GenSigTimeoutTime" BU_SG_REL_ GW_DLBCU SG_ 553 PSS_RL_LumbarLowSw 1500;
BA_REL_ "GenSigTimeoutTime" BU_SG_REL_ CGW_CCU SG_ 553 PSS_RL_LumbarLowSw 1500;
BA_ "NetworkRequest" SG_ 553 PSS_RL_LumbarLowSw 0;
BA_ "NetworkRequestHoldingTime" SG_ 553 PSS_RL_LumbarLowSw 5000;
BA_ "Version" SG_ 553 PSS_RL_LumbarLowSw "22.10.20";
BA_ "Description" SG_ 553 PSS_RL_LumbarDefSw "PSS_RL_LumbarBwdSwMoveButton";
BA_ "GenSigSendType" SG_ 553 PSS_RL_LumbarDefSw 4;
BA_ "UserSigValidity" SG_ 553 PSS_RL_LumbarDefSw 0;
BA_REL_ "GenSigTimeoutTime" BU_SG_REL_ DSAU SG_ 553 PSS_RL_LumbarDefSw 1500;
BA_REL_ "GenSigTimeoutTime" BU_SG_REL_ GW_DLBCU SG_ 553 PSS_RL_LumbarDefSw 1500;
BA_REL_ "GenSigTimeoutTime" BU_SG_REL_ CGW_CCU SG_ 553 PSS_RL_LumbarDefSw 1500;
BA_ "NetworkRequest" SG_ 553 PSS_RL_LumbarDefSw 0;
BA_ "NetworkRequestHoldingTime" SG_ 553 PSS_RL_LumbarDefSw 5000;
BA_ "Version" SG_ 553 PSS_RL_LumbarDefSw "22.10.20";
BA_ "Description" SG_ 553 PSS_RL_BolsterInfSw "PSS_RL_BolsterFwdMoveButton";
BA_ "GenSigSendType" SG_ 553 PSS_RL_BolsterInfSw 4;
BA_ "UserSigValidity" SG_ 553 PSS_RL_BolsterInfSw 0;
BA_REL_ "GenSigTimeoutTime" BU_SG_REL_ DSAU SG_ 553 PSS_RL_BolsterInfSw 1500;
BA_REL_ "GenSigTimeoutTime" BU_SG_REL_ GW_DLBCU SG_ 553 PSS_RL_BolsterInfSw 1500;
BA_REL_ "GenSigTimeoutTime" BU_SG_REL_ CGW_CCU SG_ 553 PSS_RL_BolsterInfSw 1500;
BA_ "NetworkRequest" SG_ 553 PSS_RL_BolsterInfSw 0;
BA_ "NetworkRequestHoldingTime" SG_ 553 PSS_RL_BolsterInfSw 5000;
BA_ "Version" SG_ 553 PSS_RL_BolsterInfSw "22.10.20";
BA_ "GenMsgSendType" BO_ 630 0;
BA_ "Description" SG_ 630 PSS_RR_StSldFwdMvBtn "PSS_RR_SlideForwardMoveButton";
BA_ "GenSigSendType" SG_ 630 PSS_RR_StSldFwdMvBtn 4;
BA_ "UserSigValidity" SG_ 630 PSS_RR_StSldFwdMvBtn 0;
BA_REL_ "GenSigTimeoutTime" BU_SG_REL_ CGW_CCU SG_ 630 PSS_RR_StSldFwdMvBtn 1500;
BA_ "NetworkRequest" SG_ 630 PSS_RR_StSldFwdMvBtn 0;
BA_ "NetworkRequestHoldingTime" SG_ 630 PSS_RR_StSldFwdMvBtn 5000;
BA_ "Version" SG_ 630 PSS_RR_StSldFwdMvBtn "22.10.20";
BA_ "Description" SG_ 630 PSS_RR_StTltDnMvBtn "PSS_RR_TiltDownMoveButton";
BA_ "GenSigSendType" SG_ 630 PSS_RR_StTltDnMvBtn 4;
BA_ "UserSigValidity" SG_ 630 PSS_RR_StTltDnMvBtn 0;
BA_REL_ "GenSigTimeoutTime" BU_SG_REL_ CGW_CCU SG_ 630 PSS_RR_StTltDnMvBtn 1500;
BA_ "NetworkRequest" SG_ 630 PSS_RR_StTltDnMvBtn 0;
BA_ "NetworkRequestHoldingTime" SG_ 630 PSS_RR_StTltDnMvBtn 5000;
BA_ "Version" SG_ 630 PSS_RR_StTltDnMvBtn "22.10.20";
BA_ "Description" SG_ 630 PSS_RR_StHRestUpMvBtn "PSS_RR_StHRestUpMvBtn";
BA_ "GenSigSendType" SG_ 630 PSS_RR_StHRestUpMvBtn 4;
BA_ "UserSigValidity" SG_ 630 PSS_RR_StHRestUpMvBtn 0;
BA_REL_ "GenSigTimeoutTime" BU_SG_REL_ CGW_CCU SG_ 630 PSS_RR_StHRestUpMvBtn 1500;
BA_ "NetworkRequest" SG_ 630 PSS_RR_StHRestUpMvBtn 0;
BA_ "NetworkRequestHoldingTime" SG_ 630 PSS_RR_StHRestUpMvBtn 5000;
BA_ "Version" SG_ 630 PSS_RR_StHRestUpMvBtn "22.10.20";
BA_ "Description" SG_ 630 PSS_RR_StHRestDnMvBtn "PSS_RR_StHRestDnMvBtn";
BA_ "GenSigSendType" SG_ 630 PSS_RR_StHRestDnMvBtn 4;
BA_ "UserSigValidity" SG_ 630 PSS_RR_StHRestDnMvBtn 0;
BA_REL_ "GenSigTimeoutTime" BU_SG_REL_ CGW_CCU SG_ 630 PSS_RR_StHRestDnMvBtn 1500;
BA_ "NetworkRequest" SG_ 630 PSS_RR_StHRestDnMvBtn 0;
BA_ "NetworkRequestHoldingTime" SG_ 630 PSS_RR_StHRestDnMvBtn 5000;
BA_ "Version" SG_ 630 PSS_RR_StHRestDnMvBtn "22.10.20";
BA_ "Description" SG_ 630 PSS_RR_StHRestFwdMvBtn "PSS_RR_StHRestFwdMvBtn";
BA_ "GenSigSendType" SG_ 630 PSS_RR_StHRestFwdMvBtn 4;
BA_ "UserSigValidity" SG_ 630 PSS_RR_StHRestFwdMvBtn 0;
BA_REL_ "GenSigTimeoutTime" BU_SG_REL_ CGW_CCU SG_ 630 PSS_RR_StHRestFwdMvBtn 1500;
BA_ "NetworkRequest" SG_ 630 PSS_RR_StHRestFwdMvBtn 0;
BA_ "NetworkRequestHoldingTime" SG_ 630 PSS_RR_StHRestFwdMvBtn 5000;
BA_ "Version" SG_ 630 PSS_RR_StHRestFwdMvBtn "22.10.20";
BA_ "Description" SG_ 630 PSS_RR_StHRestBwdMvBtn "PSS_RR_StHRestBwdMvBtn";
BA_ "GenSigSendType" SG_ 630 PSS_RR_StHRestBwdMvBtn 4;
BA_ "UserSigValidity" SG_ 630 PSS_RR_StHRestBwdMvBtn 0;
BA_REL_ "GenSigTimeoutTime" BU_SG_REL_ CGW_CCU SG_ 630 PSS_RR_StHRestBwdMvBtn 1500;
BA_ "NetworkRequest" SG_ 630 PSS_RR_StHRestBwdMvBtn 0;
BA_ "NetworkRequestHoldingTime" SG_ 630 PSS_RR_StHRestBwdMvBtn 5000;
BA_ "Version" SG_ 630 PSS_RR_StHRestBwdMvBtn "22.10.20";
BA_ "Description" SG_ 630 PSS_RR_StSldBwdMvBtn "PSS_RR_SlideBackwardMoveButton";
BA_ "GenSigSendType" SG_ 630 PSS_RR_StSldBwdMvBtn 4;
BA_ "UserSigValidity" SG_ 630 PSS_RR_StSldBwdMvBtn 0;
BA_REL_ "GenSigTimeoutTime" BU_SG_REL_ CGW_CCU SG_ 630 PSS_RR_StSldBwdMvBtn 1500;
BA_ "NetworkRequest" SG_ 630 PSS_RR_StSldBwdMvBtn 0;
BA_ "NetworkRequestHoldingTime" SG_ 630 PSS_RR_StSldBwdMvBtn 5000;
BA_ "Version" SG_ 630 PSS_RR_StSldBwdMvBtn "22.10.20";
BA_ "Description" SG_ 630 PSS_RR_StLegRestUpBtn "PSS_RR_LegUpMoveButton";
BA_ "GenSigSendType" SG_ 630 PSS_RR_StLegRestUpBtn 4;
BA_ "UserSigValidity" SG_ 630 PSS_RR_StLegRestUpBtn 0;
BA_REL_ "GenSigTimeoutTime" BU_SG_REL_ CGW_CCU SG_ 630 PSS_RR_StLegRestUpBtn 1500;
BA_ "NetworkRequest" SG_ 630 PSS_RR_StLegRestUpBtn 0;
BA_ "NetworkRequestHoldingTime" SG_ 630 PSS_RR_StLegRestUpBtn 5000;
BA_ "Version" SG_ 630 PSS_RR_StLegRestUpBtn "22.10.20";
BA_ "Description" SG_ 630 PSS_RR_StLegRestDnBtn "PSS_RR_LegDownMoveButton";
BA_ "GenSigSendType" SG_ 630 PSS_RR_StLegRestDnBtn 4;
BA_ "UserSigValidity" SG_ 630 PSS_RR_StLegRestDnBtn 0;
BA_REL_ "GenSigTimeoutTime" BU_SG_REL_ CGW_CCU SG_ 630 PSS_RR_StLegRestDnBtn 1500;
BA_ "NetworkRequest" SG_ 630 PSS_RR_StLegRestDnBtn 0;
BA_ "NetworkRequestHoldingTime" SG_ 630 PSS_RR_StLegRestDnBtn 5000;
BA_ "Version" SG_ 630 PSS_RR_StLegRestDnBtn "22.10.20";
BA_ "Description" SG_ 630 PSS_RR_StLegRestExtFwdBtn "PSS_RR_LegExtFwdMoveButton";
BA_ "GenSigSendType" SG_ 630 PSS_RR_StLegRestExtFwdBtn 4;
BA_ "UserSigValidity" SG_ 630 PSS_RR_StLegRestExtFwdBtn 0;
BA_REL_ "GenSigTimeoutTime" BU_SG_REL_ CGW_CCU SG_ 630 PSS_RR_StLegRestExtFwdBtn 1500;
BA_ "NetworkRequest" SG_ 630 PSS_RR_StLegRestExtFwdBtn 0;
BA_ "NetworkRequestHoldingTime" SG_ 630 PSS_RR_StLegRestExtFwdBtn 5000;
BA_ "Version" SG_ 630 PSS_RR_StLegRestExtFwdBtn "22.11.09";
BA_ "Description" SG_ 630 PSS_RR_StLegRestExtBwdBtn "PSS_RR_LegExtBwdMoveButton";
BA_ "GenSigSendType" SG_ 630 PSS_RR_StLegRestExtBwdBtn 4;
BA_ "UserSigValidity" SG_ 630 PSS_RR_StLegRestExtBwdBtn 0;
BA_REL_ "GenSigTimeoutTime" BU_SG_REL_ CGW_CCU SG_ 630 PSS_RR_StLegRestExtBwdBtn 1500;
BA_ "NetworkRequest" SG_ 630 PSS_RR_StLegRestExtBwdBtn 0;
BA_ "NetworkRequestHoldingTime" SG_ 630 PSS_RR_StLegRestExtBwdBtn 5000;
BA_ "Version" SG_ 630 PSS_RR_StLegRestExtBwdBtn "22.11.09";
BA_ "Description" SG_ 630 PSS_RR_StRlxModeBtn "PSS_RR_RelaxModeButton";
BA_ "GenSigSendType" SG_ 630 PSS_RR_StRlxModeBtn 4;
BA_ "UserSigValidity" SG_ 630 PSS_RR_StRlxModeBtn 0;
BA_REL_ "GenSigTimeoutTime" BU_SG_REL_ CGW_CCU SG_ 630 PSS_RR_StRlxModeBtn 1500;
BA_ "NetworkRequest" SG_ 630 PSS_RR_StRlxModeBtn 0;
BA_ "NetworkRequestHoldingTime" SG_ 630 PSS_RR_StRlxModeBtn 5000;
BA_ "Version" SG_ 630 PSS_RR_StRlxModeBtn "22.10.20";
BA_ "Description" SG_ 630 PSS_RR_StRlxReturnBtn "PSS_RR_RelaxReturnButton";
BA_ "GenSigSendType" SG_ 630 PSS_RR_StRlxReturnBtn 4;
BA_ "UserSigValidity" SG_ 630 PSS_RR_StRlxReturnBtn 0;
BA_REL_ "GenSigTimeoutTime" BU_SG_REL_ CGW_CCU SG_ 630 PSS_RR_StRlxReturnBtn 1500;
BA_ "NetworkRequest" SG_ 630 PSS_RR_StRlxReturnBtn 0;
BA_ "NetworkRequestHoldingTime" SG_ 630 PSS_RR_StRlxReturnBtn 5000;
BA_ "Version" SG_ 630 PSS_RR_StRlxReturnBtn "22.10.20";
BA_ "Description" SG_ 630 PSS_RR_StRlxTltUpMvBtn "PSS_RR_RelaxTiltUpMoveButton";
BA_ "GenSigSendType" SG_ 630 PSS_RR_StRlxTltUpMvBtn 4;
BA_ "UserSigValidity" SG_ 630 PSS_RR_StRlxTltUpMvBtn 0;
BA_REL_ "GenSigTimeoutTime" BU_SG_REL_ CGW_CCU SG_ 630 PSS_RR_StRlxTltUpMvBtn 1500;
BA_ "NetworkRequest" SG_ 630 PSS_RR_StRlxTltUpMvBtn 0;
BA_ "NetworkRequestHoldingTime" SG_ 630 PSS_RR_StRlxTltUpMvBtn 5000;
BA_ "Version" SG_ 630 PSS_RR_StRlxTltUpMvBtn "22.10.20";
BA_ "Description" SG_ 630 PSS_RR_StRlxTltDnMvBtn "PSS_RR_RelaxTiltDownMoveButton";
BA_ "GenSigSendType" SG_ 630 PSS_RR_StRlxTltDnMvBtn 4;
BA_ "UserSigValidity" SG_ 630 PSS_RR_StRlxTltDnMvBtn 0;
BA_REL_ "GenSigTimeoutTime" BU_SG_REL_ CGW_CCU SG_ 630 PSS_RR_StRlxTltDnMvBtn 1500;
BA_ "NetworkRequest" SG_ 630 PSS_RR_StRlxTltDnMvBtn 0;
BA_ "NetworkRequestHoldingTime" SG_ 630 PSS_RR_StRlxTltDnMvBtn 5000;
BA_ "Version" SG_ 630 PSS_RR_StRlxTltDnMvBtn "22.10.20";
BA_ "Description" SG_ 630 PSS_RR_StMnlRlxModeBtn "PSS_RR_MnlRelaxModeButton";
BA_ "GenSigSendType" SG_ 630 PSS_RR_StMnlRlxModeBtn 4;
BA_ "UserSigValidity" SG_ 630 PSS_RR_StMnlRlxModeBtn 0;
BA_REL_ "GenSigTimeoutTime" BU_SG_REL_ CGW_CCU SG_ 630 PSS_RR_StMnlRlxModeBtn 1500;
BA_ "NetworkRequest" SG_ 630 PSS_RR_StMnlRlxModeBtn 0;
BA_ "NetworkRequestHoldingTime" SG_ 630 PSS_RR_StMnlRlxModeBtn 5000;
BA_ "Version" SG_ 630 PSS_RR_StMnlRlxModeBtn "22.10.20";
BA_ "Description" SG_ 630 PSS_RR_StMnlRlxReturnBtn "PSS_RR_MnlRelaxReturnButton";
BA_ "GenSigSendType" SG_ 630 PSS_RR_StMnlRlxReturnBtn 4;
BA_ "UserSigValidity" SG_ 630 PSS_RR_StMnlRlxReturnBtn 0;
BA_REL_ "GenSigTimeoutTime" BU_SG_REL_ CGW_CCU SG_ 630 PSS_RR_StMnlRlxReturnBtn 1500;
BA_ "NetworkRequest" SG_ 630 PSS_RR_StMnlRlxReturnBtn 0;
BA_ "NetworkRequestHoldingTime" SG_ 630 PSS_RR_StMnlRlxReturnBtn 5000;
BA_ "Version" SG_ 630 PSS_RR_StMnlRlxReturnBtn "22.10.20";
BA_ "Description" SG_ 630 PSS_RR_StRclFwdMvBtn "PSS_RR_ReclinerForwardMoveButton";
BA_ "GenSigSendType" SG_ 630 PSS_RR_StRclFwdMvBtn 4;
BA_ "UserSigValidity" SG_ 630 PSS_RR_StRclFwdMvBtn 0;
BA_REL_ "GenSigTimeoutTime" BU_SG_REL_ CGW_CCU SG_ 630 PSS_RR_StRclFwdMvBtn 1500;
BA_ "NetworkRequest" SG_ 630 PSS_RR_StRclFwdMvBtn 0;
BA_ "NetworkRequestHoldingTime" SG_ 630 PSS_RR_StRclFwdMvBtn 5000;
BA_ "Version" SG_ 630 PSS_RR_StRclFwdMvBtn "22.10.20";
BA_ "Description" SG_ 630 PSS_RR_WalkInSwitchSts "PSS_RR_WalkInSwitchStatus";
BA_ "GenSigSendType" SG_ 630 PSS_RR_WalkInSwitchSts 4;
BA_ "UserSigValidity" SG_ 630 PSS_RR_WalkInSwitchSts 0;
BA_REL_ "GenSigTimeoutTime" BU_SG_REL_ CGW_CCU SG_ 630 PSS_RR_WalkInSwitchSts 1500;
BA_ "NetworkRequest" SG_ 630 PSS_RR_WalkInSwitchSts 0;
BA_ "NetworkRequestHoldingTime" SG_ 630 PSS_RR_WalkInSwitchSts 5000;
BA_ "Version" SG_ 630 PSS_RR_WalkInSwitchSts "22.10.20";
BA_ "Description" SG_ 630 PSS_RR_StRclBwdMvBtn "PSS_RR_ReclinerBackwardMoveButton";
BA_ "GenSigSendType" SG_ 630 PSS_RR_StRclBwdMvBtn 4;
BA_ "UserSigValidity" SG_ 630 PSS_RR_StRclBwdMvBtn 0;
BA_REL_ "GenSigTimeoutTime" BU_SG_REL_ CGW_CCU SG_ 630 PSS_RR_StRclBwdMvBtn 1500;
BA_ "NetworkRequest" SG_ 630 PSS_RR_StRclBwdMvBtn 0;
BA_ "NetworkRequestHoldingTime" SG_ 630 PSS_RR_StRclBwdMvBtn 5000;
BA_ "Version" SG_ 630 PSS_RR_StRclBwdMvBtn "22.10.20";
BA_ "Description" SG_ 630 PSS_RR_StTltUpMvBtn "PSS_RR_TiltUpMoveButton";
BA_ "GenSigSendType" SG_ 630 PSS_RR_StTltUpMvBtn 4;
BA_ "UserSigValidity" SG_ 630 PSS_RR_StTltUpMvBtn 0;
BA_REL_ "GenSigTimeoutTime" BU_SG_REL_ CGW_CCU SG_ 630 PSS_RR_StTltUpMvBtn 1500;
BA_ "NetworkRequest" SG_ 630 PSS_RR_StTltUpMvBtn 0;
BA_ "NetworkRequestHoldingTime" SG_ 630 PSS_RR_StTltUpMvBtn 5000;
BA_ "Version" SG_ 630 PSS_RR_StTltUpMvBtn "22.10.20";
BA_ "GenMsgSendType" BO_ 631 0;
BA_ "Description" SG_ 631 PSS_RR_StOneTchWlkinCushBtn "PSS_RR_OnetouchWalkinCushMoveButton";
BA_ "GenSigSendType" SG_ 631 PSS_RR_StOneTchWlkinCushBtn 4;
BA_ "UserSigValidity" SG_ 631 PSS_RR_StOneTchWlkinCushBtn 0;
BA_REL_ "GenSigTimeoutTime" BU_SG_REL_ CGW_CCU SG_ 631 PSS_RR_StOneTchWlkinCushBtn 1500;
BA_ "NetworkRequest" SG_ 631 PSS_RR_StOneTchWlkinCushBtn 0;
BA_ "NetworkRequestHoldingTime" SG_ 631 PSS_RR_StOneTchWlkinCushBtn 5000;
BA_ "Version" SG_ 631 PSS_RR_StOneTchWlkinCushBtn "22.10.20";
BA_ "Description" SG_ 631 PSS_RR_StOneTchWlkinBackBtn "PSS_RR_OnetouchWalkinBackMoveButton";
BA_ "GenSigSendType" SG_ 631 PSS_RR_StOneTchWlkinBackBtn 4;
BA_ "UserSigValidity" SG_ 631 PSS_RR_StOneTchWlkinBackBtn 0;
BA_REL_ "GenSigTimeoutTime" BU_SG_REL_ CGW_CCU SG_ 631 PSS_RR_StOneTchWlkinBackBtn 1500;
BA_ "NetworkRequest" SG_ 631 PSS_RR_StOneTchWlkinBackBtn 0;
BA_ "NetworkRequestHoldingTime" SG_ 631 PSS_RR_StOneTchWlkinBackBtn 5000;
BA_ "Version" SG_ 631 PSS_RR_StOneTchWlkinBackBtn "22.10.20";
BA_ "Description" SG_ 631 PSS_RR_MomoryP1Cmd "PSS_RR_SeatPositionMemoryP1Request";
BA_ "GenSigSendType" SG_ 631 PSS_RR_MomoryP1Cmd 4;
BA_ "UserSigValidity" SG_ 631 PSS_RR_MomoryP1Cmd 0;
BA_REL_ "GenSigTimeoutTime" BU_SG_REL_ CGW_CCU SG_ 631 PSS_RR_MomoryP1Cmd 1500;
BA_ "NetworkRequest" SG_ 631 PSS_RR_MomoryP1Cmd 0;
BA_ "NetworkRequestHoldingTime" SG_ 631 PSS_RR_MomoryP1Cmd 5000;
BA_ "Version" SG_ 631 PSS_RR_MomoryP1Cmd "22.10.20";
BA_ "Description" SG_ 631 PSS_RR_MomoryP2Cmd "PSS_RR_SeatPositionMemoryP2Request";
BA_ "GenSigSendType" SG_ 631 PSS_RR_MomoryP2Cmd 4;
BA_ "UserSigValidity" SG_ 631 PSS_RR_MomoryP2Cmd 0;
BA_REL_ "GenSigTimeoutTime" BU_SG_REL_ CGW_CCU SG_ 631 PSS_RR_MomoryP2Cmd 1500;
BA_ "NetworkRequest" SG_ 631 PSS_RR_MomoryP2Cmd 0;
BA_ "NetworkRequestHoldingTime" SG_ 631 PSS_RR_MomoryP2Cmd 5000;
BA_ "Version" SG_ 631 PSS_RR_MomoryP2Cmd "22.10.20";
BA_ "GenMsgSendType" BO_ 632 0;
BA_ "Description" SG_ 632 PSS_RR_AstHRestFwdMvBtn "PSS_RR_AstStHead Rest UpMoveButton";
BA_ "GenSigSendType" SG_ 632 PSS_RR_AstHRestFwdMvBtn 4;
BA_ "UserSigValidity" SG_ 632 PSS_RR_AstHRestFwdMvBtn 0;
BA_REL_ "GenSigTimeoutTime" BU_SG_REL_ CGW_CCU SG_ 632 PSS_RR_AstHRestFwdMvBtn 1500;
BA_ "NetworkRequest" SG_ 632 PSS_RR_AstHRestFwdMvBtn 0;
BA_ "NetworkRequestHoldingTime" SG_ 632 PSS_RR_AstHRestFwdMvBtn 5000;
BA_ "Version" SG_ 632 PSS_RR_AstHRestFwdMvBtn "22.10.20";
BA_ "Description" SG_ 632 PSS_RR_AstRclBwdMvBtn "PSS_RR_AstStReclinerBackwardMoveButton";
BA_ "GenSigSendType" SG_ 632 PSS_RR_AstRclBwdMvBtn 4;
BA_ "UserSigValidity" SG_ 632 PSS_RR_AstRclBwdMvBtn 0;
BA_REL_ "GenSigTimeoutTime" BU_SG_REL_ CGW_CCU SG_ 632 PSS_RR_AstRclBwdMvBtn 1500;
BA_ "NetworkRequest" SG_ 632 PSS_RR_AstRclBwdMvBtn 0;
BA_ "NetworkRequestHoldingTime" SG_ 632 PSS_RR_AstRclBwdMvBtn 5000;
BA_ "Version" SG_ 632 PSS_RR_AstRclBwdMvBtn "22.10.20";
BA_ "Description" SG_ 632 PSS_RR_AstSldFwdMvBtn "PSS_RR_AstStSlideForwardMoveButton";
BA_ "GenSigSendType" SG_ 632 PSS_RR_AstSldFwdMvBtn 4;
BA_ "UserSigValidity" SG_ 632 PSS_RR_AstSldFwdMvBtn 0;
BA_REL_ "GenSigTimeoutTime" BU_SG_REL_ CGW_CCU SG_ 632 PSS_RR_AstSldFwdMvBtn 1500;
BA_ "NetworkRequest" SG_ 632 PSS_RR_AstSldFwdMvBtn 0;
BA_ "NetworkRequestHoldingTime" SG_ 632 PSS_RR_AstSldFwdMvBtn 5000;
BA_ "Version" SG_ 632 PSS_RR_AstSldFwdMvBtn "22.10.20";
BA_ "Description" SG_ 632 PSS_RR_AstSldBwdMvBtn "PSS_RR_AstStSlideBackwardMoveButton";
BA_ "GenSigSendType" SG_ 632 PSS_RR_AstSldBwdMvBtn 4;
BA_ "UserSigValidity" SG_ 632 PSS_RR_AstSldBwdMvBtn 0;
BA_REL_ "GenSigTimeoutTime" BU_SG_REL_ CGW_CCU SG_ 632 PSS_RR_AstSldBwdMvBtn 1500;
BA_ "NetworkRequest" SG_ 632 PSS_RR_AstSldBwdMvBtn 0;
BA_ "NetworkRequestHoldingTime" SG_ 632 PSS_RR_AstSldBwdMvBtn 5000;
BA_ "Version" SG_ 632 PSS_RR_AstSldBwdMvBtn "22.10.20";
BA_ "Description" SG_ 632 PSS_RR_AstHgtUpMvBtn "PSS_RR_AstStHeightUpMoveButton";
BA_ "GenSigSendType" SG_ 632 PSS_RR_AstHgtUpMvBtn 4;
BA_ "UserSigValidity" SG_ 632 PSS_RR_AstHgtUpMvBtn 0;
BA_REL_ "GenSigTimeoutTime" BU_SG_REL_ CGW_CCU SG_ 632 PSS_RR_AstHgtUpMvBtn 1500;
BA_ "NetworkRequest" SG_ 632 PSS_RR_AstHgtUpMvBtn 0;
BA_ "NetworkRequestHoldingTime" SG_ 632 PSS_RR_AstHgtUpMvBtn 5000;
BA_ "Version" SG_ 632 PSS_RR_AstHgtUpMvBtn "22.10.20";
BA_ "Description" SG_ 632 PSS_RR_AstHgtDnMvBtn "PSS_RR_AstStHeightDownMoveButton";
BA_ "GenSigSendType" SG_ 632 PSS_RR_AstHgtDnMvBtn 4;
BA_ "UserSigValidity" SG_ 632 PSS_RR_AstHgtDnMvBtn 0;
BA_REL_ "GenSigTimeoutTime" BU_SG_REL_ CGW_CCU SG_ 632 PSS_RR_AstHgtDnMvBtn 1500;
BA_ "NetworkRequest" SG_ 632 PSS_RR_AstHgtDnMvBtn 0;
BA_ "NetworkRequestHoldingTime" SG_ 632 PSS_RR_AstHgtDnMvBtn 5000;
BA_ "Version" SG_ 632 PSS_RR_AstHgtDnMvBtn "22.10.20";
BA_ "Description" SG_ 632 PSS_RR_AstHRestBwdMvBtn "PSS_RR_AstStHead Rest DownMoveButton";
BA_ "GenSigSendType" SG_ 632 PSS_RR_AstHRestBwdMvBtn 4;
BA_ "UserSigValidity" SG_ 632 PSS_RR_AstHRestBwdMvBtn 0;
BA_REL_ "GenSigTimeoutTime" BU_SG_REL_ CGW_CCU SG_ 632 PSS_RR_AstHRestBwdMvBtn 1500;
BA_ "NetworkRequest" SG_ 632 PSS_RR_AstHRestBwdMvBtn 0;
BA_ "NetworkRequestHoldingTime" SG_ 632 PSS_RR_AstHRestBwdMvBtn 5000;
BA_ "Version" SG_ 632 PSS_RR_AstHRestBwdMvBtn "22.10.20";
BA_ "Description" SG_ 632 PSS_RR_AstFRestOpenMvBtn "PSS_RR_AstStFootrestOpenButton";
BA_ "GenSigSendType" SG_ 632 PSS_RR_AstFRestOpenMvBtn 4;
BA_ "UserSigValidity" SG_ 632 PSS_RR_AstFRestOpenMvBtn 0;
BA_REL_ "GenSigTimeoutTime" BU_SG_REL_ CGW_CCU SG_ 632 PSS_RR_AstFRestOpenMvBtn 1500;
BA_ "NetworkRequest" SG_ 632 PSS_RR_AstFRestOpenMvBtn 0;
BA_ "NetworkRequestHoldingTime" SG_ 632 PSS_RR_AstFRestOpenMvBtn 5000;
BA_ "Version" SG_ 632 PSS_RR_AstFRestOpenMvBtn "22.10.20";
BA_ "Description" SG_ 632 PSS_RR_AstFRestCloseMvBtn "PSS_RR_AstStFootrestCloseButton";
BA_ "GenSigSendType" SG_ 632 PSS_RR_AstFRestCloseMvBtn 4;
BA_ "UserSigValidity" SG_ 632 PSS_RR_AstFRestCloseMvBtn 0;
BA_REL_ "GenSigTimeoutTime" BU_SG_REL_ CGW_CCU SG_ 632 PSS_RR_AstFRestCloseMvBtn 1500;
BA_ "NetworkRequest" SG_ 632 PSS_RR_AstFRestCloseMvBtn 0;
BA_ "NetworkRequestHoldingTime" SG_ 632 PSS_RR_AstFRestCloseMvBtn 5000;
BA_ "Version" SG_ 632 PSS_RR_AstFRestCloseMvBtn "22.10.20";
BA_ "Description" SG_ 632 PSS_RR_AstHRestUpMvBtn "PSS_RR_AstStHead Rest ForwardMoveButton";
BA_ "GenSigSendType" SG_ 632 PSS_RR_AstHRestUpMvBtn 4;
BA_ "UserSigValidity" SG_ 632 PSS_RR_AstHRestUpMvBtn 0;
BA_REL_ "GenSigTimeoutTime" BU_SG_REL_ CGW_CCU SG_ 632 PSS_RR_AstHRestUpMvBtn 1500;
BA_ "NetworkRequest" SG_ 632 PSS_RR_AstHRestUpMvBtn 0;
BA_ "NetworkRequestHoldingTime" SG_ 632 PSS_RR_AstHRestUpMvBtn 5000;
BA_ "Version" SG_ 632 PSS_RR_AstHRestUpMvBtn "22.10.20";
BA_ "Description" SG_ 632 PSS_RR_AstHRestDnMvBtn "PSS_RR_AstStHead Rest BackwardMoveButton";
BA_ "GenSigSendType" SG_ 632 PSS_RR_AstHRestDnMvBtn 4;
BA_ "UserSigValidity" SG_ 632 PSS_RR_AstHRestDnMvBtn 0;
BA_REL_ "GenSigTimeoutTime" BU_SG_REL_ CGW_CCU SG_ 632 PSS_RR_AstHRestDnMvBtn 1500;
BA_ "NetworkRequest" SG_ 632 PSS_RR_AstHRestDnMvBtn 0;
BA_ "NetworkRequestHoldingTime" SG_ 632 PSS_RR_AstHRestDnMvBtn 5000;
BA_ "Version" SG_ 632 PSS_RR_AstHRestDnMvBtn "22.10.20";
BA_ "Description" SG_ 632 PSS_RR_AstRclFwdMvBtn "PSS_RR_AstStReclinerForwardMoveButton";
BA_ "GenSigSendType" SG_ 632 PSS_RR_AstRclFwdMvBtn 4;
BA_ "UserSigValidity" SG_ 632 PSS_RR_AstRclFwdMvBtn 0;
BA_REL_ "GenSigTimeoutTime" BU_SG_REL_ CGW_CCU SG_ 632 PSS_RR_AstRclFwdMvBtn 1500;
BA_ "NetworkRequest" SG_ 632 PSS_RR_AstRclFwdMvBtn 0;
BA_ "NetworkRequestHoldingTime" SG_ 632 PSS_RR_AstRclFwdMvBtn 5000;
BA_ "Version" SG_ 632 PSS_RR_AstRclFwdMvBtn "22.10.20";
BA_ "GenMsgSendType" BO_ 633 0;
BA_ "Description" SG_ 633 PSS_RR_LumbarUpSw "PSS_RR_LumbarUpSwMoveButton";
BA_ "GenSigSendType" SG_ 633 PSS_RR_LumbarUpSw 4;
BA_ "UserSigValidity" SG_ 633 PSS_RR_LumbarUpSw 0;
BA_REL_ "GenSigTimeoutTime" BU_SG_REL_ DSAU SG_ 633 PSS_RR_LumbarUpSw 1500;
BA_REL_ "GenSigTimeoutTime" BU_SG_REL_ GW_DLBCU SG_ 633 PSS_RR_LumbarUpSw 1500;
BA_REL_ "GenSigTimeoutTime" BU_SG_REL_ CGW_CCU SG_ 633 PSS_RR_LumbarUpSw 1500;
BA_ "NetworkRequest" SG_ 633 PSS_RR_LumbarUpSw 0;
BA_ "NetworkRequestHoldingTime" SG_ 633 PSS_RR_LumbarUpSw 5000;
BA_ "Version" SG_ 633 PSS_RR_LumbarUpSw "22.10.20";
BA_ "Description" SG_ 633 PSS_RR_BolsterDefSw "PSS_RR_BolsterBwdMoveButton";
BA_ "GenSigSendType" SG_ 633 PSS_RR_BolsterDefSw 4;
BA_ "UserSigValidity" SG_ 633 PSS_RR_BolsterDefSw 0;
BA_REL_ "GenSigTimeoutTime" BU_SG_REL_ DSAU SG_ 633 PSS_RR_BolsterDefSw 1500;
BA_REL_ "GenSigTimeoutTime" BU_SG_REL_ GW_DLBCU SG_ 633 PSS_RR_BolsterDefSw 1500;
BA_REL_ "GenSigTimeoutTime" BU_SG_REL_ CGW_CCU SG_ 633 PSS_RR_BolsterDefSw 1500;
BA_ "NetworkRequest" SG_ 633 PSS_RR_BolsterDefSw 0;
BA_ "NetworkRequestHoldingTime" SG_ 633 PSS_RR_BolsterDefSw 5000;
BA_ "Version" SG_ 633 PSS_RR_BolsterDefSw "22.10.20";
BA_ "Description" SG_ 633 PSS_RR_ActiveSw "PSS_RR_ActiveSw";
BA_ "GenSigSendType" SG_ 633 PSS_RR_ActiveSw 4;
BA_ "UserSigValidity" SG_ 633 PSS_RR_ActiveSw 0;
BA_REL_ "GenSigTimeoutTime" BU_SG_REL_ DSAU SG_ 633 PSS_RR_ActiveSw 1500;
BA_REL_ "GenSigTimeoutTime" BU_SG_REL_ GW_DLBCU SG_ 633 PSS_RR_ActiveSw 1500;
BA_REL_ "GenSigTimeoutTime" BU_SG_REL_ CGW_CCU SG_ 633 PSS_RR_ActiveSw 1500;
BA_ "NetworkRequest" SG_ 633 PSS_RR_ActiveSw 0;
BA_ "NetworkRequestHoldingTime" SG_ 633 PSS_RR_ActiveSw 5000;
BA_ "Version" SG_ 633 PSS_RR_ActiveSw "22.10.20";
BA_ "Description" SG_ 633 PSS_RR_LumbarMidSw "PSS_RR_LumbarFwdSwMoveButton";
BA_ "GenSigSendType" SG_ 633 PSS_RR_LumbarMidSw 4;
BA_ "UserSigValidity" SG_ 633 PSS_RR_LumbarMidSw 0;
BA_REL_ "GenSigTimeoutTime" BU_SG_REL_ DSAU SG_ 633 PSS_RR_LumbarMidSw 1500;
BA_REL_ "GenSigTimeoutTime" BU_SG_REL_ GW_DLBCU SG_ 633 PSS_RR_LumbarMidSw 1500;
BA_REL_ "GenSigTimeoutTime" BU_SG_REL_ CGW_CCU SG_ 633 PSS_RR_LumbarMidSw 1500;
BA_ "NetworkRequest" SG_ 633 PSS_RR_LumbarMidSw 0;
BA_ "NetworkRequestHoldingTime" SG_ 633 PSS_RR_LumbarMidSw 5000;
BA_ "Version" SG_ 633 PSS_RR_LumbarMidSw "22.10.20";
BA_ "Description" SG_ 633 PSS_RR_LumbarLowSw "PSS_RR_LumbarDnSwMoveButton";
BA_ "GenSigSendType" SG_ 633 PSS_RR_LumbarLowSw 4;
BA_ "UserSigValidity" SG_ 633 PSS_RR_LumbarLowSw 0;
BA_REL_ "GenSigTimeoutTime" BU_SG_REL_ DSAU SG_ 633 PSS_RR_LumbarLowSw 1500;
BA_REL_ "GenSigTimeoutTime" BU_SG_REL_ GW_DLBCU SG_ 633 PSS_RR_LumbarLowSw 1500;
BA_REL_ "GenSigTimeoutTime" BU_SG_REL_ CGW_CCU SG_ 633 PSS_RR_LumbarLowSw 1500;
BA_ "NetworkRequest" SG_ 633 PSS_RR_LumbarLowSw 0;
BA_ "NetworkRequestHoldingTime" SG_ 633 PSS_RR_LumbarLowSw 5000;
BA_ "Version" SG_ 633 PSS_RR_LumbarLowSw "22.10.20";
BA_ "Description" SG_ 633 PSS_RR_LumbarDefSw "PSS_RR_LumbarBwdSwMoveButton";
BA_ "GenSigSendType" SG_ 633 PSS_RR_LumbarDefSw 4;
BA_ "UserSigValidity" SG_ 633 PSS_RR_LumbarDefSw 0;
BA_REL_ "GenSigTimeoutTime" BU_SG_REL_ DSAU SG_ 633 PSS_RR_LumbarDefSw 1500;
BA_REL_ "GenSigTimeoutTime" BU_SG_REL_ GW_DLBCU SG_ 633 PSS_RR_LumbarDefSw 1500;
BA_REL_ "GenSigTimeoutTime" BU_SG_REL_ CGW_CCU SG_ 633 PSS_RR_LumbarDefSw 1500;
BA_ "NetworkRequest" SG_ 633 PSS_RR_LumbarDefSw 0;
BA_ "NetworkRequestHoldingTime" SG_ 633 PSS_RR_LumbarDefSw 5000;
BA_ "Version" SG_ 633 PSS_RR_LumbarDefSw "22.10.20";
BA_ "Description" SG_ 633 PSS_RR_BolsterInfSw "PSS_RR_BolsterFwdMoveButton";
BA_ "GenSigSendType" SG_ 633 PSS_RR_BolsterInfSw 4;
BA_ "UserSigValidity" SG_ 633 PSS_RR_BolsterInfSw 0;
BA_REL_ "GenSigTimeoutTime" BU_SG_REL_ DSAU SG_ 633 PSS_RR_BolsterInfSw 1500;
BA_REL_ "GenSigTimeoutTime" BU_SG_REL_ GW_DLBCU SG_ 633 PSS_RR_BolsterInfSw 1500;
BA_REL_ "GenSigTimeoutTime" BU_SG_REL_ CGW_CCU SG_ 633 PSS_RR_BolsterInfSw 1500;
BA_ "NetworkRequest" SG_ 633 PSS_RR_BolsterInfSw 0;
BA_ "NetworkRequestHoldingTime" SG_ 633 PSS_RR_BolsterInfSw 5000;
BA_ "Version" SG_ 633 PSS_RR_BolsterInfSw "22.10.20";
BA_ "GenMsgSendType" BO_ 2244048385 0;
BA_ "GenMsgCycleTime" BO_ 2244048385 100;
BA_ "GenMsgCycleTimeFast" BO_ 2244048385 0;
BA_ "GenMsgNrOfRepetition" BO_ 2244048385 0;
BA_ "VFrameFormat" BO_ 2244048385 1;
BA_ "Description" SG_ 2244048385 RCU_Crc3Val "The data area for CRC calculation is based on the data length (DLC) of the message DB.

The CRC shall be calculated over the entire data block (excluding the CRC bytes) including the user data, alive counter and Data ID



- CRC Polynomial (0x1021) , Initial Value : 0xFFFF, XOR value : 0x0000, Data ID : Message ID + 0xF800 

- The initial value is for CRC calculation and the message should be sent with the calculated result value. 

- The mathematical expression to 16 bit CRC polynomial is given here. G(x) = x16 + x12 + x5 + 1



<For CRC calculation of CAN-FD Msg for HS CAN domain ECUs>



- HS-CAN Messages that routed from CAN-FD domain are using 29 bit Extended CAN ID and splitted into 8 Byte Messages.

(from 1 to 4 Msgs, depending on source CAN-FD Msg¡¯s DLC)

- For splitted CAN-FD Msgs¡¯ CRC calculation, HS CAN ECUs should use source CAN-FD Msg¡¯s original STD ID. 

- The original STD ID can be read from Ext ID¡¯s 4~6th Byte.

Eg. STD 0x6AA : EXT SPLT 0x1A8[6AA]01 / 0x1A8[6AA]02 / 0x1A8[6AA]03 / 0x1A8[6AA]04 

(2~4th splitited Msgs can be omitted depending on source CAN-FD Msg¡¯s DLC)

- Aslo, HS-CAN ECUs should use merged data block (from whole splitted Msg) for CRC calculation.";
BA_ "GenSigStartValue" SG_ 2244048385 RCU_Crc3Val 65535;
BA_ "UserSigValidity" SG_ 2244048385 RCU_Crc3Val 3;
BA_ "RoutingFactor" SG_ 2244048385 RCU_Crc3Val 5;
BA_ "Version" SG_ 2244048385 RCU_Crc3Val "22.01.00";
BA_ "Description" SG_ 2244048385 RCU_AlvCnt3Val "For the first transmission request for a data element the counter shall be initialized with 0 and shall be incremented by 1 for every subsequent send request. 

When the counter reaches the maximum value(0xFF), then it shall restart with 0 for the next send request";
BA_ "UserSigValidity" SG_ 2244048385 RCU_AlvCnt3Val 3;
BA_ "RoutingFactor" SG_ 2244048385 RCU_AlvCnt3Val 5;
BA_ "Version" SG_ 2244048385 RCU_AlvCnt3Val "22.01.00";
BA_ "Description" SG_ 2244048385 RCU_HDP_FltMonSta "This signal is the result of the RCU monitoring the state of the HDP controller (Main/Sub).";
BA_ "UserSigValidity" SG_ 2244048385 RCU_HDP_FltMonSta 3;
BA_ "RoutingFactor" SG_ 2244048385 RCU_HDP_FltMonSta 5;
BA_ "Version" SG_ 2244048385 RCU_HDP_FltMonSta "22.01.00";
BA_ "Description" SG_ 2244048385 RCU_HDP_EgSta "This signal is the information which of the HDP controllers (Main/Sub) the IEB (ESC)/RCU is engaged.";
BA_ "UserSigValidity" SG_ 2244048385 RCU_HDP_EgSta 0;
BA_REL_ "GenSigTimeoutTime" BU_SG_REL_ PSB SG_ 2244048385 RCU_HDP_EgSta 1500;
BA_ "RoutingFactor" SG_ 2244048385 RCU_HDP_EgSta 5;
BA_ "Version" SG_ 2244048385 RCU_HDP_EgSta "22.05.03";
BA_ "Description" SG_ 2244048385 RCU_Sta "EBS Ready Status

¡Ø Used 0x0 (Not Ready) / 0x1(Ready), if there is no distinction between the front and rear wheels

     : ex) Front axle regen wheel, 0x0 : Front not Ready / 0x1: Front only Ready";
BA_ "UserSigValidity" SG_ 2244048385 RCU_Sta 3;
BA_ "RoutingFactor" SG_ 2244048385 RCU_Sta 5;
BA_ "Version" SG_ 2244048385 RCU_Sta "22.10.19";
BA_ "Description" SG_ 2244048385 RCU_HDP_EnblReq "This signal is a fault state of the RCU for the HDP function.";
BA_ "UserSigValidity" SG_ 2244048385 RCU_HDP_EnblReq 3;
BA_ "RoutingFactor" SG_ 2244048385 RCU_HDP_EnblReq 5;
BA_ "Version" SG_ 2244048385 RCU_HDP_EnblReq "22.01.00";
BA_ "UserSigValidity" SG_ 2244048385 RCU_AD3_RCUFltSta 3;
BA_ "RoutingFactor" SG_ 2244048385 RCU_AD3_RCUFltSta 5;
BA_ "Version" SG_ 2244048385 RCU_AD3_RCUFltSta "22.01.00";
BA_ "Description" SG_ 2244048385 RCU_AD3_AWD_FastOpnCrdnShftCltchReq "Interface signal between RCU and 4WD, demands fast opening or torque limit of the 4WD cardan shaft clutch.";
BA_ "UserSigValidity" SG_ 2244048385 RCU_AD3_AWD_FastOpnCrdnShftCltchReq 3;
BA_ "RoutingFactor" SG_ 2244048385 RCU_AD3_AWD_FastOpnCrdnShftCltchReq 5;
BA_ "Version" SG_ 2244048385 RCU_AD3_AWD_FastOpnCrdnShftCltchReq "22.01.00";
BA_ "Description" SG_ 2244048385 RCU_AD3_StrkDpthmmVal "The signal indicates the depth of brake pedal (RCU Pedal - PTS2)";
BA_ "UserSigValidity" SG_ 2244048385 RCU_AD3_StrkDpthmmVal 3;
BA_ "RoutingFactor" SG_ 2244048385 RCU_AD3_StrkDpthmmVal 5;
BA_ "Version" SG_ 2244048385 RCU_AD3_StrkDpthmmVal "22.04.01";
BA_ "Description" SG_ 2244048385 RCU_AD3_PdlTrvlSnsrValVldSta "Information regarding the pedal travel sensor value validity status (RCU Pedal - PTS2)";
BA_ "UserSigValidity" SG_ 2244048385 RCU_AD3_PdlTrvlSnsrValVldSta 3;
BA_ "RoutingFactor" SG_ 2244048385 RCU_AD3_PdlTrvlSnsrValVldSta 5;
BA_ "Version" SG_ 2244048385 RCU_AD3_PdlTrvlSnsrValVldSta "22.04.01";
BA_ "Description" SG_ 2244048385 RCU_AD3_PdlCalibSta "Information regarding the pedal travel sensor¡¯s calibration status (RCU Pedal - PTS2)";
BA_ "UserSigValidity" SG_ 2244048385 RCU_AD3_PdlCalibSta 3;
BA_ "RoutingFactor" SG_ 2244048385 RCU_AD3_PdlCalibSta 5;
BA_ "Version" SG_ 2244048385 RCU_AD3_PdlCalibSta "22.04.01";
BA_ "Description" SG_ 2244048385 RCU_AD3_TCS_MtrTrgtRpm_Flag_Frnt "This signal means +,- sign of the target RPM signal (TCS_MtrTrgtRpm_Frnt) of the front wheel motor during TCS operation of the RCU_03_20ms message";
BA_ "UserSigValidity" SG_ 2244048385 RCU_AD3_TCS_MtrTrgtRpm_Flag_Frnt 3;
BA_ "RoutingFactor" SG_ 2244048385 RCU_AD3_TCS_MtrTrgtRpm_Flag_Frnt 5;
BA_ "Version" SG_ 2244048385 RCU_AD3_TCS_MtrTrgtRpm_Flag_Frnt "22.10.19";
BA_ "Description" SG_ 2244048385 RCU_AD3_TCS_MtrTrgtRpm_Flag_Rear "This signal means +,- sign of the target RPM signal (TCS_MtrTrgtRpm_Rear) of the front wheel motor during TCS operation of the RCU_03_20ms message";
BA_ "UserSigValidity" SG_ 2244048385 RCU_AD3_TCS_MtrTrgtRpm_Flag_Rear 3;
BA_ "RoutingFactor" SG_ 2244048385 RCU_AD3_TCS_MtrTrgtRpm_Flag_Rear 5;
BA_ "Version" SG_ 2244048385 RCU_AD3_TCS_MtrTrgtRpm_Flag_Rear "22.10.19";
BA_ "Description" SG_ 2244048385 RCU_AD3_WSSmode "This signal indicates RCU support WSS or Not ( not each wss validity )";
BA_ "UserSigValidity" SG_ 2244048385 RCU_AD3_WSSmode 3;
BA_ "RoutingFactor" SG_ 2244048385 RCU_AD3_WSSmode 5;
BA_ "Version" SG_ 2244048385 RCU_AD3_WSSmode "22.01.00";
BA_ "GenMsgSendType" BO_ 2244048386 0;
BA_ "GenMsgCycleTime" BO_ 2244048386 100;
BA_ "GenMsgCycleTimeFast" BO_ 2244048386 0;
BA_ "GenMsgNrOfRepetition" BO_ 2244048386 0;
BA_ "VFrameFormat" BO_ 2244048386 1;
BA_ "UserSigValidity" SG_ 2244048386 RCU_AD3_Wss2FlFltSta 3;
BA_ "RoutingFactor" SG_ 2244048386 RCU_AD3_Wss2FlFltSta 5;
BA_ "Version" SG_ 2244048386 RCU_AD3_Wss2FlFltSta "22.01.00";
BA_ "Description" SG_ 2244048386 RCU_AD3_DiagSta "Information regarding the ¡°diagnostic mode¡± indication. (RCU)";
BA_ "UserSigValidity" SG_ 2244048386 RCU_AD3_DiagSta 3;
BA_ "RoutingFactor" SG_ 2244048386 RCU_AD3_DiagSta 5;
BA_ "Version" SG_ 2244048386 RCU_AD3_DiagSta "22.01.00";
BA_ "UserSigValidity" SG_ 2244048386 RCU_AD3_operation 3;
BA_ "RoutingFactor" SG_ 2244048386 RCU_AD3_operation 5;
BA_ "Version" SG_ 2244048386 RCU_AD3_operation "22.01.00";
BA_ "Description" SG_ 2244048386 RCU_AD3_PrsrValVldSta "This signal indicates validity of 'RCU_PrsrVal' signal.";
BA_ "GenSigStartValue" SG_ 2244048386 RCU_AD3_PrsrValVldSta 1;
BA_ "UserSigValidity" SG_ 2244048386 RCU_AD3_PrsrValVldSta 3;
BA_ "RoutingFactor" SG_ 2244048386 RCU_AD3_PrsrValVldSta 5;
BA_ "Version" SG_ 2244048386 RCU_AD3_PrsrValVldSta "22.04.01";
BA_ "Description" SG_ 2244048386 RCU_AD3_PrsrVal "This signal indicates RCU front circuit pressure Value.";
BA_ "UserSigValidity" SG_ 2244048386 RCU_AD3_PrsrVal 3;
BA_ "RoutingFactor" SG_ 2244048386 RCU_AD3_PrsrVal 5;
BA_ "Version" SG_ 2244048386 RCU_AD3_PrsrVal "22.04.01";
BA_ "UserSigValidity" SG_ 2244048386 RCU_AD3_Wss2FrFltSta 3;
BA_ "RoutingFactor" SG_ 2244048386 RCU_AD3_Wss2FrFltSta 5;
BA_ "Version" SG_ 2244048386 RCU_AD3_Wss2FrFltSta "22.01.00";
BA_ "Description" SG_ 2244048386 RCU_AD3_ABS_DfctvSta "Information regarding the ABS 'defective' indication. (RCU)";
BA_ "UserSigValidity" SG_ 2244048386 RCU_AD3_ABS_DfctvSta 3;
BA_ "RoutingFactor" SG_ 2244048386 RCU_AD3_ABS_DfctvSta 5;
BA_ "Version" SG_ 2244048386 RCU_AD3_ABS_DfctvSta "22.01.00";
BA_ "Description" SG_ 2244048386 RCU_AD3_ABS_ActvSta "information on ABS Active signal. (RCU)";
BA_ "UserSigValidity" SG_ 2244048386 RCU_AD3_ABS_ActvSta 3;
BA_ "RoutingFactor" SG_ 2244048386 RCU_AD3_ABS_ActvSta 5;
BA_ "Version" SG_ 2244048386 RCU_AD3_ABS_ActvSta "22.01.00";
BA_ "Description" SG_ 2244048386 RCU_AD3_BBC_DfctvSta "Information regarding the BBC 'defective' indication. (RCU)";
BA_ "UserSigValidity" SG_ 2244048386 RCU_AD3_BBC_DfctvSta 3;
BA_ "RoutingFactor" SG_ 2244048386 RCU_AD3_BBC_DfctvSta 5;
BA_ "Version" SG_ 2244048386 RCU_AD3_BBC_DfctvSta "22.01.00";
BA_ "Description" SG_ 2244048386 RCU_AD3_BBC_ActvSta "information on BBC Active signal. (RCU)";
BA_ "UserSigValidity" SG_ 2244048386 RCU_AD3_BBC_ActvSta 3;
BA_ "RoutingFactor" SG_ 2244048386 RCU_AD3_BBC_ActvSta 5;
BA_ "Version" SG_ 2244048386 RCU_AD3_BBC_ActvSta "22.01.00";
BA_ "UserSigValidity" SG_ 2244048386 RCU_AD3_Wss2RlFltSta 3;
BA_ "RoutingFactor" SG_ 2244048386 RCU_AD3_Wss2RlFltSta 5;
BA_ "Version" SG_ 2244048386 RCU_AD3_Wss2RlFltSta "22.01.00";
BA_ "Description" SG_ 2244048386 RCU_AD3_BrkLtActSta "Flag which activates the illumination of the brake lights during automatic braking. (RCU)";
BA_ "UserSigValidity" SG_ 2244048386 RCU_AD3_BrkLtActSta 0;
BA_ "RoutingFactor" SG_ 2244048386 RCU_AD3_BrkLtActSta 5;
BA_ "Version" SG_ 2244048386 RCU_AD3_BrkLtActSta "22.01.00";
BA_ "Description" SG_ 2244048386 RCU_AD3_DrvOvrdSta "This signal indicates that acceleration or deceleration value of driver¡¯s requirement is greater than SCC setting value. (RCU)";
BA_ "UserSigValidity" SG_ 2244048386 RCU_AD3_DrvOvrdSta 3;
BA_ "RoutingFactor" SG_ 2244048386 RCU_AD3_DrvOvrdSta 5;
BA_ "Version" SG_ 2244048386 RCU_AD3_DrvOvrdSta "22.01.00";
BA_ "Description" SG_ 2244048386 RCU_AD3_PrkBrkActvSta "This signal indicates whether the parking brake is activated or not. (RCU)";
BA_ "UserSigValidity" SG_ 2244048386 RCU_AD3_PrkBrkActvSta 3;
BA_ "RoutingFactor" SG_ 2244048386 RCU_AD3_PrkBrkActvSta 5;
BA_ "Version" SG_ 2244048386 RCU_AD3_PrkBrkActvSta "22.01.00";
BA_ "Description" SG_ 2244048386 RCU_AD3_FCA_AvlblSta "This signal indicates state signal from RCU to FCA which tells if RCU is 'Available', 'Temporarily not available', 'Permanently not available' or 'FCA Communication Error'.";
BA_ "UserSigValidity" SG_ 2244048386 RCU_AD3_FCA_AvlblSta 3;
BA_ "RoutingFactor" SG_ 2244048386 RCU_AD3_FCA_AvlblSta 5;
BA_ "Version" SG_ 2244048386 RCU_AD3_FCA_AvlblSta "22.01.00";
BA_ "Description" SG_ 2244048386 RCU_AD3_MSR_TqIntrvntnVal "Request for an indicated desired engine torque, the combination of signals calls, on the one hand, for a desire for charge reduction (TCS or ESC function), and, on the other hand, for a desire for charge increase (MSR function).



TQI_MSR : The torque increase according to TQI_MSR is accomplished in the EMS via the idle-charge actuator (limited by the maximum air flow of the idle-charge actuator) or electrical throttle controller (DIESEL : increase of fuel injection) up to the driving torque range.



TCS function:

In the case of a torque reduction, following conditions must be fulfilled. : 

TCS_REQ=1, MSR_C_REQ=0, TQI_TCS < 0FFH and TQI_MSR = 00H



MSR function :

 In the case of a torque increase, following conditions must be fulfilled. : 

 MSR_C_REQ = 1, TCS_REQ = 0, TQI_MSR > 00H and TQI_TCS = 1¡¯s complement of TQI_MSR 



The specified torque TQI_x is referred to a maximum torque TQ_STND. From this conversion into a physical quantity results a range of 0..99.6094% for TQ_STND.";
BA_ "UserSigValidity" SG_ 2244048386 RCU_AD3_MSR_TqIntrvntnVal 3;
BA_ "RoutingFactor" SG_ 2244048386 RCU_AD3_MSR_TqIntrvntnVal 5;
BA_ "Version" SG_ 2244048386 RCU_AD3_MSR_TqIntrvntnVal "22.01.00";
BA_ "Description" SG_ 2244048386 RCU_AD3_TCS_TqIntrvntnVal "Request for an indicated desired engine torque, the combination of signals calls, on the one hand, for a desire for charge reduction (TCS or ESC function), and, on the other hand, for a desire for charge increase (MSR function).



TQI_TCS : Torque reduction according to TQI_TCS is accomplished in the EMS by different methodes depending on the type of engine (Diesel, Gasoline, with or without ETC). Possible methodes are the reduction of airflow into the engine cylinders, the ignition angle adjustment and/or shutdown of cylinders and the reduction of injection etc. Torque reduction down to the engine drag torque range has to be possible



TCS function:

In the case of a torque reduction, following conditions must be fulfilled. : 

TCS_REQ=1, MSR_C_REQ=0, TQI_TCS < 0FFH and TQI_MSR = 00H



MSR function :

 In the case of a torque increase, following conditions must be fulfilled. : 

 MSR_C_REQ = 1, TCS_REQ = 0, TQI_MSR > 00H and TQI_TCS = 1¡¯s complement of TQI_MSR 



The specified torque TQI_x is referred to a maximum torque TQ_STND. From this conversion into a physical quantity results a range of 0..99.6094% for TQ_STND.";
BA_ "GenSigStartValue" SG_ 2244048386 RCU_AD3_TCS_TqIntrvntnVal 255;
BA_ "UserSigValidity" SG_ 2244048386 RCU_AD3_TCS_TqIntrvntnVal 3;
BA_ "RoutingFactor" SG_ 2244048386 RCU_AD3_TCS_TqIntrvntnVal 5;
BA_ "Version" SG_ 2244048386 RCU_AD3_TCS_TqIntrvntnVal "22.01.00";
BA_ "UserSigValidity" SG_ 2244048386 RCU_AD3_Wss2RrFltSta 3;
BA_ "RoutingFactor" SG_ 2244048386 RCU_AD3_Wss2RrFltSta 5;
BA_ "Version" SG_ 2244048386 RCU_AD3_Wss2RrFltSta "22.01.00";
BA_ "Description" SG_ 2244048386 RCU_AD3_SrvLmpDis "The signal indicates the status of the ¡°RCU Service lamp¡±";
BA_ "UserSigValidity" SG_ 2244048386 RCU_AD3_SrvLmpDis 3;
BA_ "RoutingFactor" SG_ 2244048386 RCU_AD3_SrvLmpDis 5;
BA_ "Version" SG_ 2244048386 RCU_AD3_SrvLmpDis "22.04.01";
BA_ "GenMsgSendType" BO_ 2244048387 0;
BA_ "GenMsgCycleTime" BO_ 2244048387 100;
BA_ "GenMsgCycleTimeFast" BO_ 2244048387 0;
BA_ "GenMsgNrOfRepetition" BO_ 2244048387 0;
BA_ "VFrameFormat" BO_ 2244048387 1;
BA_ "Description" SG_ 2244048387 RCU_AD3_SCC_TqIntrvntnVal "The indicated torque command TQI_ACC is the basic control path to the engine power control. This command has the same priority in the torque-structure than the driver¡¯s demand torque. The maximum value of either TQI_ACC or the driver torque is selected fo";
BA_ "UserSigValidity" SG_ 2244048387 RCU_AD3_SCC_TqIntrvntnVal 3;
BA_ "RoutingFactor" SG_ 2244048387 RCU_AD3_SCC_TqIntrvntnVal 5;
BA_ "Version" SG_ 2244048387 RCU_AD3_SCC_TqIntrvntnVal "22.01.00";
BA_ "Description" SG_ 2244048387 RCU_AD3_TCS_TqFlag "Flag indicating positive or negative TCS Intervention. (RCU)";
BA_ "UserSigValidity" SG_ 2244048387 RCU_AD3_TCS_TqFlag 3;
BA_ "RoutingFactor" SG_ 2244048387 RCU_AD3_TCS_TqFlag 5;
BA_ "Version" SG_ 2244048387 RCU_AD3_TCS_TqFlag "22.01.00";
BA_ "Description" SG_ 2244048387 RCU_AD3_TCS_Sta "Information regarding the status of TCS function. (RCU)

If the function has not been coded(fixed) yet, this signal will be transmitted as 0xE.";
BA_ "UserSigValidity" SG_ 2244048387 RCU_AD3_TCS_Sta 3;
BA_ "RoutingFactor" SG_ 2244048387 RCU_AD3_TCS_Sta 5;
BA_ "Version" SG_ 2244048387 RCU_AD3_TCS_Sta "22.01.00";
BA_ "Description" SG_ 2244048387 RCU_AD3_VehAccelVal "The vehicle acceleration ACCEL_REF_ACC displays the feedback signal for the inner acceleration control loop since it is the SCC-internal acceleration command value. In addition this signal is used to calculate the target object acceleration. If the requirements demanded from this signal can¡¯t be guaranteed then SCC must be informed and SCC has to be switched off.

Alternatively SCC may calculate the vehicle acceleration itself. Then the wheel speed vxvTyrexx (or the wheel speed row signals vxvTyreRawxx and the wheel tolerances radTolxx of below diagram) should be

transmitted by TCS or ESC.";
BA_ "UserSigValidity" SG_ 2244048387 RCU_AD3_VehAccelVal 3;
BA_ "RoutingFactor" SG_ 2244048387 RCU_AD3_VehAccelVal 5;
BA_ "Version" SG_ 2244048387 RCU_AD3_VehAccelVal "22.01.00";
BA_ "Description" SG_ 2244048387 RCU_AD3_MSR_TqFlag "Flag indicating positive or negative MSR Intervention. (RCU)";
BA_ "UserSigValidity" SG_ 2244048387 RCU_AD3_MSR_TqFlag 3;
BA_ "RoutingFactor" SG_ 2244048387 RCU_AD3_MSR_TqFlag 5;
BA_ "Version" SG_ 2244048387 RCU_AD3_MSR_TqFlag "22.01.00";
BA_ "Description" SG_ 2244048387 RCU_AD3_LDM_Sta "Information about RCU-Readiness to perform Dynamic Braking Function (DBF) or Automatic Vehicle Hold (AVH) which is requested by AVH switch.



LDM_STAT (0H)

 - EPB function : EPB is slave

LDM_STAT (1H)

 - EPB function : EPB stand alone";
BA_ "UserSigValidity" SG_ 2244048387 RCU_AD3_LDM_Sta 3;
BA_ "RoutingFactor" SG_ 2244048387 RCU_AD3_LDM_Sta 5;
BA_ "Version" SG_ 2244048387 RCU_AD3_LDM_Sta "22.01.00";
BA_ "Description" SG_ 2244048387 RCU_AD3_ECD_ActvSta "RCU ECD Active signal indicates whether ECD function is active (operating) or not.";
BA_ "UserSigValidity" SG_ 2244048387 RCU_AD3_ECD_ActvSta 3;
BA_ "RoutingFactor" SG_ 2244048387 RCU_AD3_ECD_ActvSta 5;
BA_ "Version" SG_ 2244048387 RCU_AD3_ECD_ActvSta "22.01.00";
BA_ "Description" SG_ 2244048387 RCU_AD3_MSR_FuncReq "Request for an indicated desired engine torque, the combination of signals calls, on the one hand, for a desire for charge reduction (TCS or ESC function), and, on the other hand, for a desire for charge increase (MSR function).



MSR_C_REQ : Identifies an engine drag torque control for which fuel cut off prohibition is specified.



TCS function:

In the case of a torque reduction, following conditions must be fulfilled. : 

TCS_REQ=1, MSR_C_REQ=0, TQI_TCS < 0FFH and TQI_MSR = 00H



MSR function :

 In the case of a torque increase, following conditions must be fulfilled. : 

 MSR_C_REQ = 1, TCS_REQ = 0, TQI_MSR > 00H and TQI_TCS = 1¡¯s complement of TQI_MSR";
BA_ "UserSigValidity" SG_ 2244048387 RCU_AD3_MSR_FuncReq 3;
BA_ "RoutingFactor" SG_ 2244048387 RCU_AD3_MSR_FuncReq 5;
BA_ "Version" SG_ 2244048387 RCU_AD3_MSR_FuncReq "22.01.00";
BA_ "Description" SG_ 2244048387 RCU_AD3_TCS_Req "Request for an indicated desired engine torque, the combination of signals calls, on the one hand, for a desire for charge reduction (TCS or ESC function), and, on the other hand, for a desire for charge increase (MSR function).



TCS_REQ : Identifies a TCS control or ESC control intervention. This bit is to prevent the triggering of unintended TCS/ESC interventions.



TCS function:

In the case of a torque reduction, following conditions must be fulfilled. : 

TCS_REQ=1, MSR_C_REQ=0, TQI_TCS < 0FFH and TQI_MSR = 00H



MSR function :

 In the case of a torque increase, following conditions must be fulfilled. : 

 MSR_C_REQ = 1, TCS_REQ = 0, TQI_MSR > 00H and TQI_TCS = 1¡¯s complement of TQI_MSR";
BA_ "UserSigValidity" SG_ 2244048387 RCU_AD3_TCS_Req 3;
BA_ "RoutingFactor" SG_ 2244048387 RCU_AD3_TCS_Req 5;
BA_ "Version" SG_ 2244048387 RCU_AD3_TCS_Req "22.01.00";
BA_ "Description" SG_ 2244048387 RCU_AD3_TCS_LmpSta "The signal indicates the status of the ¡°TCS/ESC Function/Warning Lamp¡± (RCU)";
BA_ "UserSigValidity" SG_ 2244048387 RCU_AD3_TCS_LmpSta 3;
BA_ "RoutingFactor" SG_ 2244048387 RCU_AD3_TCS_LmpSta 5;
BA_ "Version" SG_ 2244048387 RCU_AD3_TCS_LmpSta "22.01.00";
BA_ "Description" SG_ 2244048387 RCU_AD3_SCC_TqReq "When it is set, the signal indicates that RCU requests engine torque control for SCC. When the signal is set, EMS should not conduct fuel-cut off control unless it is required to prevent the damage of the engine and the related components.";
BA_ "UserSigValidity" SG_ 2244048387 RCU_AD3_SCC_TqReq 3;
BA_ "RoutingFactor" SG_ 2244048387 RCU_AD3_SCC_TqReq 5;
BA_ "Version" SG_ 2244048387 RCU_AD3_SCC_TqReq "22.01.00";
BA_ "Description" SG_ 2244048387 RCU_AD3_StdStillVal "If an RCU/ESC uses active wheel speed sensors, wheel speeds down to 0 Km/h can be measured. And at 0 Km/h a StandStill flag is set in the RCU/ESC. This signal is used in the offset determination of the yaw rate and shall indicate that the vehicle has come to a complete stop.";
BA_ "UserSigValidity" SG_ 2244048387 RCU_AD3_StdStillVal 3;
BA_ "RoutingFactor" SG_ 2244048387 RCU_AD3_StdStillVal 5;
BA_ "Version" SG_ 2244048387 RCU_AD3_StdStillVal "22.01.00";
BA_ "Description" SG_ 2244048387 RCU_AD3_SCC_ReqLimSta "Due to limitaion of the actuators the acceleration or deceleration request from SCC can not be processed or only partly. 



Examples:

1. SCC is requesting more acceleration than the engine can deliver.

2. SCC is requesting deceleration on a low ¥ì surface.";
BA_ "UserSigValidity" SG_ 2244048387 RCU_AD3_SCC_ReqLimSta 3;
BA_ "RoutingFactor" SG_ 2244048387 RCU_AD3_SCC_ReqLimSta 5;
BA_ "Version" SG_ 2244048387 RCU_AD3_SCC_ReqLimSta "22.01.00";
BA_ "Description" SG_ 2244048387 RCU_AD3_SCC_OptTyp "This value is used for SCC is equipped or not.

Do not recognize 0x3(Not Coded) as failure.";
BA_ "UserSigValidity" SG_ 2244048387 RCU_AD3_SCC_OptTyp 3;
BA_ "RoutingFactor" SG_ 2244048387 RCU_AD3_SCC_OptTyp 5;
BA_ "Version" SG_ 2244048387 RCU_AD3_SCC_OptTyp "22.01.00";
BA_ "Description" SG_ 2244048387 RCU_AD3_SCC_EnblReq "This signal is set by the safety logic in the TCS/ESC. The safety logic shall monitor the following:

1. A temporary failure in the vehicle does not allow SCC (Brakes are overheated, etc¡¦). 

SCC is disabled reversible.

2. SCC communication failure (timeout";
BA_ "UserSigValidity" SG_ 2244048387 RCU_AD3_SCC_EnblReq 3;
BA_ "RoutingFactor" SG_ 2244048387 RCU_AD3_SCC_EnblReq 5;
BA_ "Version" SG_ 2244048387 RCU_AD3_SCC_EnblReq "22.01.00";
BA_ "Description" SG_ 2244048387 RCU_AD3_FCA_EquipSta "FCA Equipment Status

Do not recognize 0x3(Not Coded) as failure.";
BA_ "UserSigValidity" SG_ 2244048387 RCU_AD3_FCA_EquipSta 3;
BA_ "RoutingFactor" SG_ 2244048387 RCU_AD3_FCA_EquipSta 5;
BA_ "Version" SG_ 2244048387 RCU_AD3_FCA_EquipSta "22.01.00";
BA_ "Description" SG_ 2244048387 RCU_AD3_FCA_ActvSta "This signal specifies the status of control for FCA control request flag.";
BA_ "UserSigValidity" SG_ 2244048387 RCU_AD3_FCA_ActvSta 3;
BA_ "RoutingFactor" SG_ 2244048387 RCU_AD3_FCA_ActvSta 5;
BA_ "Version" SG_ 2244048387 RCU_AD3_FCA_ActvSta "22.01.00";
BA_ "Description" SG_ 2244048387 RCU_AD3_DclEnblReq "This signal enables the deceleration control to accept command values axvCv from SCC. This flag is complementary to the ACC_REQ flag if SCC is in active mode.";
BA_ "UserSigValidity" SG_ 2244048387 RCU_AD3_DclEnblReq 3;
BA_ "RoutingFactor" SG_ 2244048387 RCU_AD3_DclEnblReq 5;
BA_ "Version" SG_ 2244048387 RCU_AD3_DclEnblReq "22.01.00";
BA_ "Description" SG_ 2244048387 RCU_AD3_DBS_ActvSta "This signal specifies the status of control for DBS flag.";
BA_ "UserSigValidity" SG_ 2244048387 RCU_AD3_DBS_ActvSta 3;
BA_ "RoutingFactor" SG_ 2244048387 RCU_AD3_DBS_ActvSta 5;
BA_ "Version" SG_ 2244048387 RCU_AD3_DBS_ActvSta "22.01.00";
BA_ "Description" SG_ 2244048387 RCU_AD3_AccelBasisVal "This value is used to initialize the acceleration control when SCC is engaged or after driver override. (RCU)";
BA_ "UserSigValidity" SG_ 2244048387 RCU_AD3_AccelBasisVal 3;
BA_ "RoutingFactor" SG_ 2244048387 RCU_AD3_AccelBasisVal 5;
BA_ "Version" SG_ 2244048387 RCU_AD3_AccelBasisVal "22.01.00";
BA_ "GenMsgSendType" BO_ 2244048388 0;
BA_ "GenMsgCycleTime" BO_ 2244048388 100;
BA_ "GenMsgCycleTimeFast" BO_ 2244048388 0;
BA_ "GenMsgNrOfRepetition" BO_ 2244048388 0;
BA_ "VFrameFormat" BO_ 2244048388 1;
BA_ "Description" SG_ 2244048388 RCU_HDPSpprtSWVer "Software version of IEB/RCU that supports HDP function";
BA_ "UserSigValidity" SG_ 2244048388 RCU_HDPSpprtSWVer 3;
BA_ "RoutingFactor" SG_ 2244048388 RCU_HDPSpprtSWVer 5;
BA_ "Version" SG_ 2244048388 RCU_HDPSpprtSWVer "22.01.00";
BA_ "Description" SG_ 2244048388 RCU_RegenTqLimitNmVal_Rear "Regen Brake Torque limit at rear wheel";
BA_ "UserSigValidity" SG_ 2244048388 RCU_RegenTqLimitNmVal_Rear 3;
BA_ "RoutingFactor" SG_ 2244048388 RCU_RegenTqLimitNmVal_Rear 5;
BA_ "Version" SG_ 2244048388 RCU_RegenTqLimitNmVal_Rear "22.10.19";
BA_ "Description" SG_ 2244048388 RCU_AD3_TCS_TqIntrvntnVal_Frnt "Meaning the required value of the front wheel drive torque for TCS control.

+,- sign  : TCS_TqFlag_Frnt";
BA_ "UserSigValidity" SG_ 2244048388 RCU_AD3_TCS_TqIntrvntnVal_Frnt 3;
BA_ "RoutingFactor" SG_ 2244048388 RCU_AD3_TCS_TqIntrvntnVal_Frnt 5;
BA_ "Version" SG_ 2244048388 RCU_AD3_TCS_TqIntrvntnVal_Frnt "22.10.19";
BA_ "Description" SG_ 2244048388 RCU_AD3_TCS_MtrTrgtRpm_Frnt "Meaning the RPM required value of the front Motor drive for TCS control.

+,- sign  : TCS_MtrTrgtRpm_Flag_Frnt";
BA_ "UserSigValidity" SG_ 2244048388 RCU_AD3_TCS_MtrTrgtRpm_Frnt 3;
BA_ "RoutingFactor" SG_ 2244048388 RCU_AD3_TCS_MtrTrgtRpm_Frnt 5;
BA_ "Version" SG_ 2244048388 RCU_AD3_TCS_MtrTrgtRpm_Frnt "22.10.19";
BA_ "Description" SG_ 2244048388 RCU_AD3_TCS_TqFlag_Frnt "This signal means +,- sign for the TCS front wheel torque signal of the RCU_03_20ms message.";
BA_ "UserSigValidity" SG_ 2244048388 RCU_AD3_TCS_TqFlag_Frnt 3;
BA_ "RoutingFactor" SG_ 2244048388 RCU_AD3_TCS_TqFlag_Frnt 5;
BA_ "Version" SG_ 2244048388 RCU_AD3_TCS_TqFlag_Frnt "22.10.19";
BA_ "Description" SG_ 2244048388 RCU_AD3_TCS_MtrTrgtRpm_Rear "Meaning the RPM required value of the rear Motor drive for TCS control.

+,- sign  : TCS_MtrTrgtRpm_Flag_Rear";
BA_ "UserSigValidity" SG_ 2244048388 RCU_AD3_TCS_MtrTrgtRpm_Rear 3;
BA_ "RoutingFactor" SG_ 2244048388 RCU_AD3_TCS_MtrTrgtRpm_Rear 5;
BA_ "Version" SG_ 2244048388 RCU_AD3_TCS_MtrTrgtRpm_Rear "22.10.19";
BA_ "Description" SG_ 2244048388 RCU_AD3_ABS_WrngLmpSta "The signal indicates the status of the RCU ¡°ABS Warning lamp¡±";
BA_ "UserSigValidity" SG_ 2244048388 RCU_AD3_ABS_WrngLmpSta 3;
BA_ "RoutingFactor" SG_ 2244048388 RCU_AD3_ABS_WrngLmpSta 5;
BA_ "Version" SG_ 2244048388 RCU_AD3_ABS_WrngLmpSta "22.04.01";
BA_ "Description" SG_ 2244048388 RCU_AD3_ESC_Sta "Information regarding the status of RCU ESC function.



If the function has not been coded(fixed) yet, this signal will be transmitted as 0xE.



If the vehicle has been applied only ABS(without ESC), this signal will be fixed as 0x0.";
BA_ "UserSigValidity" SG_ 2244048388 RCU_AD3_ESC_Sta 3;
BA_ "RoutingFactor" SG_ 2244048388 RCU_AD3_ESC_Sta 5;
BA_ "Version" SG_ 2244048388 RCU_AD3_ESC_Sta "22.04.01";
VAL_ 2273435649 ADAS_CMD_Crc31Val 0 "0x0x0~0xFFFF:CRCValue" 65535 "0x0x0~0xFFFF:CRCValue" ;
VAL_ 2273435649 ADAS_CMD_AlvCnt31Val 0 "0x0x0~0xFF:AlvCntValue" 255 "0x0x0~0xFF:AlvCntValue" ;
VAL_ 2273435649 HDA_OptUsmSta 0 "Not Applied" 1 "Function Off" 2 "Function On" 3 "Reserved" 4 "Reserved" 5 "Reserved" 6 "Reserved" 7 "Invalid (Fail)" ;
VAL_ 2273435649 HDA_CntrlModSta 0 "System OFF (Default)" 1 "System STANDBY" 2 "System ACTIVE" 3 "Reserved" ;
VAL_ 2273435649 HDA_InfoPUDis 0 "No pop-up" 1 "system start pop-up" 2 "system auto disengaged pop-up by highway off" 3 "System Fail pop up (LFA)" 4 "System Fail pop up (HDA)" 5 "Hands-off pop up" 6 "Hands-off pop up w/sound" 7 "RESERVED" ;
VAL_ 2273435649 HDP_AutoCallReqSta 0 "No request" 1 "HDP MRM Auto Call Request" 2 "Reserved" 3 "Reserved" 4 "Reserved" 5 "Reserved" 6 "Cancel the HDP Auto Call" 7 "Invalid" ;
VAL_ 2273435649 HDP_DispBarSta 0 "Not Display" 1 "Amber Blinking" 2 "RESERVED" 3 "Amber Display" 4 "Red Display" 5 "RESERVED" 6 "RESERVED" 7 "RESERVED" 8 "RESERVED" 9 "RESERVED" 10 "RESERVED" 11 "RESERVED" 12 "RESERVED" 13 "RESERVED" 14 "RESERVED" 15 "RESERVED" ;
VAL_ 2273435649 HDP_OptInfoSta 0 "HDP option not applied" 1 "HDP option applied" 2 "HC option applied" 3 "RESERVED" 4 "RESERVED" 5 "RESERVED" 6 "RESERVED" 7 "RESERVED" ;
VAL_ 2273435649 HDA_LFA_SymSta 0 "Off" 1 "Gray" 2 "Green" 3 "White blink" ;
VAL_ 2273435649 HDA_LFA_WrnSnd 0 "Off" 1 "Additional Warning Sound" 2 "Reserved" 3 "Error indicator" ;
VAL_ 2273435649 HDA_InfoPUDis1 0 "No Pop-up" 1 "System Automatic off (LFA)" 2 "System Automatic off (HDA)" 3 "Reserved" 4 "Reserved" 5 "Reserved" 6 "Not Used" 7 "Error Indicator" ;
VAL_ 2273435649 HDA_TDMRMDclReq 0 "Not automatically deactivated state of LFA (default)" 1 "Automatically deactivated state of LFA" 2 "Reserved" 3 "Reserved" ;
VAL_ 2273435649 HDP_ActvSta 0 "Not Active" 1 "Active" 2 "Reserved" 3 "Reserved" ;
VAL_ 2273435649 HDP_SysSta 0 "OFF" 1 "Standby" 2 "DDT" 3 "TD" 4 "MRM" 5 "EM" 6 "Reserved" 15 "Reserved" ;
VAL_ 2273435649 HDP_FailureMode 0 "Normal" 1 "Blockage" 2 "Failure" ;
VAL_ 2273435650 HDP_ObstacleDstVal 0 "0x0x0~0x5DC:Distance" 1500 "0x0x0~0x5DC:Distance" 1501 "0x5DD~0x7FD:Reserved" 2045 "0x5DD~0x7FD:Reserved" 2046 "Default" 2047 "Error" ;
VAL_ 2273435650 HDP_ObstacleLatPosVal 0 "0x0x0~0x1FD:Position Value" 509 "0x0x0~0x1FD:Position Value" 510 "Default" 511 "Error" ;
VAL_ 2273435650 HDP_InfoPUDis 0 "None" 1 "HDP Active" 2 "HDP TD Lv1" 3 "HDP TD Lv2" 4 "HDP MRM" 5 "HDP EM in TD or MRM" 6 "HDP Automatic system off" 7 "HDP Driver availability warning" 8 "Unable to start HDP" 9 "HDP guides user to change lane" 10 "HDP off by the driver" 11 "HDP EM in DDT" 12 "Set Wiper and Light to AUTO" 13 "Driver Unavailable" 14 "HDP to HDA" 15 "HDP LC start" ;
VAL_ 2273435650 HDP_WrngTypPUDis 0 "Reserved" 1 "Reserved" 2 "Reserved" 3 "Reserved" 4 "Reserved" 5 "Reserved" 6 "Reserved" 7 "Reserved" 8 "Reserved" 9 "Reserved" 10 "Reserved" 11 "Reserved" 12 "Reserved" 13 "Reserved" 14 "Reserved" 15 "Reserved" 16 "Reserved" 17 "Reserved" 18 "Reserved" 19 "Reserved" 20 "Reserved" 21 "Reserved" 22 "Reserved" 23 "Reserved" 24 "Reserved" 25 "Reserved" 26 "Reserved" 27 "Reserved" 28 "Reserved" 29 "Reserved" 30 "Reserved" 31 "Reserved" ;
VAL_ 2273435650 HDP_HapticWarnReq 0 "No Warn" 1 "Request Haptic Warn - Level1" 2 "Request Haptic Warn - Level2" 3 "Invalid" ;
VAL_ 2273435650 HDP_ActvStaDis 0 "Not Active" 1 "Active" 2 "RESERVED" 3 "RESERVED" 4 "RESERVED" 5 "RESERVED" 6 "RESERVED" 7 "Invalid" ;
VAL_ 2273435650 HDP_OpStaDisp 0 "None" 1 "Standby" 2 "Ready" 3 "Active(DDT)" 4 "Active(TD)" 5 "Active(MRM)" 6 "Active(EM)" 7 "RESERVED" 8 "RESERVED" 9 "RESERVED" 10 "RESERVED" 11 "RESERVED" 12 "RESERVED" 13 "RESERVED" 14 "RESERVED" 15 "Invalid" ;
VAL_ 2273435650 HDP_ObstSta 0 "No in-path obstacle detected" 1 "In-path obstacle detected (uncontrollable)" 2 "In-path obstacle detected (controllable:longitudinal)" 3 "Reserved" 4 "Reserved" 5 "Reserved" 6 "Reserved" 7 "Reserved" ;
VAL_ 2273435650 HDP_SysFlrDisp 0 "No HDP failure pop-up" 1 "HDP failure pop-up" 2 "HDP Camera blockage" 3 "HDP Radar blockage" 4 "HDP Lidar blockage" 5 "RESERVED" 6 "RESERVED" 7 "RESERVED" ;
VAL_ 2273435650 HDP_InhbtOffDispSta 0 "None" 1 "Inhibit change while HDP (H/Unit)" 2 "RESERVED" 3 "RESERVED" 4 "RESERVED" 5 "RESERVED" 6 "RESERVED" 7 "RESERVED" ;
VAL_ 2273435650 HDP_CtRoadSrfcDistVal 0 "0x0x0~0x5DC:Real Values" 1500 "0x0x0~0x5DC:Real Values" 1501 "0x5DD~0x7FD:RESERVED" 2045 "0x5DD~0x7FD:RESERVED" 2046 "Default (Not Display)" 2047 "Invalid" ;
VAL_ 2273435650 ADAS_DRV_UpDateInfo 0 "old" 1 "new" ;
VAL_ 527 ATS_DrvStRseFwdBtn 0 "Default" 1 "Off" 2 "On" 3 "Reserved" ;
VAL_ 527 ATS_DrvStRseBwdBtn 0 "Default" 1 "Off" 2 "On" 3 "Reserved" ;
VAL_ 527 ATS_RRRestModBtn 0 "Default" 1 "Off" 2 "On" 3 "Reserved" ;
VAL_ 527 ATS_RRResetModBtn 0 "Default" 1 "Off" 2 "On" 3 "Reserved" ;
VAL_ 527 ATS_RRAvWtcModBtn 0 "Default" 1 "Off" 2 "On" 3 "Reserved" ;
VAL_ 527 ATS_RRReadingModBtn 0 "Default" 1 "Off" 2 "On" 3 "Reserved" ;
VAL_ 527 ATS_RLRestModBtn 0 "Default" 1 "Off" 2 "On" 3 "Reserved" ;
VAL_ 527 ATS_RLResetModBtn 0 "Default" 1 "Off" 2 "On" 3 "Reserved" ;
VAL_ 543 ATS_AstStSldFwdBtn 0 "Default" 1 "Off" 2 "On" 3 "Reserved" ;
VAL_ 543 ATS_AstStSldBwdBtn 0 "Default" 1 "Off" 2 "On" 3 "Reserved" ;
VAL_ 543 ATS_AstStRclFwdBtn 0 "Default" 1 "Off" 2 "On" 3 "Reserved" ;
VAL_ 543 ATS_AstStRclBwdBtn 0 "Default" 1 "Off" 2 "On" 3 "Reserved" ;
VAL_ 543 ATS_AstStHgtUpBtn 0 "Default" 1 "Off" 2 "On" 3 "Reserved" ;
VAL_ 543 ATS_AstStHgtDnBtn 0 "Default" 1 "Off" 2 "On" 3 "Reserved" ;
VAL_ 543 ATS_AstStHRestUpBtn 0 "Default" 1 "Off" 2 "On" 3 "Reserved" ;
VAL_ 543 ATS_AstStHRestDnBtn 0 "Default" 1 "Off" 2 "On" 3 "Reserved" ;
VAL_ 543 ATS_AstStHRestFwdBtn 0 "Default" 1 "Off" 2 "On" 3 "Reserved" ;
VAL_ 543 ATS_AstStHRestBwdBtn 0 "Default" 1 "Off" 2 "On" 3 "Reserved" ;
VAL_ 543 ATS_AstStHRestFldBtn 0 "Default" 1 "Off" 2 "On" 3 "Reserved" ;
VAL_ 543 ATS_AstStHRestUnFldBtn 0 "Default" 1 "Off" 2 "On" 3 "Reserved" ;
VAL_ 543 ATS_AstStRseFwdBtn 0 "Default" 1 "Off" 2 "On" 3 "Reserved" ;
VAL_ 543 ATS_AstStRseBwdBtn 0 "Default" 1 "Off" 2 "On" 3 "Reserved" ;
VAL_ 543 ATS_AstStFRestFldBtn 0 "Default" 1 "Off" 2 "On" 3 "Reserved" ;
VAL_ 543 ATS_AstStFRestUnFldBtn 0 "Default" 1 "Off" 2 "On" 3 "Reserved" ;
VAL_ 543 ATS_AstTltUpBtn 0 "Default" 1 "Off" 2 "On" 3 "Reserved" ;
VAL_ 543 ATS_AstTltDnBtn 0 "Default" 1 "Off" 2 "On" 3 "Reserved" ;
VAL_ 623 ATS_ARSOpenCloseStatus 0 "Default" 1 "Open" 2 "Close" 3 "Invalid" ;
VAL_ 623 ATS_RLLumbarDefBtn 0 "Default" 1 "Off" 2 "On" 3 "Reserved" ;
VAL_ 623 ATS_RLLumbarLowBtn 0 "Default" 1 "Off" 2 "On" 3 "Reserved" ;
VAL_ 623 ATS_RLLumbarMidBtn 0 "Default" 1 "Off" 2 "On" 3 "Reserved" ;
VAL_ 623 ATS_RLLumbarUpBtn 0 "Default" 1 "Off" 2 "On" 3 "Reserved" ;
VAL_ 623 ATS_RLBolsterDefBtn 0 "Default" 1 "Off" 2 "On" 3 "Reserved" ;
VAL_ 623 ATS_RLBolsterInfSw 0 "Default" 1 "Off" 2 "On" 3 "Reserved" ;
VAL_ 623 ATS_RRLumbarDefBtn 0 "Default" 1 "Off" 2 "On" 3 "Reserved" ;
VAL_ 623 ATS_RRLumbarLowBtn 0 "Default" 1 "Off" 2 "On" 3 "Reserved" ;
VAL_ 623 ATS_RRLumbarMidBtn 0 "Default" 1 "Off" 2 "On" 3 "Reserved" ;
VAL_ 623 ATS_RRLumbarUpBtn 0 "Default" 1 "Off" 2 "On" 3 "Reserved" ;
VAL_ 623 ATS_RRBolsterDefBtn 0 "Default" 1 "Off" 2 "On" 3 "Reserved" ;
VAL_ 623 ATS_RRBolsterInfSw 0 "Default" 1 "Off" 2 "On" 3 "Reserved" ;
VAL_ 2395189505 DATC_Crc9Val 0 "0x0x0~0xFFFF:CRCValue" 65535 "0x0x0~0xFFFF:CRCValue" ;
VAL_ 2395189505 DATC_AlvCnt9Val 0 "0x0x0~0xFF:AlvCntValue" 255 "0x0x0~0xFF:AlvCntValue" ;
VAL_ 2395189505 DATC_FragranceStrhSta 0 "Default" 1 "Off" 2 "Low" 3 "Medium" 4 "High" 5 "Reserved" 6 "Reserved" 7 "Error Indicator" ;
VAL_ 2395189505 DATC_FragranceKindSta 0 "Default" 1 "First" 2 "Second" 3 "Reserved" 4 "Reserved" 5 "Reserved" 6 "Reserved" 7 "Error Indicator" ;
VAL_ 2395189505 DATC_AfterBlowOpSta 0 "Default" 1 "Not Operation Status" 2 "Operation Status" 3 "Error Indicator" ;
VAL_ 2395189505 DATC_RrBlwDis 0 "OFF(Default)" 1 "Blank Display(Blower ´Ü¼ö ¹ÌÇ¥½Ã, ¿¹)Auto ½Ã)" 2 "1 Step" 3 "2 Step" 4 "3 Step" 5 "4 Step" 6 "5 Step" 7 "6 Step" 8 "7 Step" 9 "8 Step" 10 "BLOWER AUTO" 11 "Reserved" 12 "Reserved" 13 "Reserved" 14 "Reserved" 15 "Error Indicator" ;
VAL_ 2395189505 DATC_RrClmtAutoOffUSMSta 0 "Default" 1 "Off" 2 "On" 3 "Error Indicator" ;
VAL_ 2395189505 DATC_KeyOffBlowOpReq 0 "Off (Default)" 1 "On Request" 2 "RESERVED" 3 "Error Indicator" ;
VAL_ 2395189505 DATC_ArClnSysOSD 0 "Default (Initial Value)" 1 "AirCleaning SYS ON" 2 "AirCleaning SYS OFF" 3 "High Dust AirCleaning ON" 4 "High Dust AirCleaning OFF" 5 "Sensor AirCleaning SYS ON & Closing Window" 6 "Opening Warning" 7 "Reserved" 8 "Reserved" 9 "Reserved" 10 "Reserved" 11 "Reserved" 12 "Reserved" 13 "Reserved" 14 "Reserved" 15 "Invalid" ;
VAL_ 2395189505 DATC_ArClnStepClr 0 "Default (Initial Value)" 1 "Mono Color" 2 "Blue Color" 3 "Green Color" 4 "Orange Color" 5 "Red Color" 6 "Yellow Color" 7 "Reserved" 8 "Reserved" 9 "Reserved" 10 "Reserved" 11 "Reserved" 12 "Reserved" 13 "Reserved" 14 "Gray Color (Deactivate)" 15 "Invalid" ;
VAL_ 2395189505 DATC_ArClnSmblTyp 0 "Default" 1 "Blank (Initial Display)" 2 "Wood" 3 "Wood & Fixed Arrow" 4 "Wood & Rotating Arrow" 5 "White Wood & Fixed Arrow" 6 "White Wood & Rotating Arrow" 7 "Invaild" ;
VAL_ 2395189505 DATC_AfterBlowUSMSta 0 "Default" 1 "After Blow USM OFF" 2 "After Blow USM ON" 3 "Error Indicator" ;
VAL_ 2395189505 DATC_SchdldVntUSMSta 0 "Default" 1 "OFF" 2 "ON" 3 "Error Indicator" ;
VAL_ 2395189505 DATC_SchdldVntHrSta 0 "Default" 1 "0hr" 2 "1hr" 3 "2hr" 4 "3hr" 5 "4hr" 6 "5hr" 7 "6hr" 8 "7hr" 9 "8hr" 10 "9hr" 11 "10hr" 12 "11hr" 13 "12hr" 14 "13hr" 15 "14hr" 16 "15hr" 17 "16hr" 18 "17hr" 19 "18hr" 20 "19hr" 21 "20hr" 22 "21hr" 23 "22hr" 24 "23hr" 25 "Reserved" 26 "Reserved" 27 "Reserved" 28 "Reserved" 29 "Reserved" 30 "Reserved" 31 "Error Indicator" ;
VAL_ 2395189505 DATC_SchdldVntMinSta 0 "Default" 1 "0 Min" 2 "10 Min" 3 "20 Min" 4 "30 Min" 5 "40 Min" 6 "50 Min" 7 "Error Indicator" ;
VAL_ 614 EMCU_Crc1Val 0 "0x0x0~0xFF:CRCValue" 255 "0x0x0~0xFF:CRCValue" ;
VAL_ 614 EMCU_AlvCnt1Val 0 "AlvCntValue" 1 "AlvCntValue" 2 "AlvCntValue" 3 "AlvCntValue" 4 "AlvCntValue" 5 "AlvCntValue" 6 "AlvCntValue" 7 "AlvCntValue" 8 "AlvCntValue" 9 "AlvCntValue" 10 "AlvCntValue" 11 "AlvCntValue" 12 "AlvCntValue" 13 "AlvCntValue" 14 "AlvCntValue" 15 "AlvCntValue" ;
VAL_ 614 EMCU_LHActSta 0 "OFF" 1 "ON" 2 "RESERVED" 3 "Error indicator" ;
VAL_ 614 EMCU_RHActSta 0 "OFF" 1 "ON" 2 "RESERVED" 3 "Error indicator" ;
VAL_ 614 EMCU_DeltaSpdVal 0 "0x0x000~0xFFE:real values" 4094 "0x0x000~0xFFE:real values" 4095 "Error indicator" ;
VAL_ 614 EMCU_System_Sta 0 "Normal" 1 "RESERVED" 2 "RESERVED" 3 "Error indicator" ;
VAL_ 2214658049 EMS_Crc2Val 0 "0x0x0~0xFFFF:CRCValue" 65535 "0x0x0~0xFFFF:CRCValue" ;
VAL_ 2214658049 EMS_AlvCnt2Val 0 "0x0x0~0xFF:AlvCntValue" 255 "0x0x0~0xFF:AlvCntValue" ;
VAL_ 2214658049 ENG_BrkSwSta 0 "Brake switch is not pressed (OFF)" 1 "Brake switch is pressed (ON)" 2 "EMS does not support this function." 3 "Brake switch failure" ;
VAL_ 2214658049 ENG_EngClntTempVal 255 "Error indicator" ;
VAL_ 2214658049 ENG_MafCrctVal 128 "Error indicator" ;
VAL_ 2214658049 ENG_BattDscnctSta 0 "no battery disconnection detected" 1 "battery disconnection detected and failure memory erased" 2 "Not used" 3 "Error indicator" ;
VAL_ 2214658049 OBD_MilConfgVal 0 "no MIL, Failure Memory Management OBD-I" 1 "MIL Treatment OBD-I, Failure Memory Management OBD-I" 2 "MIL Treatment OBD-II, Exception" 3 "MIL Treatment OBD-II, Failure Memory Management OBD-II" 4 "MIL Treatment E-OBD, Failure Memory Management E-OBD" 5 "MIL Treatment K-OBD, Failure Memory Management K-OBD" ;
VAL_ 2214658049 ENG_EngSta 0 "Engine Stop" 1 "Cranking" 2 "Stalled" 3 "Running" 4 "Reserved" 5 "Reserved" 6 "Reserved" 7 "Fault" ;
VAL_ 2214658050 ENG_Ack4EngStpSta 0 "No acknowledgement" 1 "Acknowledgement engine stopped" 2 "Not used" 3 "Error indicator" ;
VAL_ 2214658050 ENG_AccDrvAlertDisp 0 "Default" 1 "Auto cruise Disengaged" 2 "No Auto cruise Engaged" 3 "Error indicator" ;
VAL_ 2214658050 DSL_GlowCtrlReq 0 "Glow plug off request" 1 "Glow plug on request" 2 "System Error" 3 "Reserved" ;
VAL_ 2214658050 ENG_GlowLmpSta 0 "Lamp Off" 1 "Lamp On" 2 "Not used" 3 "Error indicator" ;
VAL_ 2214658050 ENG_ThrPosVal 32 "Idle (port value is learnt)" 245 "Throttle perpendicular" 255 "Throttle defective" ;
VAL_ 2214658050 ENG_OverDrvOffReq 0 "Normal operation" 1 "Over drive off request to TCU by the cruise control function" 2 "Not used" 3 "Error indicator" ;
VAL_ 2214658050 ENG_AccelPdlVal 0 "Accelerator Pedal not activated" 1022 "Accelerator Pedal fully activated" 1023 "Accelerator Pedal is defective (fail state) or Non-ETC system (APS is not installed), Error indicator" ;
VAL_ 2214658050 ENG_AccActSta 0 "Auto cruise control is not active" 1 "Auto cruise control is active" 2 "Not used" 3 "Error indicator" ;
VAL_ 2214658050 ACC_CrsMainSwLmpSta 0 "Cruise MAIN switch indication lamp turn OFF" 1 "Cruise MAIN switch indication lamp turn ON" 2 "Not used" 3 "Error indicator" ;
VAL_ 2214658050 ACC_CrsSetSwLmpSta 0 "Cruise SET switch indication lamp turn OFF" 1 "Cruise SET switch indication lamp turn ON" 2 "Not used" 3 "Error indicator" ;
VAL_ 2214658050 ENG_LV_FUP_ENA_THD 0 "The pressure is too low to start engine" 1 "The pressure is enough high to start engine" ;
VAL_ 2214658050 ENG_SoakTimeErrSta 0 "No Failure detected" 1 "Failure detected" 2 "Not used" 3 "Error indicator" ;
VAL_ 2214658050 ENG_CltchOpSta 0 "Clutch is not operating" 1 "Clutch is operating" 2 "Not used" 3 "Error indicator" ;
VAL_ 2214658050 EMS_BrkReq_Slope 0 "No Request" 1 "Brake Request" ;
VAL_ 2214658051 ENG_AppAccelPdlSta 0 "Accelerator pedal not pressed" 1 "Accelerator pedal pressed" 2 "Reserved" 3 "Accelerator pedal position sensor failure" ;
VAL_ 2214658051 ENG_BrkCtrlReq 0 "Brake control request is not active" 1 "Brake control request is active" 2 "Not used" 3 "Error indicator" ;
VAL_ 2214658051 ACC_DnShftCtrlReq 0 "Downshift control request is not active" 1 "Downshift request to 1st gear" 2 "Downshift request to 2nd gear" 3 "Downshift request to 3rd gear" 4 "Downshift request to 4th gear" 5 "Downshift request to 5th gear" 6 "Downshift request to 6th gear" 7 "Downshift request to 7th gear" 8 "Downshift request to 8th gear" 9 "Reserved" 10 "Reserved" 11 "Reserved" 12 "Reserved" 13 "Reserved" 14 "Reserved" 15 "Error indicator" ;
VAL_ 2214658052 ENG_DclBrkCntrlReq 4095 "Error indicator" ;
VAL_ 2214658052 ENG_BstPrsrVal 4095 "Error indicator" ;
VAL_ 2214658052 ENG_EngOilTempVal 255 "Error indicator" ;
VAL_ 2214658052 ENG_DpfWrngSta 0 "DPF Normal State" 1 "DPF Warning State Level 1" 2 "DPF Warning State Level 2" 3 "Reserved" ;
VAL_ 2214658052 ENG_BattWrngLmpSta 0 "Battery Warning Lamp OFF" 1 "Battery Warning Lamp ON" 2 "Not used" 3 "Error indicator" ;
VAL_ 2214658052 ENG_OilPrsrWrngLmpSta 0 "Oil Pressure Warning Lamp OFF" 1 "Oil Pressure Warning Lamp ON" 2 "Not used" 3 "Error indicator" ;
VAL_ 2214658052 ENG_IsgInhbtLmpSta 0 "ISG Inhibit Lamp OFF" 1 "ISG Inhibit Lamp ON" 2 "Not used" 3 "Error indicator" ;
VAL_ 1616 MKBD_IllumiState 0 "Not received" 1 "Receive Completed" 2 "Reserved" 3 "Invalid" ;
VAL_ 1616 MKBD_SeatKeySet 0 "Off" 1 "On" 2 "Reserved" 3 "Invalid" ;
VAL_ 2449771009 ODS_OccClassSta 1 "Class1" 2 "Class2" 4 "Indeterminate" ;
VAL_ 2449771009 ODS_SBRClassSta 0 "Empty / Indeterminate" 1 "Occupied" ;
VAL_ 553 PSS_RL_LumbarUpSw 0 "Default" 1 "Off" 2 "On" 3 "Invalid" ;
VAL_ 553 PSS_RL_BolsterDefSw 0 "Default" 1 "Off" 2 "On" 3 "Invalid" ;
VAL_ 553 PSS_RL_ActiveSw 0 "Default" 1 "Off" 2 "On" 3 "Invalid" ;
VAL_ 553 PSS_RL_LumbarMidSw 0 "Default" 1 "Off" 2 "On" 3 "Invalid" ;
VAL_ 553 PSS_RL_LumbarLowSw 0 "Default" 1 "Off" 2 "On" 3 "Invalid" ;
VAL_ 553 PSS_RL_LumbarDefSw 0 "Default" 1 "Off" 2 "On" 3 "Invalid" ;
VAL_ 553 PSS_RL_BolsterInfSw 0 "Default" 1 "Off" 2 "On" 3 "Invalid" ;
VAL_ 630 PSS_RR_StSldFwdMvBtn 0 "Default" 1 "Off" 2 "On" 3 "Invalid" ;
VAL_ 630 PSS_RR_StTltDnMvBtn 0 "Default" 1 "Off" 2 "On" 3 "Invalid" ;
VAL_ 630 PSS_RR_StHRestUpMvBtn 0 "Default" 1 "Off" 2 "On" 3 "Invalid" ;
VAL_ 630 PSS_RR_StHRestDnMvBtn 0 "Default" 1 "Off" 2 "On" 3 "Invalid" ;
VAL_ 630 PSS_RR_StHRestFwdMvBtn 0 "Default" 1 "Off" 2 "On" 3 "Invalid" ;
VAL_ 630 PSS_RR_StHRestBwdMvBtn 0 "Default" 1 "Off" 2 "On" 3 "Invalid" ;
VAL_ 630 PSS_RR_StSldBwdMvBtn 0 "Default" 1 "Off" 2 "On" 3 "Invalid" ;
VAL_ 630 PSS_RR_StLegRestUpBtn 0 "Default" 1 "Off" 2 "On" 3 "Invalid" ;
VAL_ 630 PSS_RR_StLegRestDnBtn 0 "Default" 1 "Off" 2 "On" 3 "Invalid" ;
VAL_ 630 PSS_RR_StLegRestExtFwdBtn 0 "Default" 1 "Off" 2 "On" 3 "Invalid" ;
VAL_ 630 PSS_RR_StLegRestExtBwdBtn 0 "Default" 1 "Off" 2 "On" 3 "Invalid" ;
VAL_ 630 PSS_RR_StRlxModeBtn 0 "Default" 1 "Off" 2 "On" 3 "Invalid" ;
VAL_ 630 PSS_RR_StRlxReturnBtn 0 "Default" 1 "Off" 2 "On" 3 "Invalid" ;
VAL_ 630 PSS_RR_StRlxTltUpMvBtn 0 "Default" 1 "Off" 2 "On" 3 "Invalid" ;
VAL_ 630 PSS_RR_StRlxTltDnMvBtn 0 "Default" 1 "Off" 2 "On" 3 "Invalid" ;
VAL_ 630 PSS_RR_StMnlRlxModeBtn 0 "Default" 1 "Off" 2 "On" 3 "Invalid" ;
VAL_ 630 PSS_RR_StMnlRlxReturnBtn 0 "Default" 1 "Off" 2 "On" 3 "Invalid" ;
VAL_ 630 PSS_RR_StRclFwdMvBtn 0 "Default" 1 "Off" 2 "On" 3 "Invalid" ;
VAL_ 630 PSS_RR_WalkInSwitchSts 0 "Default" 1 "Off" 2 "On" 3 "Invalid" ;
VAL_ 630 PSS_RR_StRclBwdMvBtn 0 "Default" 1 "Off" 2 "On" 3 "Invalid" ;
VAL_ 630 PSS_RR_StTltUpMvBtn 0 "Default" 1 "Off" 2 "On" 3 "Invalid" ;
VAL_ 631 PSS_RR_StOneTchWlkinCushBtn 0 "Default" 1 "Off" 2 "On" 3 "Invalid" ;
VAL_ 631 PSS_RR_StOneTchWlkinBackBtn 0 "Default" 1 "Off" 2 "On" 3 "Invalid" ;
VAL_ 631 PSS_RR_MomoryP1Cmd 0 "Default" 1 "Off" 2 "On" 3 "Invalid" ;
VAL_ 631 PSS_RR_MomoryP2Cmd 0 "Default" 1 "Off" 2 "On" 3 "Invalid" ;
VAL_ 632 PSS_RR_AstHRestFwdMvBtn 0 "Default" 1 "Off" 2 "On" 3 "Invalid" ;
VAL_ 632 PSS_RR_AstRclBwdMvBtn 0 "Default" 1 "Off" 2 "On" 3 "Invalid" ;
VAL_ 632 PSS_RR_AstSldFwdMvBtn 0 "Default" 1 "Off" 2 "On" 3 "Invalid" ;
VAL_ 632 PSS_RR_AstSldBwdMvBtn 0 "Default" 1 "Off" 2 "On" 3 "Invalid" ;
VAL_ 632 PSS_RR_AstHgtUpMvBtn 0 "Default" 1 "Off" 2 "On" 3 "Invalid" ;
VAL_ 632 PSS_RR_AstHgtDnMvBtn 0 "Default" 1 "Off" 2 "On" 3 "Invalid" ;
VAL_ 632 PSS_RR_AstHRestBwdMvBtn 0 "Default" 1 "Off" 2 "On" 3 "Invalid" ;
VAL_ 632 PSS_RR_AstFRestOpenMvBtn 0 "Default" 1 "Off" 2 "On" 3 "Invalid" ;
VAL_ 632 PSS_RR_AstFRestCloseMvBtn 0 "Default" 1 "Off" 2 "On" 3 "Invalid" ;
VAL_ 632 PSS_RR_AstHRestUpMvBtn 0 "Default" 1 "Off" 2 "On" 3 "Invalid" ;
VAL_ 632 PSS_RR_AstHRestDnMvBtn 0 "Default" 1 "Off" 2 "On" 3 "Invalid" ;
VAL_ 632 PSS_RR_AstRclFwdMvBtn 0 "Default" 1 "Off" 2 "On" 3 "Invalid" ;
VAL_ 633 PSS_RR_LumbarUpSw 0 "Default" 1 "Off" 2 "On" 3 "Invalid" ;
VAL_ 633 PSS_RR_BolsterDefSw 0 "Default" 1 "Off" 2 "On" 3 "Invalid" ;
VAL_ 633 PSS_RR_ActiveSw 0 "Default" 1 "Off" 2 "On" 3 "Invalid" ;
VAL_ 633 PSS_RR_LumbarMidSw 0 "Default" 1 "Off" 2 "On" 3 "Invalid" ;
VAL_ 633 PSS_RR_LumbarLowSw 0 "Default" 1 "Off" 2 "On" 3 "Invalid" ;
VAL_ 633 PSS_RR_LumbarDefSw 0 "Default" 1 "Off" 2 "On" 3 "Invalid" ;
VAL_ 633 PSS_RR_BolsterInfSw 0 "Default" 1 "Off" 2 "On" 3 "Invalid" ;
VAL_ 2244048385 RCU_Crc3Val 0 "0x0x0~0xFFFF:CRCValue" 65535 "0x0x0~0xFFFF:CRCValue" ;
VAL_ 2244048385 RCU_AlvCnt3Val 0 "0x0x0~0xFF:AlvCntValue" 255 "0x0x0~0xFF:AlvCntValue" ;
VAL_ 2244048385 RCU_HDP_FltMonSta 0 "No Fault" 1 "Main Controller Fault Detected (ADAS_DRV 2)" 2 "Sub Controller Fault Detected (FR_CMR)" 3 "Main & Sub Controller Fault Detected (ADAS_DRV 2 & FR_CMR)" 4 "Reserved" 5 "Reserved" 6 "Reserved" 7 "Reserved" ;
VAL_ 2244048385 RCU_HDP_EgSta 0 "Not Engaged" 1 "Engaged in main controller by IEB (ESC)" 2 "Engaged in sub controller by IEB (ESC)" 3 "MRM with IEB (ESC) alone" 4 "Engaged in main controller by RCU" 5 "Engaged in sub controller by RCU" 6 "MRM with RCU alone" 7 "Engaged in sub controller by IEB (ESC), but RCU Signal" ;
VAL_ 2244048385 RCU_Sta 0 "Not Ready" 1 "Ready" 2 "Ready (Front only) & Not Ready(Rear)" 3 "Ready (Rear only) & Not Ready(Front)" ;
VAL_ 2244048385 RCU_HDP_EnblReq 0 "No Fault" 1 "Req. longitudinal control normal, Functional Fault" 2 "Req. longitudinal control normal, Partial performance degradation" 3 "Req. longitudinal control abnormal, Brake control possible" 4 "Req. longitudinal control abnormal, Brake control impossible" 5 "Req. longitudinal control normal, Acceleration control Fault (eg. Engine Fault)" 6 "HDP disabled reversible" 7 "Reserved" ;
VAL_ 2244048385 RCU_AD3_AWD_FastOpnCrdnShftCltchReq 0 "Passive" 1 "Clutch off" 2 "Torque limit" 3 "Error" ;
VAL_ 2244048385 RCU_AD3_PdlTrvlSnsrValVldSta 0 "Normal" 1 "Fail" 2 "Compare error" 3 "Suspect" ;
VAL_ 2244048385 RCU_AD3_PdlCalibSta 0 "Not complete" 1 "Complete" 2 "Not used" 3 "Not used" ;
VAL_ 2244048385 RCU_AD3_TCS_MtrTrgtRpm_Flag_Frnt 0 "Positive" 1 "Negative" ;
VAL_ 2244048385 RCU_AD3_TCS_MtrTrgtRpm_Flag_Rear 0 "Positive" 1 "Negative" ;
VAL_ 2244048385 RCU_AD3_WSSmode 0 "Not support" 1 "RCU support mode" ;
VAL_ 2244048386 RCU_AD3_Wss2FlFltSta 0 "No Fault" 1 "Fault" 2 "Not used" 3 "Error Indicator" ;
VAL_ 2244048386 RCU_AD3_DiagSta 0 "RCU is not diagnostic mode" 1 "RCU is diagnostic mode" 2 "Not used" 3 "Error Indicator" ;
VAL_ 2244048386 RCU_AD3_PrsrValVldSta 0 "Normal" 1 "Fail" 2 "RESERVED" 3 "Suspect" ;
VAL_ 2244048386 RCU_AD3_PrsrVal 4095 "Error" ;
VAL_ 2244048386 RCU_AD3_Wss2FrFltSta 0 "No Fault" 1 "Fault" 2 "Not used" 3 "Error Indicator" ;
VAL_ 2244048386 RCU_AD3_ABS_DfctvSta 0 "RCU ABS function is not defective" 1 "RCU ABS function is defective" 2 "Not used" 3 "Error Indicator" ;
VAL_ 2244048386 RCU_AD3_ABS_ActvSta 0 "RCU ABS control inactive" 1 "RCU ABS control active" 2 "Not used" 3 "Error Indicator" ;
VAL_ 2244048386 RCU_AD3_BBC_DfctvSta 0 "RCU BBC function is not defective" 1 "RCU BBC function is defective" 2 "Not used" 3 "Error Indicator" ;
VAL_ 2244048386 RCU_AD3_BBC_ActvSta 0 "RCU BBC control inactive" 1 "RCU BBC control active" 2 "Not used" 3 "Error Indicator" ;
VAL_ 2244048386 RCU_AD3_Wss2RlFltSta 0 "No Fault" 1 "Fault" 2 "Not used" 3 "Error Indicator" ;
VAL_ 2244048386 RCU_AD3_BrkLtActSta 0 "No request" 1 "RCU Activate brake lights" 2 "Not used" 3 "Error Indicator" ;
VAL_ 2244048386 RCU_AD3_DrvOvrdSta 0 "No override" 1 "Override by acceleration pedal" 2 "Override by deceleration" 3 "Error Indicator" ;
VAL_ 2244048386 RCU_AD3_PrkBrkActvSta 0 "RCU Parking brake is not activated" 1 "RCU Parking brake is activated" 2 "Not used" 3 "Error Indicator" ;
VAL_ 2244048386 RCU_AD3_FCA_AvlblSta 0 "Available" 1 "Temporarily not available" 2 "Permanently not available" 3 "FCA Communication Error" ;
VAL_ 2244048386 RCU_AD3_Wss2RrFltSta 0 "No Fault" 1 "Fault" 2 "Not used" 3 "Error Indicator" ;
VAL_ 2244048386 RCU_AD3_SrvLmpDis 0 "RCU Service Lamp is Off" 1 "RCU Service Lamp is On" 2 "RCU Service Lamp is BLINKING(2HZ)" 3 "error indicator" ;
VAL_ 2244048387 RCU_AD3_TCS_TqFlag 0 "Positive" 1 "Negative" ;
VAL_ 2244048387 RCU_AD3_TCS_Sta 0 "Not Applied" 1 "Off" 2 "Ready" 3 "Activated" 4 "Reserved" 5 "Reserved" 6 "Reserved" 7 "Reserved" 8 "Reserved" 9 "Reserved" 10 "Reserved" 11 "Reserved" 12 "Reserved" 13 "Reserved" 14 "Not Coded" 15 "Defective" ;
VAL_ 2244048387 RCU_AD3_VehAccelVal 2047 "Error" ;
VAL_ 2244048387 RCU_AD3_MSR_TqFlag 0 "Positive" 1 "Negative" ;
VAL_ 2244048387 RCU_AD3_LDM_Sta 0 "RCU ready to DBFAVH (requested by switch)" 1 "RCU can¡¯t perform DBFAVH (requested by switch)" 2 "Not used" 3 "Error Indicator" ;
VAL_ 2244048387 RCU_AD3_ECD_ActvSta 0 "RCU ECD is not active" 1 "RCU ECD is active(operating)" 2 "Not used" 3 "Error Indicator" ;
VAL_ 2244048387 RCU_AD3_MSR_FuncReq 0 "Passive or RCU TCS function" 1 "RCU MSR control active" 2 "Not used" 3 "Error Indicator" ;
VAL_ 2244048387 RCU_AD3_TCS_Req 0 "Passive" 1 "RCU_TCS/ESC control active" 2 "Not used" 3 "Error Indicator" ;
VAL_ 2244048387 RCU_AD3_TCS_LmpSta 0 "RCU_TCSESC FunctionWarning Lamp OFF" 1 "RCU_TCSESC FunctionWarning Lamp ON" 2 "RCU_TCSESC FunctionWarning Lamp BLINKING(2Hz)" 3 "Error Indicator" ;
VAL_ 2244048387 RCU_AD3_SCC_TqReq 0 "No request" 1 "Enable SCC torque request" 2 "Not used" 3 "Error Indicator" ;
VAL_ 2244048387 RCU_AD3_StdStillVal 0 "No stand still detected" 1 "stand still detected" 2 "Not used" 3 "Error Indicator" ;
VAL_ 2244048387 RCU_AD3_SCC_ReqLimSta 0 "No request" 1 "Limited No Limitation" 2 "Acceleration Limited" 3 "Deceleration Limited" ;
VAL_ 2244048387 RCU_AD3_SCC_OptTyp 0 "RCU_SCC is not equipped" 1 "RCU_SCC is equipped" 2 "Not used" 3 "Not Coded" ;
VAL_ 2244048387 RCU_AD3_SCC_EnblReq 0 "RCU_SCC enabled" 1 "RCU_SCC disabled reversible" 2 "RCU_SCC disabled irreversible" 3 "RCU_SCC disabled irreversible due to communication error" ;
VAL_ 2244048387 RCU_AD3_FCA_EquipSta 0 "RCU_FCA is not equipped" 1 "RCU_FCA is equipped" 2 "Not used" 3 "Not Coded" ;
VAL_ 2244048387 RCU_AD3_FCA_ActvSta 0 "RCU_FCA Brake is not in activation" 1 "RCU_FCA Pre-Brake" 2 "RCU_FCA Full-Brake" 3 "Invalid" ;
VAL_ 2244048387 RCU_AD3_DclEnblReq 0 "Disable deceleration control" 1 "Enable deceleration control" 2 "Not used" 3 "Error Indicator" ;
VAL_ 2244048387 RCU_AD3_DBS_ActvSta 0 "RCU_DBS control is inactive" 1 "RCU_DBS control is active" 2 "Not used" 3 "Not used" ;
VAL_ 2244048387 RCU_AD3_AccelBasisVal 2047 "Error" ;
VAL_ 2244048388 RCU_HDPSpprtSWVer 0 "Not Supported" 1 "SW Version" 2 "SW Version" 3 "SW Version" 4 "SW Version" 5 "SW Version" 6 "SW Version" 7 "SW Version" 8 "SW Version" 9 "SW Version" 10 "SW Version" 11 "SW Version" 12 "SW Version" 13 "SW Version" 14 "SW Version" 15 "SW Version" 16 "SW Version" 17 "SW Version" 18 "SW Version" 19 "SW Version" 20 "SW Version" 21 "SW Version" 22 "SW Version" 23 "SW Version" 24 "SW Version" 25 "SW Version" 26 "SW Version" 27 "SW Version" 28 "SW Version" 29 "SW Version" 30 "SW Version" 31 "SW Version" ;
VAL_ 2244048388 RCU_RegenTqLimitNmVal_Rear 0 "0x0x0000~0xFFFF:Real Values" 65535 "0x0x0000~0xFFFF:Real Values" ;
VAL_ 2244048388 RCU_AD3_TCS_TqIntrvntnVal_Frnt 0 "0x0x00~0xFF:Real Values" 255 "0x0x00~0xFF:Real Values" ;
VAL_ 2244048388 RCU_AD3_TCS_MtrTrgtRpm_Frnt 0 "0x0x000~0xFFE:Motor RPM Target" 4094 "0x0x000~0xFFE:Motor RPM Target" 4095 "Error Value" ;
VAL_ 2244048388 RCU_AD3_TCS_TqFlag_Frnt 0 "Positive" 1 "Negative" ;
VAL_ 2244048388 RCU_AD3_TCS_MtrTrgtRpm_Rear 0 "0x0x000~0xFFE:Motor RPM Target" 4094 "0x0x000~0xFFE:Motor RPM Target" 4095 "Error Value" ;
VAL_ 2244048388 RCU_AD3_ABS_WrngLmpSta 0 "RCU ABS Warning lamp OFF" 1 "RCU ABS Warning lamp ON" 2 "RESERVED" 3 "Error Indicator" ;
VAL_ 2244048388 RCU_AD3_ESC_Sta 0 "Not Applied" 1 "Off" 2 "Ready" 3 "Activated" 4 "RESERVED" 5 "RESERVED" 6 "RESERVED" 7 "RESERVED" 8 "RESERVED" 9 "RESERVED" 10 "RESERVED" 11 "RESERVED" 12 "RESERVED" 13 "RESERVED" 14 "Not Coded" 15 "Defective" ;
